VERSION ""

NS_ :

BS_:

BU_: VDM CMR_DSMC SOBDMC_HPCM_FD1 IPMA_ADAS PSCM ABS_ESC TCCM TCM_DSL PCM_HEV PCM ECM_Diesel GENERIC_GWMWakeup GWM _delete TSTR

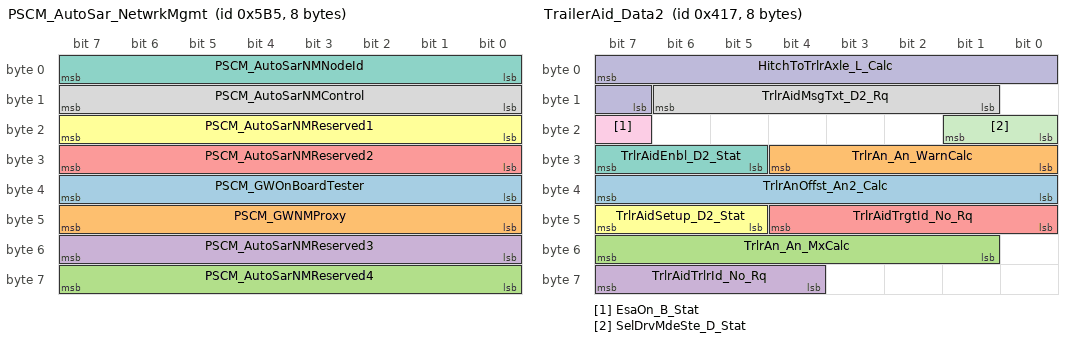
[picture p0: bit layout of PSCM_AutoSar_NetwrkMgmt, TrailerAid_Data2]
BO_ 1461 PSCM_AutoSar_NetwrkMgmt: 8 PSCM
 SG_ PSCM_GWOnBoardTester : 39|8@0+ (1,0) [0|255] "unitless"  GWM,ABS_ESC
 SG_ PSCM_GWNMProxy : 47|8@0+ (1,0) [0|255] "unitless"  GWM,ABS_ESC
 SG_ PSCM_AutoSarNMReserved4 : 63|8@0+ (1,0) [0|255] "unitless"  GWM,ABS_ESC
 SG_ PSCM_AutoSarNMReserved3 : 55|8@0+ (1,0) [0|255] "unitless"  GWM,ABS_ESC
 SG_ PSCM_AutoSarNMReserved2 : 31|8@0+ (1,0) [0|255] "unitless"  GWM,ABS_ESC
 SG_ PSCM_AutoSarNMReserved1 : 23|8@0+ (1,0) [0|255] "unitless"  GWM,ABS_ESC
 SG_ PSCM_AutoSarNMNodeId : 7|8@0+ (1,0) [0|255] "unitless"  GWM,ABS_ESC
 SG_ PSCM_AutoSarNMControl : 15|8@0+ (1,0) [0|255] "unitless"  GWM,ABS_ESC

BO_ 1047 TrailerAid_Data2: 8 PSCM
 SG_ TrlrAnOffst_An2_Calc : 39|8@0+ (0.5,-64) [-64|63.5] "degrees"  IPMA_ADAS
 SG_ TrlrAn_An_WarnCalc : 28|5@0+ (1,0) [0|31] "degrees"  IPMA_ADAS
 SG_ TrlrAn_An_MxCalc : 55|7@0+ (1,0) [0|127] "degrees"  IPMA_ADAS
 SG_ TrlrAidTrlrId_No_Rq : 63|4@0+ (1,0) [0|15] "unitless"  GWM
 SG_ TrlrAidTrgtId_No_Rq : 44|5@0+ (1,0) [0|31] "unitless"  IPMA_ADAS
 SG_ TrlrAidSetup_D2_Stat : 47|3@0+ (1,0) [0|7] "SED"  IPMA_ADAS
 SG_ TrlrAidEnbl_D2_Stat : 31|3@0+ (1,0) [0|7] "SED"  PCM_HEV,ABS_ESC,IPMA_ADAS,GWM,PCM,ECM_Diesel
 SG_ TrlrAidMsgTxt_D2_Rq : 14|6@0+ (1,0) [0|63] "SED"  IPMA_ADAS,GWM,ABS_ESC
 SG_ EsaOn_B_Stat : 23|1@0+ (1,0) [0|1] "SED"  GWM
 SG_ HitchToTrlrAxle_L_Calc : 7|9@0+ (0.0254,0) [0|12.9794] "meter"  IPMA_ADAS
 SG_ SelDrvMdeSte_D_Stat : 17|2@0+ (1,0) [0|3] "SED"  ABS_ESC

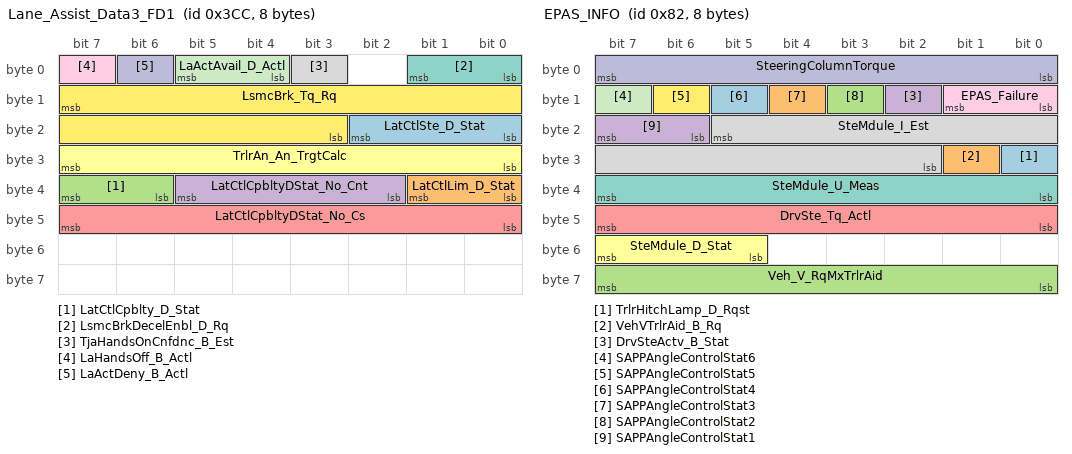
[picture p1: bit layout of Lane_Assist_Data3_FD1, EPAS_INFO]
BO_ 972 Lane_Assist_Data3_FD1: 8 PSCM
 SG_ LatCtlSte_D_Stat : 18|3@0+ (1,0) [0|7] "SED"  IPMA_ADAS,GWM
 SG_ LatCtlLim_D_Stat : 33|2@0+ (1,0) [0|3] "SED"  IPMA_ADAS,GWM
 SG_ LatCtlCpblty_D_Stat : 39|2@0+ (1,0) [0|3] "SED"  IPMA_ADAS,GWM
 SG_ LatCtlCpbltyDStat_No_Cnt : 37|4@0+ (1,0) [0|15] "Unitless"  IPMA_ADAS,GWM
 SG_ LatCtlCpbltyDStat_No_Cs : 47|8@0+ (1,0) [0|255] "Unitless"  IPMA_ADAS,GWM
 SG_ TrlrAn_An_TrgtCalc : 31|8@0+ (1,-128) [-128|127] "degrees"  IPMA_ADAS
 SG_ LsmcBrkDecelEnbl_D_Rq : 1|2@0+ (1,0) [0|3] "SED"  ABS_ESC
 SG_ TjaHandsOnCnfdnc_B_Est : 3|1@0+ (1,0) [0|1] "SED"  IPMA_ADAS
 SG_ LaHandsOff_B_Actl : 7|1@0+ (1,0) [0|1] "SED"  IPMA_ADAS,GWM
 SG_ LaActDeny_B_Actl : 6|1@0+ (1,0) [0|1] "SED"  IPMA_ADAS,GWM
 SG_ LaActAvail_D_Actl : 5|2@0+ (1,0) [0|3] "SED"  IPMA_ADAS,GWM
 SG_ LsmcBrk_Tq_Rq : 15|13@0+ (4,0) [0|32764] "Nm"  ABS_ESC

BO_ 130 EPAS_INFO: 8 PSCM
 SG_ TrlrHitchLamp_D_Rqst : 24|1@0+ (1,0) [0|1] "SED"  IPMA_ADAS,GWM
 SG_ VehVTrlrAid_B_Rq : 25|1@0+ (1,0) [0|1] "SED"  PCM_HEV,GWM,ECM_Diesel,PCM
 SG_ Veh_V_RqMxTrlrAid : 63|8@0+ (0.1,0) [0|25.5] "km/h"  PCM_HEV,GWM,ECM_Diesel,PCM
 SG_ DrvSteActv_B_Stat : 10|1@0+ (1,0) [0|1] "SED"  GWM,ABS_ESC
 SG_ DrvSte_Tq_Actl : 47|8@0+ (0.0625,-8) [-8|7.8125] "Nm"  GWM,ABS_ESC
 SG_ SteMdule_D_Stat : 55|3@0+ (1,0) [0|7] "SED"  GWM
 SG_ SteMdule_U_Meas : 39|8@0+ (0.05,6) [6|18.7] "Volts"  GWM
 SG_ SteMdule_I_Est : 21|12@0+ (0.05,-64) [-64|140.7] "Amps"  GWM
 SG_ EPAS_Failure : 9|2@0+ (1,0) [0|3] "SED"  IPMA_ADAS,GWM
 SG_ SteeringColumnTorque : 7|8@0+ (0.0625,-8) [-8|7.8125] "Nm"  GWM,IPMA_ADAS,ABS_ESC
 SG_ SAPPAngleControlStat6 : 15|1@0+ (1,0) [0|1] "SED"  GWM,IPMA_ADAS
 SG_ SAPPAngleControlStat5 : 14|1@0+ (1,0) [0|1] "SED"  GWM,IPMA_ADAS
 SG_ SAPPAngleControlStat4 : 13|1@0+ (1,0) [0|1] "SED"  GWM,IPMA_ADAS
 SG_ SAPPAngleControlStat3 : 12|1@0+ (1,0) [0|1] "SED"  GWM,IPMA_ADAS
 SG_ SAPPAngleControlStat2 : 11|1@0+ (1,0) [0|1] "SED"  GWM,IPMA_ADAS
 SG_ SAPPAngleControlStat1 : 23|2@0+ (1,0) [0|3] "SED"  GWM,IPMA_ADAS

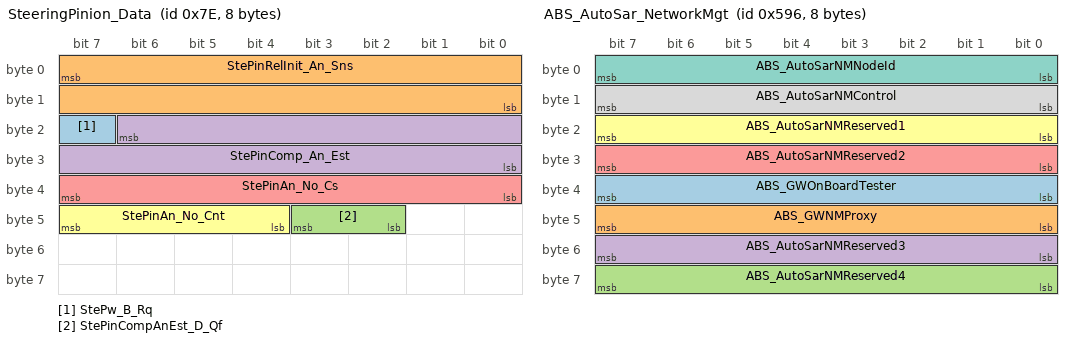
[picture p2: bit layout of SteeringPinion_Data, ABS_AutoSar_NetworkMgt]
BO_ 126 SteeringPinion_Data: 8 PSCM
 SG_ StePw_B_Rq : 23|1@0+ (1,0) [0|1] "SED"  GWM,ECM_Diesel,PCM
 SG_ StePinRelInit_An_Sns : 7|16@0+ (0.1,-3200) [-3200|3353.3] "degrees"  VDM,IPMA_ADAS,GWM,ECM_Diesel,PCM,PCM_HEV,ABS_ESC,TCCM
 SG_ StePinCompAnEst_D_Qf : 43|2@0+ (1,0) [0|3] "SED"  VDM,CMR_DSMC,IPMA_ADAS,TCM_DSL,ECM_Diesel,PCM,PCM_HEV,ABS_ESC,TCCM,GWM
 SG_ StePinComp_An_Est : 22|15@0+ (0.1,-1600) [-1600|1676.7] "degrees"  VDM,CMR_DSMC,IPMA_ADAS,TCM_DSL,ECM_Diesel,PCM,PCM_HEV,ABS_ESC,TCCM,GWM
 SG_ StePinAn_No_Cs : 39|8@0+ (1,0) [0|255] "Unitless"  VDM,ABS_ESC,TCCM,GWM
 SG_ StePinAn_No_Cnt : 47|4@0+ (1,0) [0|15] "unitless"  VDM,TCCM,GWM,ABS_ESC

BO_ 1430 ABS_AutoSar_NetworkMgt: 8 ABS_ESC
 SG_ ABS_GWOnBoardTester : 39|8@0+ (1,0) [0|255] "unitless"  GWM
 SG_ ABS_GWNMProxy : 47|8@0+ (1,0) [0|255] "unitless"  GWM
 SG_ ABS_AutoSarNMReserved4 : 63|8@0+ (1,0) [0|255] "unitless"  GWM
 SG_ ABS_AutoSarNMReserved3 : 55|8@0+ (1,0) [0|255] "unitless"  GWM
 SG_ ABS_AutoSarNMReserved2 : 31|8@0+ (1,0) [0|255] "unitless"  GWM
 SG_ ABS_AutoSarNMReserved1 : 23|8@0+ (1,0) [0|255] "unitless"  GWM
 SG_ ABS_AutoSarNMNodeId : 7|8@0+ (1,0) [0|255] "unitless"  GWM
 SG_ ABS_AutoSarNMControl : 15|8@0+ (1,0) [0|255] "unitless"  GWM

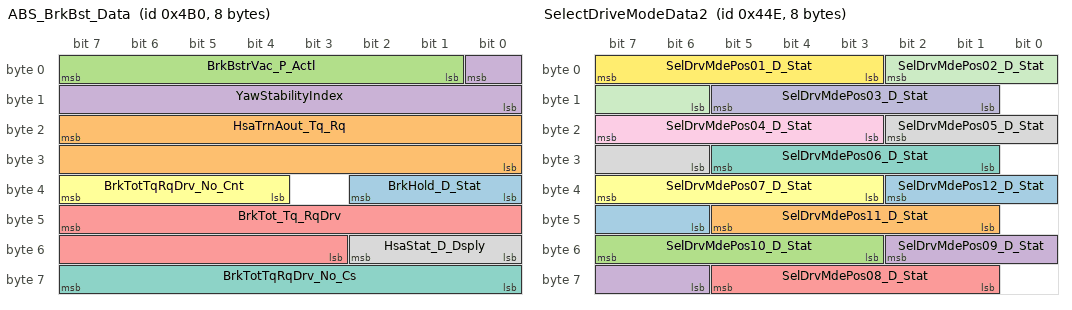
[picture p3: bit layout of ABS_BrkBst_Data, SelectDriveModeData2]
BO_ 1200 ABS_BrkBst_Data: 8 ABS_ESC
 SG_ BrkHold_D_Stat : 34|3@0+ (1,0) [0|7] "SED"  ECM_Diesel,GWM,IPMA_ADAS,PCM,PCM_HEV
 SG_ HsaTrnAout_Tq_Rq : 23|16@0+ (4,-131072) [-131072|131060] "Nm"  GWM
 SG_ BrkBstrVac_P_Actl : 7|7@0+ (8,0) [0|1008] "Millibar"  ECM_Diesel,PCM,PCM_HEV,GWM
 SG_ YawStabilityIndex : 0|9@0+ (1,-256) [-256|255] "%"  VDM,IPMA_ADAS,PSCM,GWM
 SG_ BrkTot_Tq_RqDrv : 47|13@0+ (4,0) [0|32760] "Nm"  IPMA_ADAS,ECM_Diesel,PCM,PCM_HEV,GWM,TCCM,PSCM
 SG_ BrkTotTqRqDrv_No_Cnt : 39|4@0+ (1,0) [0|15] "unitless"  ECM_Diesel,PCM,PCM_HEV,GWM
 SG_ BrkTotTqRqDrv_No_Cs : 63|8@0+ (1,0) [0|255] "unitless"  ECM_Diesel,PCM,PCM_HEV,GWM
 SG_ HsaStat_D_Dsply : 50|3@0+ (1,0) [0|7] "SED"  GWM

BO_ 1102 SelectDriveModeData2: 8 ABS_ESC
 SG_ SelDrvMdePos12_D_Stat : 34|5@0+ (1,0) [0|31] "SED"  GWM
 SG_ SelDrvMdePos11_D_Stat : 45|5@0+ (1,0) [0|31] "SED"  GWM
 SG_ SelDrvMdePos10_D_Stat : 55|5@0+ (1,0) [0|31] "SED"  GWM
 SG_ SelDrvMdePos09_D_Stat : 50|5@0+ (1,0) [0|31] "SED"  GWM
 SG_ SelDrvMdePos08_D_Stat : 61|5@0+ (1,0) [0|31] "SED"  GWM
 SG_ SelDrvMdePos07_D_Stat : 39|5@0+ (1,0) [0|31] "SED"  GWM
 SG_ SelDrvMdePos06_D_Stat : 29|5@0+ (1,0) [0|31] "SED"  GWM
 SG_ SelDrvMdePos05_D_Stat : 18|5@0+ (1,0) [0|31] "SED"  GWM
 SG_ SelDrvMdePos04_D_Stat : 23|5@0+ (1,0) [0|31] "SED"  GWM
 SG_ SelDrvMdePos03_D_Stat : 13|5@0+ (1,0) [0|31] "SED"  GWM
 SG_ SelDrvMdePos02_D_Stat : 2|5@0+ (1,0) [0|31] "SED"  GWM
 SG_ SelDrvMdePos01_D_Stat : 7|5@0+ (1,0) [0|31] "SED"  GWM

BO_ 1056 SelectDriveModeData: 8 ABS_ESC
 SG_ SelDrvMdeHmi03_D_Rq : 12|5@0+ (1,0) [0|31] "SED"  GWM
 SG_ AutoEpbMsgTxt_D_Rq : 58|3@0+ (1,0) [0|7] "SED"  GWM
 SG_ AutoEpbDsply_D_Stat : 37|2@0+ (1,0) [0|3] "SED"  GWM
 SG_ AutoEpbButtnOn_B_Stat : 48|1@0+ (1,0) [0|1] "SED"  GWM
 SG_ SelDrvMdePos12_B_Avail : 54|1@0+ (1,0) [0|1] "SED"  GWM
 SG_ SelDrvMdePos11_B_Avail : 55|1@0+ (1,0) [0|1] "SED"  GWM
 SG_ SelDrvMdePos10_B_Avail : 40|1@0+ (1,0) [0|1] "SED"  GWM
 SG_ SelDrvMdePos09_B_Avail : 41|1@0+ (1,0) [0|1] "SED"  GWM
 SG_ SelDrvMdePos08_B_Avail : 42|1@0+ (1,0) [0|1] "SED"  GWM
 SG_ SelDrvMdePos07_B_Avail : 43|1@0+ (1,0) [0|1] "SED"  GWM
 SG_ SelDrvMdePos06_B_Avail : 44|1@0+ (1,0) [0|1] "SED"  GWM
 SG_ SelDrvMdePos05_B_Avail : 45|1@0+ (1,0) [0|1] "SED"  GWM
 SG_ SelDrvMdePos04_B_Avail : 46|1@0+ (1,0) [0|1] "SED"  GWM
 SG_ SelDrvMdePos03_B_Avail : 47|1@0+ (1,0) [0|1] "SED"  GWM
 SG_ SelDrvMdePos02_B_Avail : 32|1@0+ (1,0) [0|1] "SED"  GWM
 SG_ SelDrvMdePos01_B_Avail : 24|1@0+ (1,0) [0|1] "SED"  GWM
 SG_ ActvDrvMde_D2_Stat : 53|5@0+ (1,0) [0|31] "SED"  IPMA_ADAS,GWM
 SG_ SelDrvMde_D2_Rq : 63|5@0+ (1,0) [0|31] "SED"  GWM
 SG_ SelDrvMdePt_D_Rq : 31|5@0+ (1,0) [0|31] "SED"  ECM_Diesel,PCM,PCM_HEV,GWM
 SG_ SelDrvMdeMsgTxt_D_Rq : 19|4@0+ (1,0) [0|15] "SED"  TCCM,GWM
 SG_ SelDrvMde_D_Stat : 26|2@0+ (1,0) [0|3] "SED"  GWM
 SG_ AwdMde_D_RqBrk : 35|3@0+ (1,0) [0|7] "SED"  GWM

BO_ 1054 BrakeSysFeatures_3: 8 ABS_ESC
 SG_ TrailOnePdlTqLm_B_Actl : 56|1@0+ (1,0) [0|1] "SED"  PCM,GWM
 SG_ SelDrvMdeChassis3_D_Rq : 61|5@0+ (1,0) [0|31] "SED"  GWM
 SG_ AirDamUp_B_RqBrk : 32|1@0+ (1,0) [0|1] "SED"  ECM_Diesel,PCM_HEV,PCM
 SG_ RbaBrk_D_Stat : 63|2@0+ (1,0) [0|3] "SED"  IPMA_ADAS,GWM
 SG_ SelDrvMdeChassis2_D_Rq : 45|5@0+ (1,0) [0|31] "SED"  PSCM,GWM
 SG_ TrailCtl_D_Stat : 55|3@0+ (1,0) [0|7] "SED"  TCCM,PCM,GWM
 SG_ TrailCtlMsgTxt_D_Rq : 52|4@0+ (1,0) [0|15] "SED"  GWM
 SG_ BrkBstrVac_D_Stat : 18|2@0+ (1,0) [0|3] "SED"  ECM_Diesel,PCM,PCM_HEV,GWM
 SG_ DrvSlipCtlOffLamp_D_Rq : 23|2@0+ (1,0) [0|3] "SED"  GWM
 SG_ DrvSlipCtlMdeMsg_D_Rq : 13|5@0+ (1,0) [0|31] "SED"  GWM
 SG_ AutoHoldMsgTxt_D_Rq : 4|4@0+ (1,0) [0|15] "SED"  GWM
 SG_ CtaBrk_D_Stat : 47|2@0+ (1,0) [0|3] "SED"  IPMA_ADAS,GWM
 SG_ SelDrvMdeAwd_D_Rq : 29|5@0+ (1,0) [0|31] "SED"  TCCM,GWM
 SG_ AutoHoldSwMde_B_Ind : 0|1@0+ (1,0) [0|1] "SED"  GWM
 SG_ AutoHoldMde_D_Ind : 15|2@0+ (1,0) [0|3] "SED"  GWM
 SG_ SelDrvMdeChassis_D_Rq : 39|5@0+ (1,0) [0|31] "SED"  VDM,GWM
 SG_ ApaBrk_D_Stat : 34|2@0+ (1,0) [0|3] "SED"  ECM_Diesel,IPMA_ADAS,PCM,PCM_HEV,GWM

BO_ 1046 BrakeSysFeatures_2: 8 ABS_ESC
 SG_ HsaMde_D_Mem : 33|2@0+ (1,0) [0|3] "SED"  GWM
 SG_ BrkBstrVac_B_Rq : 27|1@0+ (1,0) [0|1] "Discrete"  ECM_Diesel,PCM,PCM_HEV,GWM
 SG_ HdcMde_D_Actl : 31|3@0+ (1,0) [0|7] "SED"  PCM,PCM_HEV,GWM
 SG_ RearDiffLck_Tq2_RqMx : 51|12@0+ (4,0) [0|16376] "Nm"  GWM
 SG_ TRLR_SWAY_EVNT_IN_PROG : 25|1@0+ (1,0) [0|1] "SED"  GWM
 SG_ TRLR_SWAY_CONFIG_STAT : 26|1@0+ (1,0) [0|1] "SED"  GWM
 SG_ TCMode : 15|1@0+ (1,0) [0|1] "SED"  VDM,IPMA_ADAS,ECM_Diesel,PCM,PCM_HEV,GWM
 SG_ DrvSlipCtlLamp_D_Rq : 42|2@0+ (1,0) [0|3] "SED"  VDM,IPMA_ADAS,ECM_Diesel,PCM,PCM_HEV,GWM
 SG_ Abs_B_Falt : 5|1@0+ (1,0) [0|1] "SED"  ECM_Diesel,PCM,PCM_HEV,GWM
 SG_ DrvSlipCtlMde_D_Ind : 44|2@0+ (1,0) [0|3] "SED"  TCCM,IPMA_ADAS,ECM_Diesel,PCM,PCM_HEV,GWM
 SG_ DrvAntiLckLamp_D_Rq : 55|2@0+ (1,0) [0|3] "SED"  ECM_Diesel,GWM,IPMA_ADAS
 SG_ BpedMove_No_Cnt : 3|4@0+ (1,0) [0|15] "Unitless"  ECM_Diesel,GWM
 SG_ StabCtlBrk_B_Avail : 4|1@0+ (1,0) [0|1] "SED"  VDM,TCCM,GWM
 SG_ DrvHdcWarnInfo_D_Rq : 35|2@0+ (1,0) [0|3] "SED"  GWM
 SG_ DrvHdcMsg_D_Rq : 10|3@0+ (1,0) [0|7] "SED"  GWM
 SG_ DrvHdcLampInfo_D_Rq : 12|2@0+ (1,0) [0|3] "SED"  GWM
 SG_ BpedMove_D_Actl : 7|2@0+ (1,0) [0|3] "SED"  ECM_Diesel,GWM
 SG_ ChimeBrk_B_Rq : 14|1@0+ (1,0) [0|1] "SED"  GWM
 SG_ BrkLamp_B_Rq : 13|1@0+ (1,0) [0|1] "SED"  GWM
 SG_ HILL_DESC_MC : 47|3@0+ (1,0) [0|7] "SED"  GWM
 SG_ RearDiffElckrOpen_B_Rq : 40|1@0+ (1,0) [0|1] "SED"  GWM,TCCM

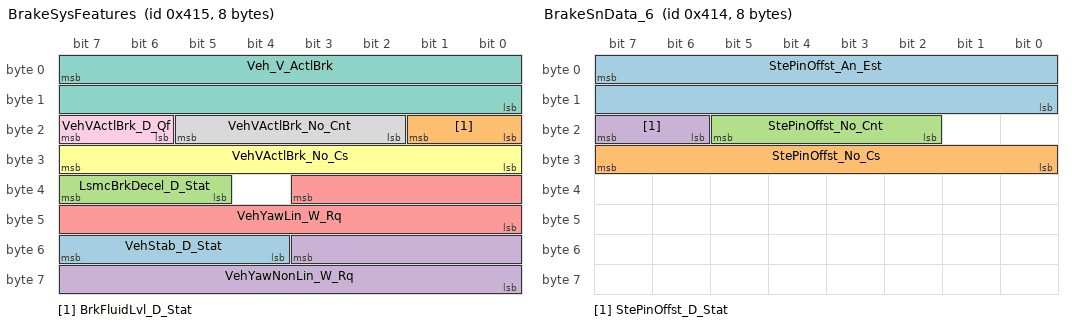
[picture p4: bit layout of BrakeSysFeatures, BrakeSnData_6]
BO_ 1045 BrakeSysFeatures: 8 ABS_ESC
 SG_ VehStab_D_Stat : 55|4@0+ (1,0) [0|15] "SED"  TCCM,PCM_HEV,PCM,GWM
 SG_ BrkFluidLvl_D_Stat : 17|2@0+ (1,0) [0|3] "SED"  GWM
 SG_ LsmcBrkDecel_D_Stat : 39|3@0+ (1,0) [0|7] "SED"  PSCM,GWM
 SG_ VehYawNonLin_W_Rq : 51|12@0+ (0.03663,-75) [-75|74.92659] "deg/s"  ECM_Diesel,GWM
 SG_ VehYawLin_W_Rq : 35|12@0+ (0.03663,-75) [-75|74.92659] "deg/s"  ECM_Diesel,GWM
 SG_ VehVActlBrk_No_Cs : 31|8@0+ (1,0) [0|255] "Unitless"  TCCM,CMR_DSMC,SOBDMC_HPCM_FD1,ECM_Diesel,PCM,PCM_HEV,PSCM,TCM_DSL,GWM,IPMA_ADAS
 SG_ Veh_V_ActlBrk : 7|16@0+ (0.01,0) [0|655.35] "kph"  TCCM,CMR_DSMC,SOBDMC_HPCM_FD1,IPMA_ADAS,ECM_Diesel,PCM,PCM_HEV,PSCM,TCM_DSL,GWM
 SG_ VehVActlBrk_No_Cnt : 21|4@0+ (1,0) [0|15] "Unitless"  TCCM,CMR_DSMC,SOBDMC_HPCM_FD1,ECM_Diesel,PCM,PCM_HEV,PSCM,TCM_DSL,GWM,IPMA_ADAS
 SG_ VehVActlBrk_D_Qf : 23|2@0+ (1,0) [0|3] "SED"  TCCM,CMR_DSMC,SOBDMC_HPCM_FD1,IPMA_ADAS,ECM_Diesel,PCM,PCM_HEV,PSCM,TCM_DSL,GWM

BO_ 1044 BrakeSnData_6: 8 ABS_ESC
 SG_ StePinOffst_An_Est : 7|16@0+ (0.1,-3200) [-3200|3353.3] "degrees"  GWM,PSCM
 SG_ StePinOffst_No_Cs : 31|8@0+ (1,0) [0|255] "Unitless"  GWM,PSCM
 SG_ StePinOffst_No_Cnt : 21|4@0+ (1,0) [0|15] "unitless"  GWM,PSCM
 SG_ StePinOffst_D_Stat : 23|2@0+ (1,0) [0|3] "SED"  GWM,PSCM

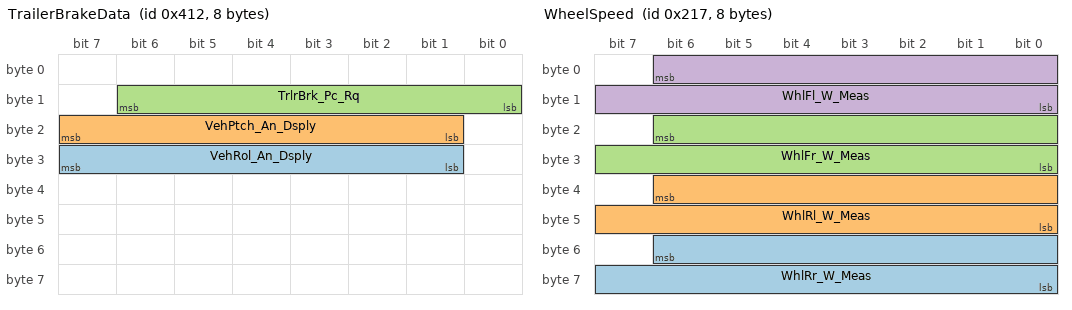
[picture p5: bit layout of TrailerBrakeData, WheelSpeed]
BO_ 1042 TrailerBrakeData: 8 ABS_ESC
 SG_ VehRol_An_Dsply : 31|7@0+ (1,-64) [-64|61] "degrees"  GWM
 SG_ VehPtch_An_Dsply : 23|7@0+ (1,-64) [-64|61] "degrees"  GWM,TCCM
 SG_ TrlrBrk_Pc_Rq : 14|7@0+ (1,0) [0|127] "percent"  GWM

BO_ 535 WheelSpeed: 8 ABS_ESC
 SG_ WhlRr_W_Meas : 54|15@0+ (0.01,0) [0|327.65] "rad/s"  VDM,IPMA_ADAS,GWM,ECM_Diesel,PCM,PCM_HEV,PSCM,TCCM,TCM_DSL
 SG_ WhlRl_W_Meas : 38|15@0+ (0.01,0) [0|327.65] "rad/s"  VDM,IPMA_ADAS,GWM,ECM_Diesel,PCM,PCM_HEV,PSCM,TCCM,TCM_DSL
 SG_ WhlFr_W_Meas : 22|15@0+ (0.01,0) [0|327.65] "rad/s"  VDM,IPMA_ADAS,GWM,ECM_Diesel,PCM,PCM_HEV,PSCM,TCCM,TCM_DSL
 SG_ WhlFl_W_Meas : 6|15@0+ (0.01,0) [0|327.65] "rad/s"  VDM,IPMA_ADAS,GWM,ECM_Diesel,PCM,PCM_HEV,PSCM,TCCM,TCM_DSL

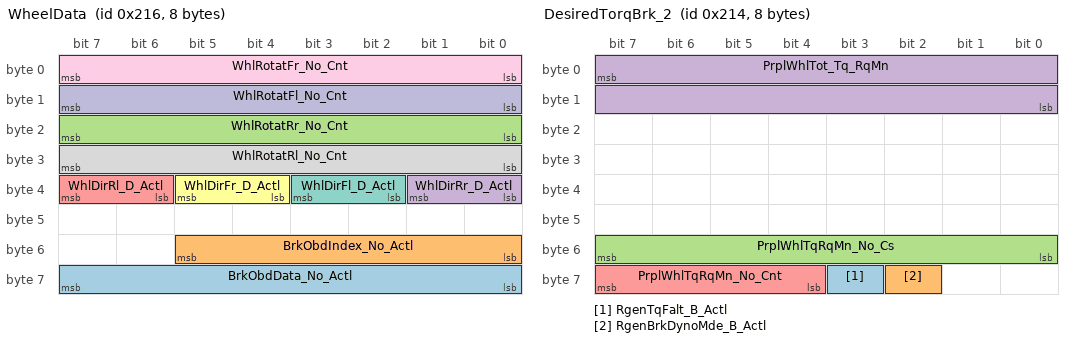
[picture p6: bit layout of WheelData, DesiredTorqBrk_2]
BO_ 534 WheelData: 8 ABS_ESC
 SG_ BrkObdData_No_Actl : 63|8@0+ (1,0) [0|255] "unitless"  SOBDMC_HPCM_FD1,GWM
 SG_ BrkObdIndex_No_Actl : 53|6@0+ (1,0) [0|63] "unitless"  SOBDMC_HPCM_FD1,GWM
 SG_ WhlRotatRr_No_Cnt : 23|8@0+ (1,0) [0|255] "Unitless"  IPMA_ADAS,GWM,PSCM
 SG_ WhlDirRr_D_Actl : 33|2@0+ (1,0) [0|3] "SED"  PCM,IPMA_ADAS,GWM,ECM_Diesel,PCM_HEV,PSCM
 SG_ WhlDirRl_D_Actl : 39|2@0+ (1,0) [0|3] "SED"  PCM,IPMA_ADAS,GWM,PSCM,ECM_Diesel,PCM_HEV
 SG_ WhlDirFr_D_Actl : 37|2@0+ (1,0) [0|3] "SED"  PCM,IPMA_ADAS,GWM,ECM_Diesel,PCM_HEV,PSCM
 SG_ WhlDirFl_D_Actl : 35|2@0+ (1,0) [0|3] "SED"  PCM,IPMA_ADAS,GWM,ECM_Diesel,PCM_HEV,PSCM
 SG_ WhlRotatRl_No_Cnt : 31|8@0+ (1,0) [0|255] "Unitless"  IPMA_ADAS,GWM,PSCM
 SG_ WhlRotatFr_No_Cnt : 7|8@0+ (1,0) [0|255] "Unitless"  IPMA_ADAS,GWM,PSCM
 SG_ WhlRotatFl_No_Cnt : 15|8@0+ (1,0) [0|255] "Unitless"  IPMA_ADAS,GWM,PSCM

BO_ 532 DesiredTorqBrk_2: 8 ABS_ESC
 SG_ RgenTqFalt_B_Actl : 59|1@0+ (1,0) [0|1] "SED"  GWM,PCM_HEV
 SG_ RgenBrkDynoMde_B_Actl : 58|1@0+ (1,0) [0|1] "SED"  GWM,PCM_HEV
 SG_ PrplWhlTqRqMn_No_Cs : 55|8@0+ (1,0) [0|255] "Unitless"  GWM,ECM_Diesel,PCM,PCM_HEV
 SG_ PrplWhlTot_Tq_RqMn : 7|16@0+ (4,-131072) [-131072|131068] "Nm"  GWM,ECM_Diesel,PCM,PCM_HEV
 SG_ PrplWhlTqRqMn_No_Cnt : 63|4@0+ (1,0) [0|15] "Unitless"  GWM,ECM_Diesel,PCM,PCM_HEV

BO_ 531 DesiredTorqBrk: 8 ABS_ESC
 SG_ VehStop_D_Stat : 28|2@0+ (1,0) [0|3] "SED"  IPMA_ADAS,GWM
 SG_ TracCtlPtActv_B_Actl : 31|1@0+ (1,0) [0|1] "SED"  VDM,IPMA_ADAS,TCCM,ECM_Diesel,PCM,PCM_HEV,TCM_DSL,GWM
 SG_ LscmbbMntr_B_Err : 17|1@0+ (1,0) [0|1] "SED"  GWM
 SG_ LscmbbBrkDis_B_Actl : 19|1@0+ (1,0) [0|1] "SED"  GWM
 SG_ LscmbbDeny_B_ActlBrk : 18|1@0+ (1,0) [0|1] "SED"  GWM
 SG_ PrkBrkYwLamp_D_Rq : 38|2@0+ (1,0) [0|3] "SED"  GWM
 SG_ PrkBrkRedLamp_D_Rq : 30|2@0+ (1,0) [0|3] "SED"  GWM
 SG_ LscmbbBrkDecel_B_Actl : 20|1@0+ (1,0) [0|1] "SED"  GWM
 SG_ AbsActv_B_Actl : 45|1@0+ (1,0) [0|1] "SED"  VDM,SOBDMC_HPCM_FD1,IPMA_ADAS,ECM_Diesel,PCM,PCM_HEV,TCM_DSL,PSCM,GWM
 SG_ StabCtlBrkActv_B_Actl : 23|1@0+ (1,0) [0|1] "SED"  VDM,IPMA_ADAS,PCM,PCM_HEV,TCM_DSL,PSCM,TCCM,ECM_Diesel,GWM
 SG_ CmbbBrkPrchg_B_Actl : 59|1@0+ (1,0) [0|1] "SED"  IPMA_ADAS,GWM
 SG_ CmbbBrkDecel_B_Actl : 58|1@0+ (1,0) [0|1] "SED"  IPMA_ADAS,GWM
 SG_ CmbbBaSensInc_B_Actl : 57|1@0+ (1,0) [0|1] "SED"  IPMA_ADAS,GWM
 SG_ AccBrkWarm_B_Actl : 63|1@0+ (1,0) [0|1] "SED"  IPMA_ADAS,GWM
 SG_ AccBrkTotTqMn_B_Actl : 62|1@0+ (1,0) [0|1] "SED"  IPMA_ADAS,GWM
 SG_ AccBrkPrchgActv_B_Actl : 61|1@0+ (1,0) [0|1] "SED"  IPMA_ADAS,GWM
 SG_ AccBrkDis_B_Actl : 44|1@0+ (1,0) [0|1] "SED"  IPMA_ADAS,GWM
 SG_ AccBrkDeny_B_Actl : 42|1@0+ (1,0) [0|1] "SED"  IPMA_ADAS,ECM_Diesel,PCM,PCM_HEV,GWM
 SG_ AccBrkActv_B_Actl : 43|1@0+ (1,0) [0|1] "SED"  IPMA_ADAS,ECM_Diesel,GWM
 SG_ PrplDrgCtlActv_B_Actl : 46|1@0+ (1,0) [0|1] "SED"  ECM_Diesel,PCM,PCM_HEV,TCM_DSL,GWM
 SG_ PrplWhlTot_Tq_RqMx : 7|16@0+ (4,-131072) [-131072|131068] "Nm"  ECM_Diesel,PCM,PCM_HEV,TCCM,GWM
 SG_ LscmbbBaSensInc_B_Actl : 21|1@0+ (1,0) [0|1] "SED"  GWM
 SG_ CmbbBrkDis_B_Actl : 56|1@0+ (1,0) [0|1] "SED"  IPMA_ADAS,PSCM,GWM
 SG_ CmbbDeny_B_ActlBrk : 60|1@0+ (1,0) [0|1] "SED"  IPMA_ADAS,PSCM,ECM_Diesel,PCM,PCM_HEV,GWM
 SG_ CcDis_B_Cmd : 47|1@0+ (1,0) [0|1] "SED"  PCM,PCM_HEV,GWM
 SG_ VehLongOvrGnd_A_Est : 41|10@0+ (0.035,-17.9) [-17.9|17.835] "m/s^2"  VDM,IPMA_ADAS,TCCM,GWM
 SG_ LscmbBrkPrchg_B_Actl : 16|1@0+ (1,0) [0|1] "SED"  GWM
 SG_ AccStopActv_B_ActlBrk : 22|1@0+ (1,0) [0|1] "SED"  IPMA_ADAS,ECM_Diesel,PCM,PCM_HEV,GWM
 SG_ AccDis_B_ActlEpb : 32|1@0+ (1,0) [0|1] "SED"  IPMA_ADAS,GWM
 SG_ PrkBrkMsgTxt_D_Rq : 36|4@0+ (1,0) [0|15] "SED"  GWM
 SG_ PrkBrkStatus : 26|3@0+ (1,0) [0|7] "SED"  IPMA_ADAS,ECM_Diesel,PCM,PCM_HEV,TCM_DSL,GWM

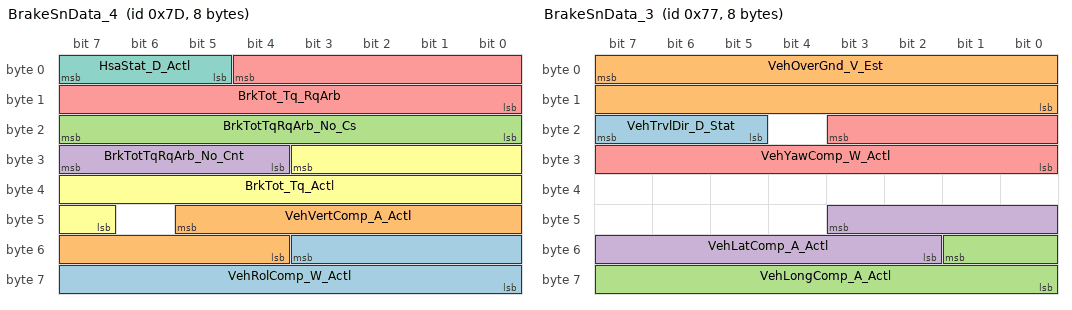
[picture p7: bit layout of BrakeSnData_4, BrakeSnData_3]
BO_ 125 BrakeSnData_4: 8 ABS_ESC
 SG_ VehRolComp_W_Actl : 51|12@0+ (0.03663,-75) [-75|74.92659] "degrees/sec"  VDM,GWM
 SG_ VehVertComp_A_Actl : 45|10@0+ (0.035,-17.9) [-17.9|17.835] "m/s^2"  VDM,PSCM,GWM
 SG_ BrkTotTqRqArb_No_Cs : 23|8@0+ (1,0) [0|255] "Unitless"  ECM_Diesel,PCM,PCM_HEV,GWM
 SG_ BrkTotTqRqArb_No_Cnt : 31|4@0+ (1,0) [0|15] "Unitless"  ECM_Diesel,PCM,PCM_HEV,GWM
 SG_ BrkTot_Tq_RqArb : 4|13@0+ (4,0) [0|32756] "Nm"  VDM,IPMA_ADAS,ECM_Diesel,PCM,PCM_HEV,TCM_DSL,PSCM,GWM
 SG_ BrkTot_Tq_Actl : 27|13@0+ (4,0) [0|32756] "Nm"  ECM_Diesel,PCM,PCM_HEV,PSCM,GWM,TCCM
 SG_ HsaStat_D_Actl : 7|3@0+ (1,0) [0|7] "SED"  ECM_Diesel,PCM,PCM_HEV,TCM_DSL,GWM

BO_ 119 BrakeSnData_3: 8 ABS_ESC
 SG_ VehTrvlDir_D_Stat : 23|3@0+ (1,0) [0|7] "SED"  GWM
 SG_ VehOverGnd_V_Est : 7|16@0+ (0.01,0) [0|655.33] "kph"  VDM,IPMA_ADAS,TCCM,PSCM,GWM
 SG_ VehLongComp_A_Actl : 49|10@0+ (0.035,-17.9) [-17.9|17.835] "m/s^2"  VDM,ECM_Diesel,PCM,PCM_HEV,TCM_DSL,PSCM,GWM
 SG_ VehLatComp_A_Actl : 43|10@0+ (0.035,-17.9) [-17.9|17.835] "m/s^2"  VDM,ECM_Diesel,PCM,PCM_HEV,TCM_DSL,PSCM,TCCM,GWM
 SG_ VehYawComp_W_Actl : 19|12@0+ (0.03663,-75) [-75|74.92659] "deg/s"  VDM,TCCM,IPMA_ADAS,ECM_Diesel,PCM,PCM_HEV,TCM_DSL,PSCM,GWM

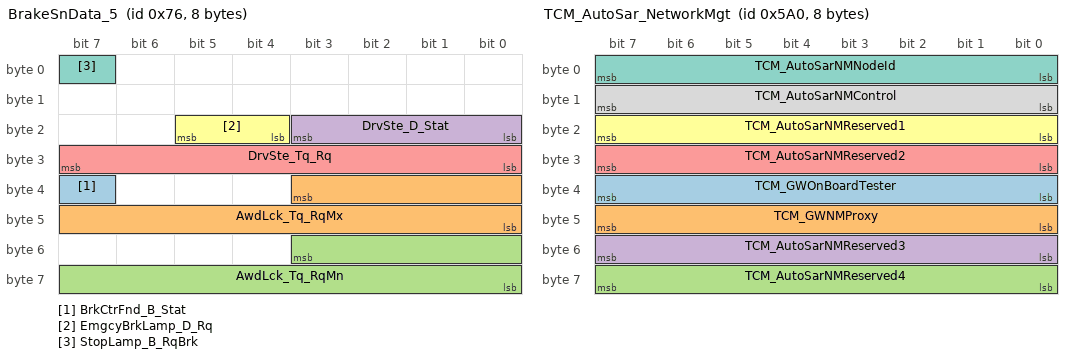
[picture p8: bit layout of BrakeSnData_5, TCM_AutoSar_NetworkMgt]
BO_ 118 BrakeSnData_5: 8 ABS_ESC
 SG_ BrkCtrFnd_B_Stat : 39|1@0+ (1,0) [0|1] "SED"  GWM
 SG_ AwdLck_Tq_RqMx : 35|12@0+ (1,0) [0|4095] "Nm"  GWM,TCCM
 SG_ AwdLck_Tq_RqMn : 51|12@0+ (1,0) [0|4095] "Nm"  GWM,TCCM
 SG_ DrvSte_D_Stat : 19|4@0+ (1,0) [0|15] "SED"  PSCM,GWM
 SG_ DrvSte_Tq_Rq : 31|8@0+ (0.0625,-8) [-8|7.8125] "Nm"  PSCM,GWM
 SG_ EmgcyBrkLamp_D_Rq : 21|2@0+ (1,0) [0|3] "SED"  GWM
 SG_ StopLamp_B_RqBrk : 7|1@0+ (1,0) [0|1] "SED"  GWM

BO_ 73 Global_PATS_SubTarget: 8 ABS_ESC
 SG_ immoSubTarget1Data_T1 : 15|40@0+ (1,0) [0|1099511627775] "Encrypted"  ECM_Diesel,GWM,PCM,PCM_HEV
 SG_ immoSubTarget1Cmd_T1 : 7|3@0+ (1,0) [0|7] "SED"  ECM_Diesel,GWM,PCM,PCM_HEV

BO_ 1034 GGCC_Config_Mgmt_ID_1_FD1: 8 GWM
 SG_ VehicleGGCCData : 7|64@0+ (1,0) [0|1.84467E+019] "mixed"  VDM,CMR_DSMC,SOBDMC_HPCM_FD1,IPMA_ADAS,ABS_ESC,ECM_Diesel,PCM,PCM_HEV,PSCM,TCCM,TCM_DSL

BO_ 1440 TCM_AutoSar_NetworkMgt: 8 TCM_DSL
 SG_ TCM_GWOnBoardTester : 39|8@0+ (1,0) [0|255] "unitless" Vector__XXX
 SG_ TCM_GWNMProxy : 47|8@0+ (1,0) [0|255] "unitless" Vector__XXX
 SG_ TCM_AutoSarNMReserved4 : 63|8@0+ (1,0) [0|255] "unitless" Vector__XXX
 SG_ TCM_AutoSarNMReserved3 : 55|8@0+ (1,0) [0|255] "unitless" Vector__XXX
 SG_ TCM_AutoSarNMReserved2 : 31|8@0+ (1,0) [0|255] "unitless" Vector__XXX
 SG_ TCM_AutoSarNMReserved1 : 23|8@0+ (1,0) [0|255] "unitless" Vector__XXX
 SG_ TCM_AutoSarNMNodeId : 7|8@0+ (1,0) [0|255] "unitless" Vector__XXX
 SG_ TCM_AutoSarNMControl : 15|8@0+ (1,0) [0|255] "unitless" Vector__XXX

BO_ 561 TransGearData_2: 8 TCM_DSL
 SG_ TrnMsgTxt2_D_Rq : 39|3@0+ (1,0) [0|7] "SED"  GWM
 SG_ TrnMsgTxt_D_Rq : 23|4@0+ (1,0) [0|15] "SED"  GWM

BO_ 330 TransData_3: 8 TCM_DSL
 SG_ TrnAout_W_ActlUnfilt : 22|15@0+ (0.1,0) [0|3276.5] "rad/s"  ECM_Diesel,GWM

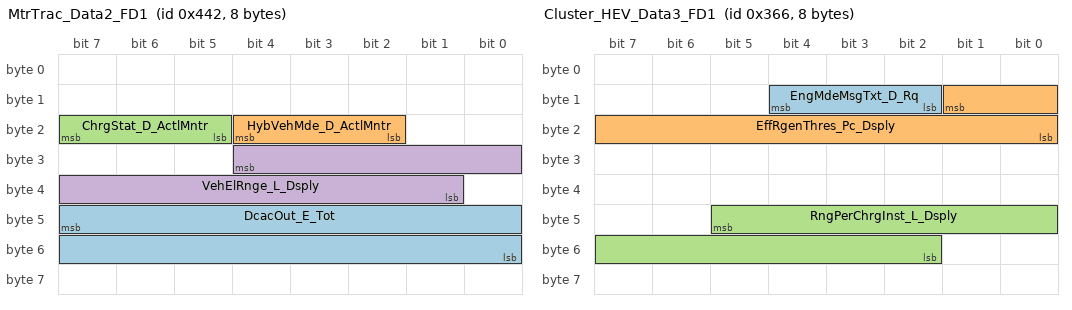
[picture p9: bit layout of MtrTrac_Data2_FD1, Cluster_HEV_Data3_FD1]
BO_ 1090 MtrTrac_Data2_FD1: 8 PCM_HEV
 SG_ DcacOut_E_Tot : 47|16@0+ (20,0) [0|1310700] "watthour"  GWM
 SG_ HybVehMde_D_ActlMntr : 20|3@0+ (1,0) [0|7] "SED"  GWM
 SG_ ChrgStat_D_ActlMntr : 23|3@0+ (1,0) [0|7] "SED"  GWM
 SG_ VehElRnge_L_Dsply : 28|12@0+ (0.1,0) [0|409.3] "kilometer"  GWM

BO_ 870 Cluster_HEV_Data3_FD1: 8 PCM_HEV
 SG_ EngMdeMsgTxt_D_Rq : 12|3@0+ (1,0) [0|7] "SED"  GWM
 SG_ EffRgenThres_Pc_Dsply : 9|10@0+ (0.1,-102.3) [-102.3|0] "percent"  GWM
 SG_ RngPerChrgInst_L_Dsply : 45|12@0+ (0.1,0) [0|409.3] "km"  GWM

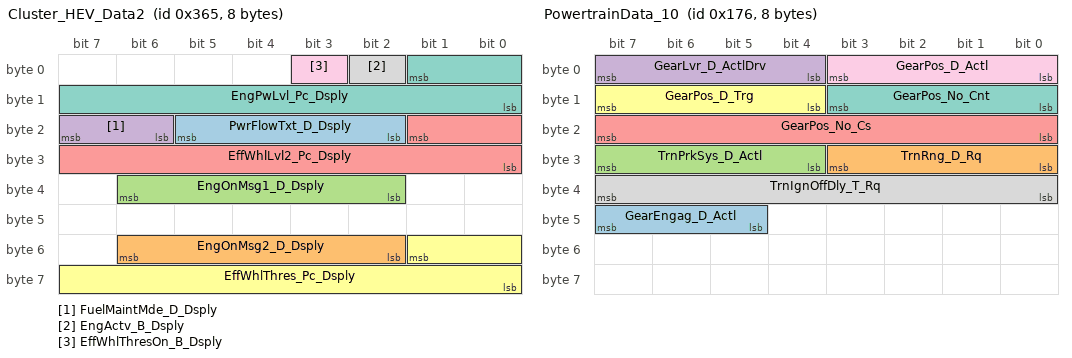
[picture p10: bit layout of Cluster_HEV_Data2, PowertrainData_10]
BO_ 869 Cluster_HEV_Data2: 8 PCM_HEV
 SG_ PwrFlowTxt_D_Dsply : 21|4@0+ (1,0) [0|15] "SED"  GWM
 SG_ EngOnMsg2_D_Dsply : 54|5@0+ (1,0) [0|31] "SED"  GWM
 SG_ EngOnMsg1_D_Dsply : 38|5@0+ (1,0) [0|31] "SED"  GWM
 SG_ FuelMaintMde_D_Dsply : 23|2@0+ (1,0) [0|3] "SED"  GWM
 SG_ EffWhlLvl2_Pc_Dsply : 17|10@0+ (0.2,-102.2) [-102.2|102.4] "percent"  GWM
 SG_ EffWhlThres_Pc_Dsply : 49|10@0+ (0.1,0) [0|102.3] "percent"  GWM
 SG_ EngPwLvl_Pc_Dsply : 1|10@0+ (0.1,0) [0|102.3] "percent"  GWM
 SG_ EngActv_B_Dsply : 2|1@0+ (1,0) [0|1] "SED"  GWM
 SG_ EffWhlThresOn_B_Dsply : 3|1@0+ (1,0) [0|1] "SED"  GWM

BO_ 606 HEV_Powertrain_Data8_FD1: 8 PCM_HEV
 SG_ ElVehLaterMde_D_Stat : 7|2@0+ (1,0) [0|3] "SED"  GWM
 SG_ ElVehNowMde_D_Stat : 5|2@0+ (1,0) [0|3] "SED"  GWM

BO_ 374 PowertrainData_10: 8 PCM
 SG_ GearEngag_D_Actl : 47|3@0+ (1,0) [0|7] "SED"  GWM
 SG_ TrnRng_D_Rq : 27|4@0+ (1,0) [0|15] "SED"  SOBDMC_HPCM_FD1,ABS_ESC,IPMA_ADAS,PSCM,ECM_Diesel,GWM
 SG_ TrnPrkSys_D_Actl : 31|4@0+ (1,0) [0|15] "SED"  SOBDMC_HPCM_FD1,ABS_ESC,IPMA_ADAS,ECM_Diesel,GWM
 SG_ GearLvr_D_ActlDrv : 7|4@0+ (1,0) [0|15] "SED"  SOBDMC_HPCM_FD1,ABS_ESC,IPMA_ADAS,TCCM,ECM_Diesel,GWM
 SG_ GearPos_No_Cs : 23|8@0+ (1,0) [0|255] "unitless"  SOBDMC_HPCM_FD1,IPMA_ADAS,ABS_ESC,ECM_Diesel,GWM
 SG_ GearPos_D_Trg : 15|4@0+ (1,0) [0|15] "SED"  SOBDMC_HPCM_FD1,IPMA_ADAS,ABS_ESC,TCCM,ECM_Diesel,GWM
 SG_ GearPos_No_Cnt : 11|4@0+ (1,0) [0|15] "unitless"  SOBDMC_HPCM_FD1,IPMA_ADAS,ABS_ESC,ECM_Diesel,GWM
 SG_ TrnIgnOffDly_T_Rq : 39|8@0+ (4,0) [0|1020] "ms"  GWM
 SG_ GearPos_D_Actl : 3|4@0+ (1,0) [0|15] "SED"  SOBDMC_HPCM_FD1,PSCM,IPMA_ADAS,ABS_ESC,ECM_Diesel,GWM

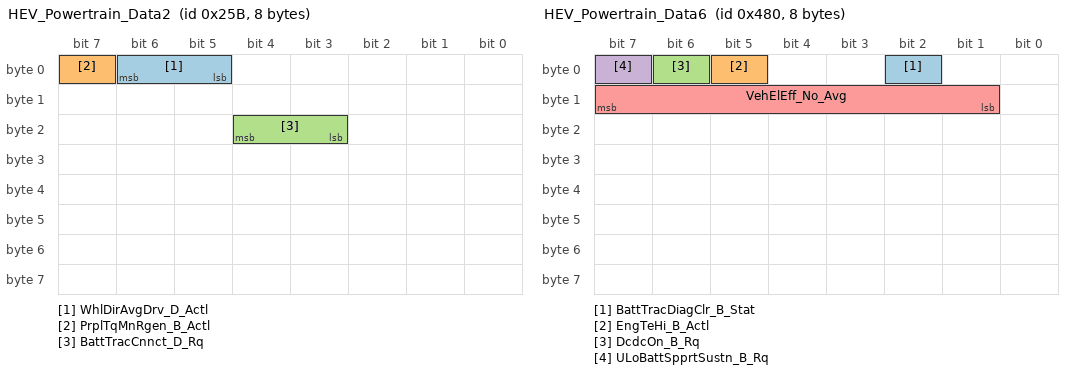
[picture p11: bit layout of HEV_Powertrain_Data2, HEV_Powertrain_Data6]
BO_ 603 HEV_Powertrain_Data2: 8 PCM_HEV
 SG_ WhlDirAvgDrv_D_Actl : 6|2@0+ (1,0) [0|3] "SED"  ABS_ESC,IPMA_ADAS,GWM
 SG_ PrplTqMnRgen_B_Actl : 7|1@0+ (1,0) [0|1] "SED"  ABS_ESC,GWM
 SG_ BattTracCnnct_D_Rq : 20|2@0+ (1,0) [0|3] "SED"  SOBDMC_HPCM_FD1,GWM

BO_ 602 HEV_Powertrain_Data: 8 PCM_HEV
 SG_ HtrnWarnLamp_B_Dsply : 3|1@0+ (1,0) [0|1] "SED"  GWM
 SG_ PwPckTqRdy_B_Dsply : 31|1@0+ (1,0) [0|1] "SED"  GWM

BO_ 1152 HEV_Powertrain_Data6: 8 PCM_HEV
 SG_ BattTracDiagClr_B_Stat : 2|1@0+ (1,0) [0|1] "SED"  GWM
 SG_ EngTeHi_B_Actl : 5|1@0+ (1,0) [0|1] "SED"  SOBDMC_HPCM_FD1,GWM
 SG_ DcdcOn_B_Rq : 6|1@0+ (1,0) [0|1] "SED"  GWM
 SG_ ULoBattSpprtSustn_B_Rq : 7|1@0+ (1,0) [0|1] "SED"  SOBDMC_HPCM_FD1,GWM
 SG_ VehElEff_No_Avg : 15|7@0+ (10,-100) [-100|1150] "watt*hr/km"  SOBDMC_HPCM_FD1,GWM

BO_ 872 Cluster_HEV_Data5: 8 PCM_HEV
 SG_ HybMdeStat_D_Dsply : 39|3@0+ (1,0) [0|7] "SED"  SOBDMC_HPCM_FD1,GWM

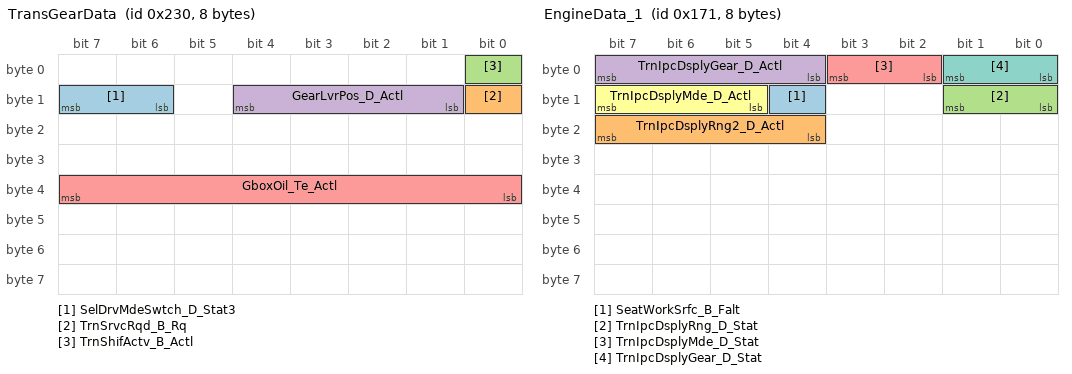
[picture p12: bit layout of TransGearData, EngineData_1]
BO_ 560 TransGearData: 8 TCM_DSL
 SG_ SelDrvMdeSwtch_D_Stat3 : 15|2@0+ (1,0) [0|3] "SED"  GWM,ABS_ESC
 SG_ TrnSrvcRqd_B_Rq : 8|1@0+ (1,0) [0|1] "SED"  GWM
 SG_ TrnShifActv_B_Actl : 0|1@0+ (1,0) [0|1] "SED"  GWM,ABS_ESC,ECM_Diesel
 SG_ GearLvrPos_D_Actl : 12|4@0+ (1,0) [0|15] "SED"  VDM,IPMA_ADAS,GWM,ABS_ESC,PSCM,TCCM,ECM_Diesel
 SG_ GboxOil_Te_Actl : 39|8@0+ (1,-60) [-60|193] "degC"  SOBDMC_HPCM_FD1,GWM,TCCM,ECM_Diesel

BO_ 369 EngineData_1: 8 PCM
 SG_ SeatWorkSrfc_B_Falt : 12|1@0+ (1,0) [0|1] "SED"  GWM
 SG_ TrnIpcDsplyRng2_D_Actl : 23|4@0+ (1,0) [0|15] "SED"  GWM
 SG_ TrnIpcDsplyRng_D_Stat : 9|2@0+ (1,0) [0|3] "SED"  GWM
 SG_ TrnIpcDsplyGear_D_Actl : 7|4@0+ (1,0) [0|15] "SED"  GWM
 SG_ TrnIpcDsplyMde_D_Stat : 3|2@0+ (1,0) [0|3] "SED"  GWM
 SG_ TrnIpcDsplyMde_D_Actl : 15|3@0+ (1,0) [0|7] "SED"  GWM
 SG_ TrnIpcDsplyGear_D_Stat : 1|2@0+ (1,0) [0|3] "SED"  GWM

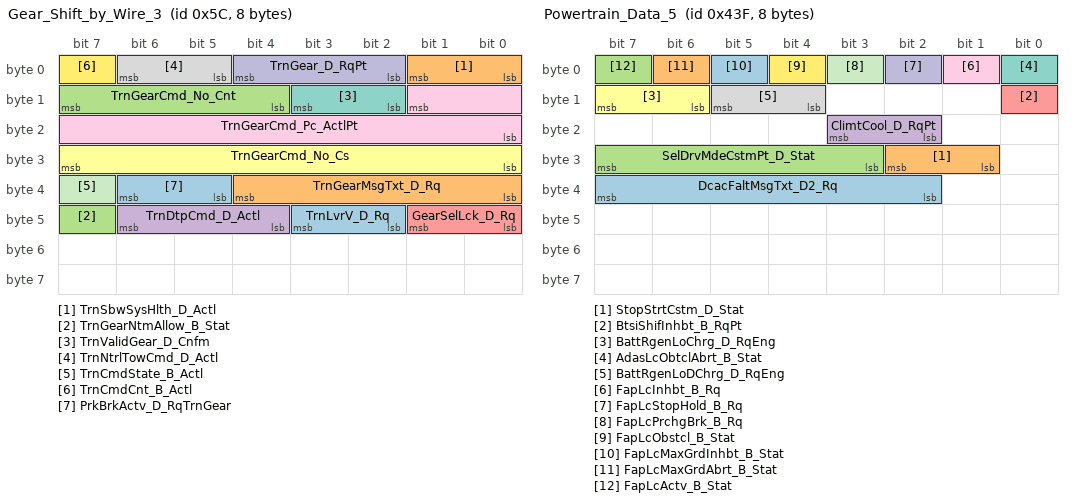
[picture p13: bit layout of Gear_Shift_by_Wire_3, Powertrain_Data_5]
BO_ 92 Gear_Shift_by_Wire_3: 8 PCM_HEV
 SG_ TrnLvrV_D_Rq : 43|2@0+ (1,0) [0|3] "SED"  GWM
 SG_ TrnSbwSysHlth_D_Actl : 1|2@0+ (1,0) [0|3] "SED"  GWM
 SG_ TrnGearNtmAllow_B_Stat : 47|1@0+ (1,0) [0|1] "SED"  GWM
 SG_ TrnDtpCmd_D_Actl : 46|3@0+ (1,0) [0|7] "SED"  GWM
 SG_ GearSelLck_D_Rq : 41|2@0+ (1,0) [0|3] "SED"  GWM
 SG_ TrnGearCmd_No_Cs : 31|8@0+ (1,0) [0|255] "Unitless"  GWM
 SG_ TrnValidGear_D_Cnfm : 11|2@0+ (1,0) [0|3] "SED"  GWM
 SG_ TrnNtrlTowCmd_D_Actl : 6|2@0+ (1,0) [0|3] "SED"  IPMA_ADAS,GWM,ABS_ESC
 SG_ TrnGearCmd_Pc_ActlPt : 9|10@0+ (0.1,0) [0|102.2] "percent duty cycle"  GWM
 SG_ TrnGear_D_RqPt : 4|3@0+ (1,0) [0|7] "SED"  GWM
 SG_ TrnCmdState_B_Actl : 39|1@0+ (1,0) [0|1] "SED"  GWM
 SG_ TrnCmdCnt_B_Actl : 7|1@0+ (1,0) [0|1] "unitless"  GWM
 SG_ PrkBrkActv_D_RqTrnGear : 38|2@0+ (1,0) [0|3] "SED"  GWM,ABS_ESC
 SG_ TrnGearMsgTxt_D_Rq : 36|5@0+ (1,0) [0|31] "SED"  GWM
 SG_ TrnGearCmd_No_Cnt : 15|4@0+ (1,0) [0|15] "Unitless"  GWM

BO_ 2030 TesterPhysicalResSOBDMCFD1: 64 ECM_Diesel
 SG_ TesterPhysicalResSOBDMC : 7|64@0+ (1,0) [0|1.84467E+019] "unitless"  TSTR

BO_ 1087 Powertrain_Data_5: 8 PCM_HEV
 SG_ DcacFaltMsgTxt_D2_Rq : 39|6@0+ (1,0) [0|63] "SED"  GWM
 SG_ StopStrtCstm_D_Stat : 26|2@0+ (1,0) [0|3] "SED"  GWM
 SG_ SelDrvMdeCstmPt_D_Stat : 31|5@0+ (1,0) [0|31] "SED"  GWM
 SG_ ClimtCool_D_RqPt : 19|2@0+ (1,0) [0|3] "SED"  GWM
 SG_ BtsiShifInhbt_B_RqPt : 8|1@0+ (1,0) [0|1] "SED"  GWM
 SG_ BattRgenLoChrg_D_RqEng : 15|2@0+ (1,0) [0|3] "SED"  GWM
 SG_ AdasLcObtclAbrt_B_Stat : 0|1@0+ (1,0) [0|1] "SED"  IPMA_ADAS,GWM
 SG_ BattRgenLoDChrg_D_RqEng : 13|2@0+ (1,0) [0|3] "SED"  GWM
 SG_ FapLcInhbt_B_Rq : 1|1@0+ (1,0) [0|1] "SED"  IPMA_ADAS,GWM
 SG_ FapLcStopHold_B_Rq : 2|1@0+ (1,0) [0|1] "SED"  GWM,ABS_ESC
 SG_ FapLcPrchgBrk_B_Rq : 3|1@0+ (1,0) [0|1] "SED"  GWM,ABS_ESC
 SG_ FapLcObstcl_B_Stat : 4|1@0+ (1,0) [0|1] "SED"  GWM,IPMA_ADAS
 SG_ FapLcMaxGrdInhbt_B_Stat : 5|1@0+ (1,0) [0|1] "SED"  GWM,IPMA_ADAS
 SG_ FapLcMaxGrdAbrt_B_Stat : 6|1@0+ (1,0) [0|1] "SED"  GWM,IPMA_ADAS
 SG_ FapLcActv_B_Stat : 7|1@0+ (1,0) [0|1] "SED"  GWM,IPMA_ADAS

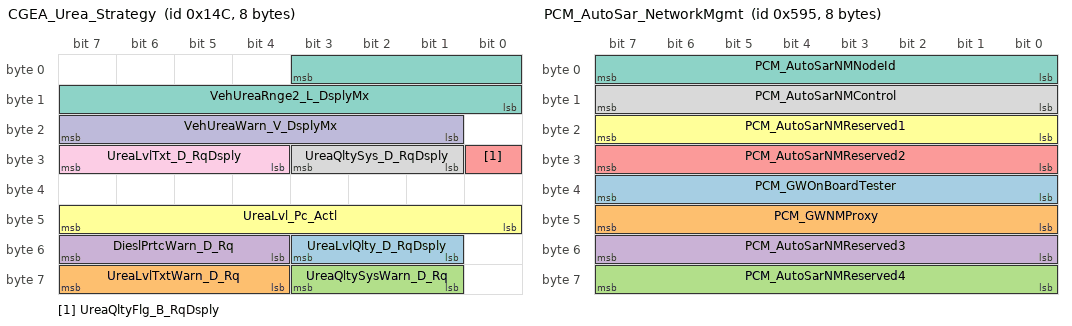
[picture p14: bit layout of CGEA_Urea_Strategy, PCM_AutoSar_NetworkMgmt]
BO_ 332 CGEA_Urea_Strategy: 8 ECM_Diesel
 SG_ UreaLvlQlty_D_RqDsply : 51|3@0+ (1,0) [0|7] "SED"  GWM
 SG_ UreaLvlTxtWarn_D_Rq : 63|4@0+ (1,0) [0|15] "SED"  GWM
 SG_ UreaQltySysWarn_D_Rq : 59|3@0+ (1,0) [0|7] "SED"  GWM
 SG_ DieslPrtcWarn_D_Rq : 55|4@0+ (1,0) [0|15] "SED"  GWM
 SG_ UreaQltyFlg_B_RqDsply : 24|1@0+ (1,0) [0|1] "SED"  GWM
 SG_ UreaLvl_Pc_Actl : 47|8@0+ (0.4,0) [0|102] "percent"  GWM
 SG_ VehUreaRnge2_L_DsplyMx : 3|12@0+ (1,0) [0|4095] "kilometer"  GWM
 SG_ UreaQltySys_D_RqDsply : 27|3@0+ (1,0) [0|7] "SED"  GWM
 SG_ UreaLvlTxt_D_RqDsply : 31|4@0+ (1,0) [0|15] "SED"  GWM
 SG_ VehUreaWarn_V_DsplyMx : 23|7@0+ (1,0) [0|127] "km/h"  GWM

BO_ 1896 TesterPhysicalResABS: 64 ABS_ESC
 SG_ TesterPhysicalResABS : 7|64@0+ (1,0) [0|1.84467E+019] "unitless"  TSTR

BO_ 1889 TesterPhysicalReqTCCM: 64 TSTR
 SG_ TesterPhysicalReqTCCM : 7|64@0+ (1,0) [0|1.84467E+019] "unitless"  TCCM

BO_ 1888 TesterPhysicalReqABS: 64 TSTR
 SG_ TesterPhysicalReqABS : 7|64@0+ (1,0) [0|1.84467E+019] "unitless"  ABS_ESC

BO_ 1848 TesterPhysicalResPSCM: 64 PSCM
 SG_ TesterPhysicalResPSCM : 7|64@0+ (1,0) [0|1.84467E+019] "unitless"  TSTR

BO_ 1840 TesterPhysicalReqPSCM: 64 TSTR
 SG_ TesterPhysicalReqPSCM : 7|64@0+ (1,0) [0|1.84467E+019] "unitless"  PSCM

BO_ 1713 ABS_Rapid_Data_Response_2: 8 ABS_ESC
 SG_ UUDTABSResponse2 : 7|64@0+ (1,0) [0|1.84467440737096E+019] "unitless"  TSTR

BO_ 1712 ABS_Rapid_Data_Response_1: 8 ABS_ESC
 SG_ UUDTABSResponse1 : 7|64@0+ (1,0) [0|1.84467440737096E+019] "unitless"  TSTR

BO_ 2025 TesterPhysicalResTCM: 64 TCM_DSL
 SG_ TesterPhysicalResTCM : 7|64@0+ (1,0) [0|1.84467E+019] "unitless"  TSTR

BO_ 2024 TesterPhysicalResPCM: 64 PCM_HEV
 SG_ TesterPhysicalResPCM : 7|64@0+ (1,0) [0|1.84467E+019] "unitless"  TSTR

BO_ 2017 TesterPhysicalReqTCM: 64 TSTR
 SG_ TesterPhysicalReqTCM : 7|64@0+ (1,0) [0|1.84467E+019] "unitless"  TCM_DSL

BO_ 2016 TesterPhysicalReqPCM: 64 TSTR
 SG_ TesterPhysicalReqPCM : 7|64@0+ (1,0) [0|1.84467E+019] "unitless"  ECM_Diesel,PCM,PCM_HEV

BO_ 2015 TesterFunctionalReq_FD1: 64 TSTR
 SG_ TesterFunctionalReq : 7|64@0+ (1,0) [0|1.84467E+019] "unitless"  VDM,CMR_DSMC,SOBDMC_HPCM_FD1,IPMA_ADAS,ECM_Diesel,PCM,PCM_HEV,TCCM,TCM_DSL,PSCM,ABS_ESC,GWM

BO_ 1897 TesterPhysicalResTCCM: 64 TCCM
 SG_ TesterPhysicalResTCCM : 7|64@0+ (1,0) [0|1.84467E+019] "unitless"  TSTR

BO_ 1814 TesterPhysicalReqGWM_FD1: 64 TSTR
 SG_ TesterPhysicalReqGWM_F1 : 7|64@0+ (1,0) [0|1.84467E+019] "unitless"  GWM

BO_ 1701 TCM_Rapid_Data_Response_2: 8 TCM_DSL
 SG_ UUDTTCMResponse2 : 7|64@0+ (1,0) [0|1.84467440737096E+019] "unitless"  TSTR

BO_ 1700 TCM_Rapid_Data_Response_1: 8 TCM_DSL
 SG_ UUDTTCMResponse1 : 7|64@0+ (1,0) [0|1.84467440737096E+019] "unitless"  TSTR

BO_ 1697 PCM_Rapid_Data_Response_2: 8 PCM_HEV
 SG_ UUDTPCMResponse2 : 7|64@0+ (1,0) [0|1.84467440737096E+019] "unitless"  TSTR

BO_ 1696 PCM_Rapid_Data_Response_1: 8 PCM_HEV
 SG_ UUDTPCMResponse1 : 7|64@0+ (1,0) [0|1.84467440737096E+019] "unitless"  TSTR

BO_ 1429 PCM_AutoSar_NetworkMgmt: 8 PCM_HEV
 SG_ PCM_GWOnBoardTester : 39|8@0+ (1,0) [0|255] "unitless"  TCM_DSL
 SG_ PCM_GWNMProxy : 47|8@0+ (1,0) [0|255] "unitless"  TCM_DSL
 SG_ PCM_AutoSarNMReserved4 : 63|8@0+ (1,0) [0|255] "unitless"  TCM_DSL
 SG_ PCM_AutoSarNMReserved3 : 55|8@0+ (1,0) [0|255] "unitless"  TCM_DSL
 SG_ PCM_AutoSarNMReserved2 : 31|8@0+ (1,0) [0|255] "unitless"  TCM_DSL
 SG_ PCM_AutoSarNMReserved1 : 23|8@0+ (1,0) [0|255] "unitless"  TCM_DSL
 SG_ PCM_AutoSarNMNodeId : 7|8@0+ (1,0) [0|255] "unitless"  TCM_DSL
 SG_ PCM_AutoSarNMControl : 15|8@0+ (1,0) [0|255] "unitless"  TCM_DSL

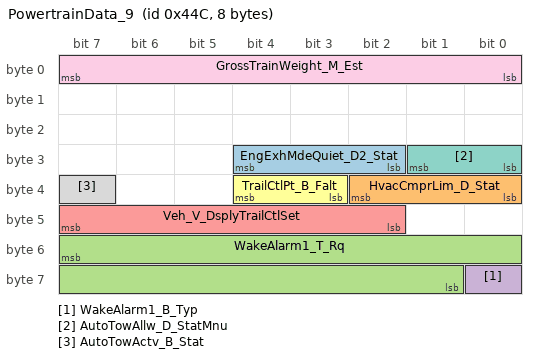
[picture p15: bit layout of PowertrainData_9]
BO_ 1100 PowertrainData_9: 8 PCM_HEV
 SG_ EngExhMdeQuiet_D2_Stat : 28|3@0+ (1,0) [0|7] "SED"  GWM
 SG_ HvacCmprLim_D_Stat : 34|3@0+ (1,0) [0|7] "SED"  GWM
 SG_ WakeAlarm1_T_Rq : 55|15@0+ (1,0) [0|32767] "minute"  GWM
 SG_ WakeAlarm1_B_Typ : 56|1@0+ (1,0) [0|1] "SED"  GWM
 SG_ Veh_V_DsplyTrailCtlSet : 47|6@0+ (0.5,0) [0|31] "unitless"  GWM
 SG_ TrailCtlPt_B_Falt : 36|2@0+ (1,0) [0|3] "SED"  ABS_ESC,GWM
 SG_ AutoTowAllw_D_StatMnu : 25|2@0+ (1,0) [0|3] "SED"  GWM
 SG_ AutoTowActv_B_Stat : 39|1@0+ (1,0) [0|1] "SED"  IPMA_ADAS,GWM
 SG_ GrossTrainWeight_M_Est : 7|8@0+ (100,0) [0|25300] "kilogram"  VDM,ABS_ESC,PSCM,IPMA_ADAS,TCCM,TCM_DSL,GWM

BO_TX_BU_ 1090 : PCM,PCM_HEV;
BO_TX_BU_ 374 : PCM_HEV,TCM_DSL,PCM;
BO_TX_BU_ 560 : PCM,PCM_HEV,TCM_DSL;
BO_TX_BU_ 369 : PCM_HEV,TCM_DSL,PCM;
BO_TX_BU_ 92 : PCM,TCM_DSL,PCM_HEV;
BO_TX_BU_ 2030 : SOBDMC_HPCM_FD1,ECM_Diesel;
BO_TX_BU_ 1087 : ECM_Diesel,PCM,PCM_HEV;
BO_TX_BU_ 2024 : ECM_Diesel,PCM,PCM_HEV;
BO_TX_BU_ 1697 : ECM_Diesel,PCM,PCM_HEV;
BO_TX_BU_ 1696 : ECM_Diesel,PCM,PCM_HEV;
BO_TX_BU_ 1429 : ECM_Diesel,PCM,PCM_HEV;
BO_TX_BU_ 1100 : ECM_Diesel,PCM,PCM_HEV;
CM_ BO_ 130 "drecker 10/23/09 Need SAPP in sync w/Strg Torque for proper PAM interpretation, else fault msg's displayed FP@20ms IPC needs EPAS_Failure for msg to driver.  Not map w/Lane Assist FP@30s FP), save bandwidth if feature not on vehicle ";
CM_ SG_ 130 VehVTrlrAid_B_Rq "VR session start- req. limit blower speed no more than X volts.  CC restriction on time msg. will be honored.Double Event msg1st event to request limit, 2nd event to release limit, No msg. CC Grammar v7.xls";
CM_ SG_ 130 SteMdule_U_Meas "DCR 1745  to update Tx from GWM to EP100ms. SteMdule_I_Est & SteMdule_U_Meas are used by BMS system & filtered. The filter uses standard periodic rate & changing to EP would adversely affect the filter.(jweinfur)";
CM_ SG_ 130 SteMdule_I_Est "DCR 1745  to update Tx from GWM to EP100ms. SteMdule_I_Est & SteMdule_U_Meas are used by BMS system & filtered. The filter uses standard periodic rate & changing to EP would adversely affect the filter.(jweinfur)";
CM_ SG_ 126 StePinRelInit_An_Sns "SASM will transmit these signals on vehicles with SASM and without PSCM.  SCCM will not Tx this signal when SASM is present.";
CM_ SG_ 126 StePinAn_No_Cs "Signal not transmitted on gas variants.";
CM_ SG_ 1200 BrkTot_Tq_RqDrv "DCR 1836 to update Tx from GWM to EP100ms rejected due MPS6 TCM requires BrkTot_Tq_RqDrv at 20ms (bshu1).";
CM_ SG_ 1046 TCMode "Signal data set to 0x0 for ABS only vehicle option content";
CM_ SG_ 1046 DrvAntiLckLamp_D_Rq "update value table v8.34, not align w/GSDB, need etracker.  ABS & IPC implemented as updated.";
CM_ SG_ 1046 BpedMove_D_Actl "CCMGenSigTimeoutTime=1000";
CM_ SG_ 1044 StePinOffst_An_Est "SASM will transmit these signals on vehicles with SASM and without PSCM.  SCCM will not Tx this signal when SASM is present.";
CM_ SG_ 1044 StePinOffst_No_Cs "Signal not transmitted on gas variants.";
CM_ SG_ 534 BrkObdData_No_Actl "Signal not transmitted on gas, diesel and HEV.  Only supported on PHEV.";
CM_ SG_ 534 BrkObdIndex_No_Actl "Signal not transmitted on gas, diesel and HEV.  Only supported on PHEV.";
CM_ SG_ 534 WhlRotatRr_No_Cnt "DCR 1833 to update Tx from GWM to EP100ms. Wheel Count signals are used by complex algorithm to determine Tire Pressure by Location & can't change from 20msec. (jweinfur)";
CM_ SG_ 534 WhlRotatRl_No_Cnt "DCR 1833 to update Tx from GWM to EP100ms. Wheel Count signals are used by complex algorithm to determine Tire Pressure by Location & can't change from 20msec. (jweinfur)";
CM_ SG_ 534 WhlRotatFr_No_Cnt "DCR 1833 to update Tx from GWM to EP100ms. Wheel Count signals are used by complex algorithm to determine Tire Pressure by Location & can't change from 20msec. (jweinfur)";
CM_ SG_ 534 WhlRotatFl_No_Cnt "DCR 1833 to update Tx from GWM to EP100ms. Wheel Count signals are used by complex algorithm to determine Tire Pressure by Location & can't change from 20msec. (jweinfur)";
CM_ BO_ 532 "IC is NOT to use data in this message for displays, Used data from 415 instead.";
CM_ BO_ 531 "When PBM is present use 0x41B for PrkMsgTxt_D_Rq, PrkBrkRedLamp_D_Rq, PrkBrkYwLamp_D_Rq source signals otherwise ABS will source from 0x213.";
CM_ SG_ 531 VehLongOvrGnd_A_Est "CCMGenSigTimeoutTime=1000";
CM_ BO_ 73 "Provide target function information to the control function of the Passive Anti-Theft Subsystem";
CM_ SG_ 1034 VehicleGGCCData "RCMGenSigTimeout=6000";
CM_ SG_ 1090 HybVehMde_D_ActlMntr "Signal Not transmitted on GAS variant";
CM_ SG_ 1090 ChrgStat_D_ActlMntr "Signal Not transmitted on GAS variant";
CM_ SG_ 1090 VehElRnge_L_Dsply "Signal Not transmitted on GAS & HPCM variants";
CM_ BO_ 374 "Programs w/o HS1 0x172 will need HS1 0x176 for GearPos_D_Actl.  Future MY Programs that choose c/o still require HS1 0x172. ";
CM_ SG_ 374 TrnRng_D_Rq "Powersplit HEVs with HF45, HPCM will Tx  this message.  For all other programs it will be Tx by PCM or TCM. ";
CM_ SG_ 374 TrnPrkSys_D_Actl "Powersplit HEVs with HF45, HPCM will Tx  this message.  For all other programs it will be Tx by PCM or TCM. ";
CM_ SG_ 374 GearLvr_D_ActlDrv "Powersplit HEVs with HF45, HPCM will Tx  this message.  For all other programs it will be Tx by PCM or TCM. ";
CM_ SG_ 374 GearPos_No_Cs "Powersplit HEVs with HF45, HPCM will Tx  this message.  For all other programs it will be Tx by PCM or TCM. ";
CM_ SG_ 374 GearPos_D_Trg "Powersplit HEVs with HF45, HPCM will Tx  this message.  For all other programs it will be Tx by PCM or TCM. ";
CM_ SG_ 374 GearPos_No_Cnt "Powersplit HEVs with HF45, HPCM will Tx  this message.  For all other programs it will be Tx by PCM or TCM. ";
CM_ SG_ 374 GearPos_D_Actl "Powersplit HEVs with HF45, HPCM will Tx  this message.  For all other programs it will be Tx by PCM or TCM. ";
CM_ BO_ 603 "48V mHEV: ECM_HEVDSL is Tx
MHT HEV: PCM_HEV is Tx
Powersplit HEV: SOBDMC_HPCM is Tx
";
CM_ SG_ 603 WhlDirAvgDrv_D_Actl "48V mHEV: ECM_HEVDSL is Tx,  MHT HEV: PCM_HEV is Tx,  Powersplit HEV: SOBDMC_HPCM is Tx";
CM_ SG_ 603 PrplTqMnRgen_B_Actl "48V mHEV: ECM_HEVDSL is Tx,  MHT HEV: PCM_HEV is Tx,  Powersplit HEV: SOBDMC_HPCM is Tx";
CM_ SG_ 603 BattTracCnnct_D_Rq "48V mHEV: ECM_HEVDSL is Tx,  MHT HEV: PCM_HEV is Tx,  Powersplit HEV: SOBDMC_HPCM is Tx";
CM_ SG_ 872 HybMdeStat_D_Dsply "Signal not transmitted by HPCM";
CM_ BO_ 560 "MHT (U611/625) the HPCM will Rx 0x230 from the PCM_HEV
Powersplit FWD HEV’s (Cx482/3 430) the HPCM will Tx 0x230";
CM_ SG_ 560 SelDrvMdeSwtch_D_Stat3 "ECM_HEV,  PCM & PCM_HEV do not support or Transmit signal.";
CM_ SG_ 560 TrnSrvcRqd_B_Rq "Signal not transmitted on Diesel & HEV variants. MHT(U611/625) HPCM Rx 0x230 from PCM_HEV. Powersplit FWD HEV’s(Cx482/3 430) HPCM Tx 0x230.";
CM_ SG_ 560 TrnShifActv_B_Actl "Signal not transmitted on HEV variants. MHT(U611/625) HPCM Rx 0x230 from PCM_HEV. Powersplit FWD HEV’s(Cx482/3 430) HPCM Tx 0x230.";
CM_ SG_ 560 GboxOil_Te_Actl "Signal not transmitted on HEV variants. MHT(U611/625) HPCM Rx 0x230 from PCM_HEV. Powersplit FWD HEV’s(Cx482/3 430) HPCM Tx 0x230.";
CM_ SG_ 369 SeatWorkSrfc_B_Falt "Signal Not transmitted by TCM_DSL";
CM_ SG_ 92 TrnLvrV_D_Rq "Signal not transmitted on vehicles with PCM_HEV";
CM_ SG_ 92 TrnSbwSysHlth_D_Actl "Signal not transmitted on vehicles that do not have shift by wire.";
CM_ SG_ 92 TrnGearNtmAllow_B_Stat "Signal not transmitted on vehicles that do not have shift by wire.";
CM_ SG_ 92 TrnDtpCmd_D_Actl "Signal not transmitted on vehicles that do not have shift by wire.";
CM_ SG_ 92 TrnGearCmd_No_Cs "Signal not transmitted on vehicles that do not have shift by wire.";
CM_ SG_ 92 TrnValidGear_D_Cnfm "Signal not transmitted on vehicles that do not have shift by wire.";
CM_ SG_ 92 TrnNtrlTowCmd_D_Actl "Signal not transmitted on vehicles that do not have shift by wire.";
CM_ SG_ 92 TrnGearCmd_Pc_ActlPt "Signal not transmitted on vehicles that do not have shift by wire.";
CM_ SG_ 92 TrnGear_D_RqPt "Signal not transmitted on vehicles that do not have shift by wire.";
CM_ SG_ 92 TrnCmdState_B_Actl "Signal not transmitted on vehicles that do not have shift by wire.";
CM_ SG_ 92 TrnCmdCnt_B_Actl "Signal not transmitted on vehicles that do not have shift by wire.";
CM_ SG_ 92 PrkBrkActv_D_RqTrnGear "Signal not transmitted on vehicles that do not have shift by wire.";
CM_ SG_ 92 TrnGearMsgTxt_D_Rq "Signal not transmitted on vehicles that do not have shift by wire.";
CM_ SG_ 92 TrnGearCmd_No_Cnt "Signal not transmitted on vehicles that do not have shift by wire.";
CM_ SG_ 1087 DcacFaltMsgTxt_D2_Rq "Signal not transmitted on Diesel variant.";
CM_ SG_ 1087 ClimtCool_D_RqPt "Signal not transmitted on Diesel variant";
CM_ SG_ 1087 BtsiShifInhbt_B_RqPt "Signal not transmitted on Diesel variant";
CM_ SG_ 1087 BattRgenLoChrg_D_RqEng "Signal not transmitted on diesel variant";
CM_ SG_ 1087 BattRgenLoDChrg_D_RqEng "Signal not transmitted on diesel variant";
CM_ SG_ 1087 FapLcInhbt_B_Rq "Signal not transmitted on diesel variant";
CM_ BO_ 2015 "OBDII Request ($7DF) messages are for FNOS 1.0.1 only.
Diagnostic Functional Addressing ($7DF) and Dual Rate Periodic messages are for FNOS I3 only.";
CM_ SG_ 1100 EngExhMdeQuiet_D2_Stat "Signal not transmitted on HEV & Diesel programs";
CM_ SG_ 1100 HvacCmprLim_D_Stat "Signal not transmitted on Diesel variants";
CM_ SG_ 1100 WakeAlarm1_T_Rq "Signal not transmitted on Gas variants";
CM_ SG_ 1100 WakeAlarm1_B_Typ "Signal not transmitted on Gas variants";
CM_ SG_ 1100 Veh_V_DsplyTrailCtlSet "Signal not transmitted on HEV & Diesel programs";
CM_ SG_ 1100 TrailCtlPt_B_Falt "Signal not transmitted on HEV & Diesel programs";
CM_ SG_ 1100 AutoTowAllw_D_StatMnu "Signal not transmitted on Gas & Diesel variants";
CM_ SG_ 1100 AutoTowActv_B_Stat "Signal not transmitted on Gas & Diesel variants";
BA_DEF_ SG_  "U_CD542_MY2021_Rx" ENUM  "No","Yes";
BA_DEF_ SG_  "U_CD542_MY2021_Tx" ENUM  "No","Yes";
BA_DEF_ SG_  "U_U55X_MY2022_Tx" ENUM  "No","Yes";
BA_DEF_ BO_  "OvtpPushApplication" ENUM  "FALSE","TRUE";
BA_DEF_ SG_  "ECGUsedRxSignal" ENUM  "No","Yes";
BA_DEF_ SG_  "ECGUsedTxSignal" ENUM  "No","Yes";
BA_DEF_ BO_  "VFrameFormat" ENUM  "StandardCAN","ExtendedCAN","reserved","reserved","reserved","reserved","reserved","reserved","reserved","reserved","reserved","reserved","reserved","reserved","StandardCAN_FD","ExtendedCAN_FD";
BA_DEF_ BO_  "FrameRouting" STRING ;
BA_DEF_ BO_  "FrameGatewayNetwork" STRING ;
BA_DEF_ BO_  "NetworkInitialization" ENUM  "No","Yes";
BA_DEF_ BO_  "FrameGatewayId" HEX 0 1407;
BA_DEF_ BO_  "EventRateOfChange" INT 10 10000;
BA_DEF_ BO_  "GenMsgStartDelayTime" INT 0 10000;
BA_DEF_ BO_  "GenMsgNrOfRepetition" INT 0 100;
BA_DEF_ BO_  "GenMsgDelayTime" INT 0 1000;
BA_DEF_ BO_  "GenMsgCycleTime" INT 0 100000;
BA_DEF_ BO_  "GenMsgSendType" ENUM  "FixedPeriodic","Event","EnabledPeriodic","NotUsed","NotUsed","EventPeriodic","NotUsed","NotUsed","NoMsgSendType";
BA_DEF_ SG_  "U_T6_MCA_MY2020_Tx" ENUM  "No","Yes";
BA_DEF_ SG_  "U_P702_MY2021_Tx" ENUM  "No","Yes";
BA_DEF_ SG_  "U_CX727_MY2021_Tx" ENUM  "No","Yes";
BA_DEF_ SG_  "U_T6_MCA_MY2020_Rx" ENUM  "No","Yes";
BA_DEF_ SG_  "U_P702_MY2021_Rx" ENUM  "No","Yes";
BA_DEF_ SG_  "U_CX727_MY2021_Rx" ENUM  "No","Yes";
BA_DEF_ SG_  "GenSigStartValue" HEX 0 268435455;
BA_DEF_ SG_  "MetaData" ENUM  "No","Yes";
BA_DEF_ SG_  "ContentDependant" ENUM  "No","Yes";
BA_DEF_ SG_  "GenSigStartValueInteger" INT 0 1000000000;
BA_DEF_ SG_  "UsedOnPgmDBC" ENUM  "No","Yes";
BA_DEF_ SG_  "CrossOver_InfoCAN" ENUM  "No","Yes";
BA_DEF_ SG_  "WakeupSignal" ENUM  "No","Yes";
BA_DEF_ SG_  "GenSigInactiveValue" INT 0 100000;
BA_DEF_ SG_  "GenSigSendType" ENUM  "Cyclic","OnWrite","vector_leerstring","OnChange","vector_leerstring","IfActive","vector_leerstring","NoSigSendType";
BA_DEF_ BO_  "SCP_FreshnessValueLength" INT 0 512;
BA_DEF_ BO_  "AuthFreshnessCounterSyncAttempt" INT 0 512;
BA_DEF_ BO_  "SCP_FreshnessValueTxLength" INT 0 512;
BA_DEF_ BO_  "SCP_AuthInfoTxLength" INT 0 512;
BA_DEF_ BO_  "ProgBWConditional" STRING ;
BA_DEF_ BO_  "NmAsrMessage" ENUM  "No","Yes";
BA_DEF_ BO_  "TpApplType" STRING ;
BA_DEF_ BO_  "DiagState" ENUM  "No","Yes";
BA_DEF_ BO_  "TpTxIndex" INT 0 536870911;
BA_DEF_ BO_  "DiagRequest" ENUM  "No","Yes";
BA_DEF_ BO_  "DiagResponse" ENUM  "No","Yes";
BA_DEF_ BO_  "GenMsgILSupport" ENUM  "No","Yes";
BA_DEF_DEF_  "U_CD542_MY2021_Rx" "No";
BA_DEF_DEF_  "U_CD542_MY2021_Tx" "No";
BA_DEF_DEF_  "U_U55X_MY2022_Tx" "No";
BA_DEF_DEF_  "OvtpPushApplication" "FALSE";
BA_DEF_DEF_  "ECGUsedRxSignal" "No";
BA_DEF_DEF_  "ECGUsedTxSignal" "No";
BA_DEF_DEF_  "VFrameFormat" "ExtendedCAN_FD";
BA_DEF_DEF_  "FrameRouting" "NONE";
BA_DEF_DEF_  "FrameGatewayNetwork" "NONE";
BA_DEF_DEF_  "NetworkInitialization" "Yes";
BA_DEF_DEF_  "FrameGatewayId" 0;
BA_DEF_DEF_  "EventRateOfChange" 10000;
BA_DEF_DEF_  "GenMsgStartDelayTime" 0;
BA_DEF_DEF_  "GenMsgNrOfRepetition" 1;
BA_DEF_DEF_  "GenMsgDelayTime" 20;
BA_DEF_DEF_  "GenMsgCycleTime" 0;
BA_DEF_DEF_  "GenMsgSendType" "NoMsgSendType";
BA_DEF_DEF_  "U_T6_MCA_MY2020_Tx" "No";
BA_DEF_DEF_  "U_P702_MY2021_Tx" "No";
BA_DEF_DEF_  "U_CX727_MY2021_Tx" "No";
BA_DEF_DEF_  "U_T6_MCA_MY2020_Rx" "No";
BA_DEF_DEF_  "U_P702_MY2021_Rx" "No";
BA_DEF_DEF_  "U_CX727_MY2021_Rx" "No";
BA_DEF_DEF_  "GenSigStartValue" 0;
BA_DEF_DEF_  "MetaData" "No";
BA_DEF_DEF_  "ContentDependant" "No";
BA_DEF_DEF_  "GenSigStartValueInteger" 0;
BA_DEF_DEF_  "UsedOnPgmDBC" "Yes";
BA_DEF_DEF_  "CrossOver_InfoCAN" "No";
BA_DEF_DEF_  "WakeupSignal" "No";
BA_DEF_DEF_  "GenSigInactiveValue" 0;
BA_DEF_DEF_  "GenSigSendType" "NoSigSendType";
BA_DEF_DEF_  "SCP_FreshnessValueLength" 64;
BA_DEF_DEF_  "AuthFreshnessCounterSyncAttempt" 2;
BA_DEF_DEF_  "SCP_FreshnessValueTxLength" 11;
BA_DEF_DEF_  "SCP_AuthInfoTxLength" 53;
BA_DEF_DEF_  "ProgBWConditional" "NONE";
BA_DEF_DEF_  "NmAsrMessage" "No";
BA_DEF_DEF_  "TpApplType" "";
BA_DEF_DEF_  "DiagState" "No";
BA_DEF_DEF_  "TpTxIndex" 0;
BA_DEF_DEF_  "DiagRequest" "No";
BA_DEF_DEF_  "DiagResponse" "No";
BA_DEF_DEF_  "GenMsgILSupport" "Yes";
BA_ "NetworkInitialization" BO_ 1461 0;
BA_ "GenMsgCycleTime" BO_ 1461 1000;
BA_ "GenMsgSendType" BO_ 1461 0;
BA_ "NmAsrMessage" BO_ 1461 1;
BA_ "GenMsgILSupport" BO_ 1461 0;
BA_ "FrameRouting" BO_ 1461 "";
BA_ "VFrameFormat" BO_ 1461 14;
BA_ "GenMsgCycleTime" BO_ 1047 1000;
BA_ "GenMsgSendType" BO_ 1047 5;
BA_ "FrameRouting" BO_ 1047 "";
BA_ "VFrameFormat" BO_ 1047 14;
BA_ "GenMsgDelayTime" BO_ 972 10;
BA_ "GenMsgCycleTime" BO_ 972 30;
BA_ "GenMsgSendType" BO_ 972 0;
BA_ "FrameRouting" BO_ 972 "";
BA_ "VFrameFormat" BO_ 972 14;
BA_ "GenMsgDelayTime" BO_ 130 10;
BA_ "GenMsgCycleTime" BO_ 130 20;
BA_ "GenMsgSendType" BO_ 130 0;
BA_ "FrameRouting" BO_ 130 "";
BA_ "VFrameFormat" BO_ 130 14;
BA_ "GenMsgDelayTime" BO_ 126 0;
BA_ "GenMsgCycleTime" BO_ 126 10;
BA_ "GenMsgSendType" BO_ 126 0;
BA_ "FrameRouting" BO_ 126 "";
BA_ "VFrameFormat" BO_ 126 14;
BA_ "NetworkInitialization" BO_ 1430 0;
BA_ "GenMsgCycleTime" BO_ 1430 1000;
BA_ "GenMsgSendType" BO_ 1430 0;
BA_ "NmAsrMessage" BO_ 1430 1;
BA_ "GenMsgILSupport" BO_ 1430 0;
BA_ "FrameRouting" BO_ 1430 "";
BA_ "VFrameFormat" BO_ 1430 14;
BA_ "GenMsgDelayTime" BO_ 1200 10;
BA_ "GenMsgCycleTime" BO_ 1200 20;
BA_ "GenMsgSendType" BO_ 1200 0;
BA_ "FrameRouting" BO_ 1200 "";
BA_ "VFrameFormat" BO_ 1200 14;
BA_ "GenMsgStartDelayTime" BO_ 1102 1130;
BA_ "GenMsgCycleTime" BO_ 1102 100000;
BA_ "GenMsgSendType" BO_ 1102 5;
BA_ "FrameRouting" BO_ 1102 "";
BA_ "VFrameFormat" BO_ 1102 14;
BA_ "GenMsgCycleTime" BO_ 1056 1000;
BA_ "GenMsgSendType" BO_ 1056 5;
BA_ "FrameRouting" BO_ 1056 "";
BA_ "VFrameFormat" BO_ 1056 14;
BA_ "GenMsgCycleTime" BO_ 1054 1000;
BA_ "GenMsgSendType" BO_ 1054 5;
BA_ "FrameRouting" BO_ 1054 "";
BA_ "VFrameFormat" BO_ 1054 14;
BA_ "GenMsgCycleTime" BO_ 1046 100;
BA_ "GenMsgSendType" BO_ 1046 0;
BA_ "FrameRouting" BO_ 1046 "";
BA_ "VFrameFormat" BO_ 1046 14;
BA_ "GenMsgDelayTime" BO_ 1045 10;
BA_ "GenMsgCycleTime" BO_ 1045 20;
BA_ "GenMsgSendType" BO_ 1045 0;
BA_ "FrameRouting" BO_ 1045 "";
BA_ "VFrameFormat" BO_ 1045 14;
BA_ "GenMsgCycleTime" BO_ 1044 100;
BA_ "GenMsgSendType" BO_ 1044 0;
BA_ "FrameRouting" BO_ 1044 "";
BA_ "VFrameFormat" BO_ 1044 14;
BA_ "GenMsgCycleTime" BO_ 1042 50;
BA_ "GenMsgSendType" BO_ 1042 0;
BA_ "FrameRouting" BO_ 1042 "";
BA_ "VFrameFormat" BO_ 1042 14;
BA_ "GenMsgDelayTime" BO_ 535 0;
BA_ "GenMsgCycleTime" BO_ 535 10;
BA_ "GenMsgSendType" BO_ 535 0;
BA_ "FrameRouting" BO_ 535 "";
BA_ "VFrameFormat" BO_ 535 14;
BA_ "GenMsgDelayTime" BO_ 534 10;
BA_ "GenMsgCycleTime" BO_ 534 20;
BA_ "GenMsgSendType" BO_ 534 0;
BA_ "FrameRouting" BO_ 534 "";
BA_ "VFrameFormat" BO_ 534 14;
BA_ "GenMsgDelayTime" BO_ 532 10;
BA_ "GenMsgCycleTime" BO_ 532 20;
BA_ "GenMsgSendType" BO_ 532 0;
BA_ "FrameRouting" BO_ 532 "";
BA_ "VFrameFormat" BO_ 532 14;
BA_ "GenMsgDelayTime" BO_ 531 10;
BA_ "GenMsgCycleTime" BO_ 531 20;
BA_ "GenMsgSendType" BO_ 531 0;
BA_ "FrameRouting" BO_ 531 "";
BA_ "VFrameFormat" BO_ 531 14;
BA_ "GenMsgDelayTime" BO_ 125 10;
BA_ "GenMsgCycleTime" BO_ 125 20;
BA_ "GenMsgSendType" BO_ 125 0;
BA_ "FrameRouting" BO_ 125 "";
BA_ "VFrameFormat" BO_ 125 14;
BA_ "GenMsgDelayTime" BO_ 119 10;
BA_ "GenMsgCycleTime" BO_ 119 20;
BA_ "GenMsgSendType" BO_ 119 0;
BA_ "FrameRouting" BO_ 119 "";
BA_ "VFrameFormat" BO_ 119 14;
BA_ "GenMsgCycleTime" BO_ 118 500;
BA_ "GenMsgSendType" BO_ 118 5;
BA_ "FrameRouting" BO_ 118 "";
BA_ "VFrameFormat" BO_ 118 14;
BA_ "GenMsgDelayTime" BO_ 73 10;
BA_ "GenMsgCycleTime" BO_ 73 20;
BA_ "GenMsgSendType" BO_ 73 0;
BA_ "FrameRouting" BO_ 73 "";
BA_ "VFrameFormat" BO_ 73 14;
BA_ "FrameGatewayNetwork" BO_ 1034 "HS1_CAN";
BA_ "FrameGatewayId" BO_ 1034 1034;
BA_ "FrameRouting" BO_ 1034 "";
BA_ "VFrameFormat" BO_ 1034 14;
BA_ "NetworkInitialization" BO_ 1440 0;
BA_ "GenMsgCycleTime" BO_ 1440 1000;
BA_ "GenMsgSendType" BO_ 1440 0;
BA_ "NmAsrMessage" BO_ 1440 1;
BA_ "GenMsgILSupport" BO_ 1440 0;
BA_ "FrameRouting" BO_ 1440 "";
BA_ "VFrameFormat" BO_ 1440 14;
BA_ "GenMsgCycleTime" BO_ 561 100;
BA_ "GenMsgSendType" BO_ 561 0;
BA_ "FrameRouting" BO_ 561 "";
BA_ "VFrameFormat" BO_ 561 14;
BA_ "GenMsgDelayTime" BO_ 330 0;
BA_ "GenMsgCycleTime" BO_ 330 10;
BA_ "GenMsgSendType" BO_ 330 0;
BA_ "FrameRouting" BO_ 330 "";
BA_ "VFrameFormat" BO_ 330 14;
BA_ "GenMsgCycleTime" BO_ 1090 1000;
BA_ "GenMsgSendType" BO_ 1090 0;
BA_ "FrameRouting" BO_ 1090 "";
BA_ "VFrameFormat" BO_ 1090 14;
BA_ "GenMsgCycleTime" BO_ 870 100;
BA_ "GenMsgSendType" BO_ 870 0;
BA_ "FrameRouting" BO_ 870 "";
BA_ "VFrameFormat" BO_ 870 14;
BA_ "GenMsgCycleTime" BO_ 869 100;
BA_ "GenMsgSendType" BO_ 869 0;
BA_ "FrameRouting" BO_ 869 "";
BA_ "VFrameFormat" BO_ 869 14;
BA_ "GenMsgCycleTime" BO_ 606 1000;
BA_ "GenMsgSendType" BO_ 606 5;
BA_ "FrameRouting" BO_ 606 "";
BA_ "VFrameFormat" BO_ 606 14;
BA_ "GenMsgCycleTime" BO_ 374 100;
BA_ "GenMsgSendType" BO_ 374 5;
BA_ "FrameRouting" BO_ 374 "";
BA_ "VFrameFormat" BO_ 374 14;
BA_ "GenMsgDelayTime" BO_ 603 10;
BA_ "GenMsgCycleTime" BO_ 603 20;
BA_ "GenMsgSendType" BO_ 603 0;
BA_ "FrameRouting" BO_ 603 "";
BA_ "VFrameFormat" BO_ 603 14;
BA_ "GenMsgCycleTime" BO_ 602 100;
BA_ "GenMsgSendType" BO_ 602 0;
BA_ "FrameRouting" BO_ 602 "";
BA_ "VFrameFormat" BO_ 602 14;
BA_ "GenMsgCycleTime" BO_ 1152 1000;
BA_ "GenMsgSendType" BO_ 1152 5;
BA_ "FrameRouting" BO_ 1152 "";
BA_ "VFrameFormat" BO_ 1152 14;
BA_ "GenMsgCycleTime" BO_ 872 100;
BA_ "GenMsgSendType" BO_ 872 0;
BA_ "FrameRouting" BO_ 872 "";
BA_ "VFrameFormat" BO_ 872 14;
BA_ "GenMsgDelayTime" BO_ 560 10;
BA_ "GenMsgCycleTime" BO_ 560 20;
BA_ "GenMsgSendType" BO_ 560 0;
BA_ "FrameRouting" BO_ 560 "";
BA_ "VFrameFormat" BO_ 560 14;
BA_ "GenMsgDelayTime" BO_ 369 10;
BA_ "GenMsgCycleTime" BO_ 369 30;
BA_ "GenMsgSendType" BO_ 369 0;
BA_ "FrameRouting" BO_ 369 "";
BA_ "VFrameFormat" BO_ 369 14;
BA_ "GenMsgCycleTime" BO_ 92 100;
BA_ "GenMsgSendType" BO_ 92 5;
BA_ "FrameRouting" BO_ 92 "";
BA_ "VFrameFormat" BO_ 92 14;
BA_ "NetworkInitialization" BO_ 2030 0;
BA_ "GenMsgDelayTime" BO_ 2030 0;
BA_ "GenMsgSendType" BO_ 2030 1;
BA_ "DiagResponse" BO_ 2030 1;
BA_ "GenMsgILSupport" BO_ 2030 0;
BA_ "FrameRouting" BO_ 2030 "";
BA_ "VFrameFormat" BO_ 2030 14;
BA_ "GenMsgCycleTime" BO_ 1087 1000;
BA_ "GenMsgSendType" BO_ 1087 5;
BA_ "FrameRouting" BO_ 1087 "";
BA_ "VFrameFormat" BO_ 1087 14;
BA_ "GenMsgCycleTime" BO_ 332 200;
BA_ "GenMsgSendType" BO_ 332 0;
BA_ "FrameRouting" BO_ 332 "";
BA_ "VFrameFormat" BO_ 332 14;
BA_ "NetworkInitialization" BO_ 1896 0;
BA_ "GenMsgDelayTime" BO_ 1896 0;
BA_ "GenMsgSendType" BO_ 1896 1;
BA_ "DiagResponse" BO_ 1896 1;
BA_ "GenMsgILSupport" BO_ 1896 0;
BA_ "FrameRouting" BO_ 1896 "";
BA_ "VFrameFormat" BO_ 1896 14;
BA_ "NetworkInitialization" BO_ 1889 0;
BA_ "GenMsgDelayTime" BO_ 1889 0;
BA_ "GenMsgSendType" BO_ 1889 1;
BA_ "DiagRequest" BO_ 1889 1;
BA_ "GenMsgILSupport" BO_ 1889 0;
BA_ "FrameRouting" BO_ 1889 "";
BA_ "VFrameFormat" BO_ 1889 14;
BA_ "NetworkInitialization" BO_ 1888 0;
BA_ "GenMsgDelayTime" BO_ 1888 0;
BA_ "GenMsgSendType" BO_ 1888 1;
BA_ "DiagRequest" BO_ 1888 1;
BA_ "GenMsgILSupport" BO_ 1888 0;
BA_ "FrameRouting" BO_ 1888 "";
BA_ "VFrameFormat" BO_ 1888 14;
BA_ "NetworkInitialization" BO_ 1848 0;
BA_ "GenMsgDelayTime" BO_ 1848 0;
BA_ "GenMsgSendType" BO_ 1848 1;
BA_ "DiagResponse" BO_ 1848 1;
BA_ "GenMsgILSupport" BO_ 1848 0;
BA_ "FrameRouting" BO_ 1848 "";
BA_ "VFrameFormat" BO_ 1848 14;
BA_ "NetworkInitialization" BO_ 1840 0;
BA_ "GenMsgDelayTime" BO_ 1840 0;
BA_ "GenMsgSendType" BO_ 1840 1;
BA_ "DiagRequest" BO_ 1840 1;
BA_ "GenMsgILSupport" BO_ 1840 0;
BA_ "FrameRouting" BO_ 1840 "";
BA_ "VFrameFormat" BO_ 1840 14;
BA_ "NetworkInitialization" BO_ 1713 0;
BA_ "GenMsgSendType" BO_ 1713 1;
BA_ "TpApplType" BO_ 1713 "DiagUUDTResponse";
BA_ "GenMsgILSupport" BO_ 1713 0;
BA_ "FrameRouting" BO_ 1713 "";
BA_ "VFrameFormat" BO_ 1713 14;
BA_ "NetworkInitialization" BO_ 1712 0;
BA_ "GenMsgSendType" BO_ 1712 1;
BA_ "TpApplType" BO_ 1712 "DiagUUDTResponse";
BA_ "GenMsgILSupport" BO_ 1712 0;
BA_ "FrameRouting" BO_ 1712 "";
BA_ "VFrameFormat" BO_ 1712 14;
BA_ "NetworkInitialization" BO_ 2025 0;
BA_ "GenMsgDelayTime" BO_ 2025 0;
BA_ "GenMsgSendType" BO_ 2025 1;
BA_ "DiagResponse" BO_ 2025 1;
BA_ "GenMsgILSupport" BO_ 2025 0;
BA_ "FrameRouting" BO_ 2025 "";
BA_ "VFrameFormat" BO_ 2025 14;
BA_ "NetworkInitialization" BO_ 2024 0;
BA_ "GenMsgDelayTime" BO_ 2024 0;
BA_ "GenMsgSendType" BO_ 2024 1;
BA_ "DiagResponse" BO_ 2024 1;
BA_ "GenMsgILSupport" BO_ 2024 0;
BA_ "FrameRouting" BO_ 2024 "";
BA_ "VFrameFormat" BO_ 2024 14;
BA_ "NetworkInitialization" BO_ 2017 0;
BA_ "GenMsgDelayTime" BO_ 2017 0;
BA_ "GenMsgSendType" BO_ 2017 1;
BA_ "DiagRequest" BO_ 2017 1;
BA_ "GenMsgILSupport" BO_ 2017 0;
BA_ "FrameRouting" BO_ 2017 "";
BA_ "VFrameFormat" BO_ 2017 14;
BA_ "NetworkInitialization" BO_ 2016 0;
BA_ "GenMsgDelayTime" BO_ 2016 0;
BA_ "GenMsgSendType" BO_ 2016 1;
BA_ "DiagRequest" BO_ 2016 1;
BA_ "GenMsgILSupport" BO_ 2016 0;
BA_ "FrameRouting" BO_ 2016 "";
BA_ "VFrameFormat" BO_ 2016 14;
BA_ "NetworkInitialization" BO_ 2015 0;
BA_ "GenMsgDelayTime" BO_ 2015 0;
BA_ "GenMsgSendType" BO_ 2015 1;
BA_ "DiagState" BO_ 2015 1;
BA_ "GenMsgILSupport" BO_ 2015 0;
BA_ "FrameRouting" BO_ 2015 "";
BA_ "VFrameFormat" BO_ 2015 14;
BA_ "NetworkInitialization" BO_ 1897 0;
BA_ "GenMsgDelayTime" BO_ 1897 0;
BA_ "GenMsgSendType" BO_ 1897 1;
BA_ "DiagResponse" BO_ 1897 1;
BA_ "GenMsgILSupport" BO_ 1897 0;
BA_ "FrameRouting" BO_ 1897 "";
BA_ "VFrameFormat" BO_ 1897 14;
BA_ "NetworkInitialization" BO_ 1814 0;
BA_ "GenMsgDelayTime" BO_ 1814 0;
BA_ "GenMsgSendType" BO_ 1814 1;
BA_ "DiagRequest" BO_ 1814 1;
BA_ "GenMsgILSupport" BO_ 1814 0;
BA_ "FrameRouting" BO_ 1814 "";
BA_ "VFrameFormat" BO_ 1814 14;
BA_ "NetworkInitialization" BO_ 1701 0;
BA_ "GenMsgSendType" BO_ 1701 1;
BA_ "TpApplType" BO_ 1701 "DiagUUDTResponse";
BA_ "GenMsgILSupport" BO_ 1701 0;
BA_ "FrameRouting" BO_ 1701 "";
BA_ "VFrameFormat" BO_ 1701 14;
BA_ "NetworkInitialization" BO_ 1700 0;
BA_ "GenMsgSendType" BO_ 1700 1;
BA_ "TpApplType" BO_ 1700 "DiagUUDTResponse";
BA_ "GenMsgILSupport" BO_ 1700 0;
BA_ "FrameRouting" BO_ 1700 "";
BA_ "VFrameFormat" BO_ 1700 14;
BA_ "NetworkInitialization" BO_ 1697 0;
BA_ "GenMsgSendType" BO_ 1697 1;
BA_ "TpApplType" BO_ 1697 "DiagUUDTResponse";
BA_ "GenMsgILSupport" BO_ 1697 0;
BA_ "FrameRouting" BO_ 1697 "";
BA_ "VFrameFormat" BO_ 1697 14;
BA_ "NetworkInitialization" BO_ 1696 0;
BA_ "GenMsgSendType" BO_ 1696 1;
BA_ "TpApplType" BO_ 1696 "DiagUUDTResponse";
BA_ "GenMsgILSupport" BO_ 1696 0;
BA_ "FrameRouting" BO_ 1696 "";
BA_ "VFrameFormat" BO_ 1696 14;
BA_ "NetworkInitialization" BO_ 1429 0;
BA_ "GenMsgCycleTime" BO_ 1429 1000;
BA_ "GenMsgSendType" BO_ 1429 0;
BA_ "NmAsrMessage" BO_ 1429 1;
BA_ "GenMsgILSupport" BO_ 1429 0;
BA_ "FrameRouting" BO_ 1429 "";
BA_ "VFrameFormat" BO_ 1429 14;
BA_ "GenMsgCycleTime" BO_ 1100 100;
BA_ "GenMsgSendType" BO_ 1100 0;
BA_ "FrameRouting" BO_ 1100 "";
BA_ "VFrameFormat" BO_ 1100 14;
BA_ "U_P702_MY2021_Tx" SG_ 1461 PSCM_GWOnBoardTester 1;
BA_ "U_CX727_MY2021_Tx" SG_ 1461 PSCM_GWOnBoardTester 1;
BA_ "U_P702_MY2021_Rx" SG_ 1461 PSCM_GWOnBoardTester 1;
BA_ "GenSigStartValue" SG_ 1461 PSCM_GWOnBoardTester 255;
BA_ "ContentDependant" SG_ 1461 PSCM_GWOnBoardTester 1;
BA_ "GenSigStartValueInteger" SG_ 1461 PSCM_GWOnBoardTester 255;
BA_ "U_P702_MY2021_Tx" SG_ 1461 PSCM_GWNMProxy 1;
BA_ "U_CX727_MY2021_Tx" SG_ 1461 PSCM_GWNMProxy 1;
BA_ "U_P702_MY2021_Rx" SG_ 1461 PSCM_GWNMProxy 1;
BA_ "GenSigStartValue" SG_ 1461 PSCM_GWNMProxy 255;
BA_ "ContentDependant" SG_ 1461 PSCM_GWNMProxy 1;
BA_ "GenSigStartValueInteger" SG_ 1461 PSCM_GWNMProxy 255;
BA_ "U_P702_MY2021_Tx" SG_ 1461 PSCM_AutoSarNMReserved4 1;
BA_ "U_CX727_MY2021_Tx" SG_ 1461 PSCM_AutoSarNMReserved4 1;
BA_ "U_P702_MY2021_Rx" SG_ 1461 PSCM_AutoSarNMReserved4 1;
BA_ "GenSigStartValue" SG_ 1461 PSCM_AutoSarNMReserved4 255;
BA_ "ContentDependant" SG_ 1461 PSCM_AutoSarNMReserved4 1;
BA_ "GenSigStartValueInteger" SG_ 1461 PSCM_AutoSarNMReserved4 255;
BA_ "U_P702_MY2021_Tx" SG_ 1461 PSCM_AutoSarNMReserved3 1;
BA_ "U_CX727_MY2021_Tx" SG_ 1461 PSCM_AutoSarNMReserved3 1;
BA_ "U_P702_MY2021_Rx" SG_ 1461 PSCM_AutoSarNMReserved3 1;
BA_ "GenSigStartValue" SG_ 1461 PSCM_AutoSarNMReserved3 255;
BA_ "ContentDependant" SG_ 1461 PSCM_AutoSarNMReserved3 1;
BA_ "GenSigStartValueInteger" SG_ 1461 PSCM_AutoSarNMReserved3 255;
BA_ "U_P702_MY2021_Tx" SG_ 1461 PSCM_AutoSarNMReserved2 1;
BA_ "U_CX727_MY2021_Tx" SG_ 1461 PSCM_AutoSarNMReserved2 1;
BA_ "GenSigStartValue" SG_ 1461 PSCM_AutoSarNMReserved2 255;
BA_ "ContentDependant" SG_ 1461 PSCM_AutoSarNMReserved2 1;
BA_ "GenSigStartValueInteger" SG_ 1461 PSCM_AutoSarNMReserved2 255;
BA_ "U_P702_MY2021_Tx" SG_ 1461 PSCM_AutoSarNMReserved1 1;
BA_ "U_CX727_MY2021_Tx" SG_ 1461 PSCM_AutoSarNMReserved1 1;
BA_ "GenSigStartValue" SG_ 1461 PSCM_AutoSarNMReserved1 255;
BA_ "ContentDependant" SG_ 1461 PSCM_AutoSarNMReserved1 1;
BA_ "GenSigStartValueInteger" SG_ 1461 PSCM_AutoSarNMReserved1 255;
BA_ "U_P702_MY2021_Tx" SG_ 1461 PSCM_AutoSarNMNodeId 1;
BA_ "U_CX727_MY2021_Tx" SG_ 1461 PSCM_AutoSarNMNodeId 1;
BA_ "GenSigStartValue" SG_ 1461 PSCM_AutoSarNMNodeId 181;
BA_ "ContentDependant" SG_ 1461 PSCM_AutoSarNMNodeId 1;
BA_ "GenSigStartValueInteger" SG_ 1461 PSCM_AutoSarNMNodeId 181;
BA_ "U_P702_MY2021_Tx" SG_ 1461 PSCM_AutoSarNMControl 1;
BA_ "U_CX727_MY2021_Tx" SG_ 1461 PSCM_AutoSarNMControl 1;
BA_ "ContentDependant" SG_ 1461 PSCM_AutoSarNMControl 1;
BA_ "U_P702_MY2021_Tx" SG_ 1047 TrlrAnOffst_An2_Calc 1;
BA_ "GenSigStartValueInteger" SG_ 1047 TrlrAnOffst_An2_Calc 128;
BA_ "U_P702_MY2021_Tx" SG_ 1047 TrlrAn_An_WarnCalc 1;
BA_ "U_P702_MY2021_Tx" SG_ 1047 TrlrAn_An_MxCalc 1;
BA_ "U_P702_MY2021_Tx" SG_ 1047 TrlrAidTrlrId_No_Rq 1;
BA_ "U_P702_MY2021_Tx" SG_ 1047 TrlrAidTrgtId_No_Rq 1;
BA_ "U_P702_MY2021_Tx" SG_ 1047 TrlrAidSetup_D2_Stat 1;
BA_ "U_P702_MY2021_Tx" SG_ 1047 TrlrAidEnbl_D2_Stat 1;
BA_ "U_T6_MCA_MY2020_Rx" SG_ 1047 TrlrAidEnbl_D2_Stat 1;
BA_ "U_P702_MY2021_Rx" SG_ 1047 TrlrAidEnbl_D2_Stat 1;
BA_ "GenSigSendType" SG_ 1047 TrlrAidEnbl_D2_Stat 3;
BA_ "U_P702_MY2021_Tx" SG_ 1047 TrlrAidMsgTxt_D2_Rq 1;
BA_ "U_P702_MY2021_Rx" SG_ 1047 TrlrAidMsgTxt_D2_Rq 1;
BA_ "GenSigSendType" SG_ 1047 TrlrAidMsgTxt_D2_Rq 3;
BA_ "U_P702_MY2021_Tx" SG_ 1047 EsaOn_B_Stat 1;
BA_ "U_CX727_MY2021_Tx" SG_ 1047 EsaOn_B_Stat 1;
BA_ "GenSigSendType" SG_ 1047 EsaOn_B_Stat 3;
BA_ "GenSigStartValue" SG_ 1047 EsaOn_B_Stat 1;
BA_ "GenSigStartValueInteger" SG_ 1047 EsaOn_B_Stat 1;
BA_ "U_P702_MY2021_Tx" SG_ 1047 HitchToTrlrAxle_L_Calc 1;
BA_ "U_P702_MY2021_Tx" SG_ 1047 SelDrvMdeSte_D_Stat 1;
BA_ "U_CX727_MY2021_Tx" SG_ 1047 SelDrvMdeSte_D_Stat 1;
BA_ "U_P702_MY2021_Rx" SG_ 1047 SelDrvMdeSte_D_Stat 1;
BA_ "U_CX727_MY2021_Rx" SG_ 1047 SelDrvMdeSte_D_Stat 1;
BA_ "GenSigSendType" SG_ 1047 SelDrvMdeSte_D_Stat 3;
BA_ "U_P702_MY2021_Tx" SG_ 972 LatCtlSte_D_Stat 1;
BA_ "U_CX727_MY2021_Tx" SG_ 972 LatCtlSte_D_Stat 1;
BA_ "GenSigSendType" SG_ 972 LatCtlSte_D_Stat 3;
BA_ "U_P702_MY2021_Tx" SG_ 972 LatCtlLim_D_Stat 1;
BA_ "U_CX727_MY2021_Tx" SG_ 972 LatCtlLim_D_Stat 1;
BA_ "GenSigSendType" SG_ 972 LatCtlLim_D_Stat 3;
BA_ "MetaData" SG_ 972 LatCtlCpbltyDStat_No_Cnt 1;
BA_ "MetaData" SG_ 972 LatCtlCpbltyDStat_No_Cs 1;
BA_ "U_P702_MY2021_Tx" SG_ 972 TrlrAn_An_TrgtCalc 1;
BA_ "GenSigStartValueInteger" SG_ 972 TrlrAn_An_TrgtCalc 128;
BA_ "U_P702_MY2021_Tx" SG_ 972 LsmcBrkDecelEnbl_D_Rq 1;
BA_ "U_P702_MY2021_Rx" SG_ 972 LsmcBrkDecelEnbl_D_Rq 1;
BA_ "U_P702_MY2021_Tx" SG_ 972 TjaHandsOnCnfdnc_B_Est 1;
BA_ "U_CX727_MY2021_Tx" SG_ 972 TjaHandsOnCnfdnc_B_Est 1;
BA_ "GenSigStartValue" SG_ 972 TjaHandsOnCnfdnc_B_Est 1;
BA_ "GenSigStartValueInteger" SG_ 972 TjaHandsOnCnfdnc_B_Est 1;
BA_ "U_P702_MY2021_Tx" SG_ 972 LaHandsOff_B_Actl 1;
BA_ "U_CX727_MY2021_Tx" SG_ 972 LaHandsOff_B_Actl 1;
BA_ "GenSigStartValue" SG_ 972 LaHandsOff_B_Actl 1;
BA_ "GenSigStartValueInteger" SG_ 972 LaHandsOff_B_Actl 1;
BA_ "CrossOver_InfoCAN" SG_ 972 LaHandsOff_B_Actl 1;
BA_ "U_P702_MY2021_Tx" SG_ 972 LaActDeny_B_Actl 1;
BA_ "U_CX727_MY2021_Tx" SG_ 972 LaActDeny_B_Actl 1;
BA_ "CrossOver_InfoCAN" SG_ 972 LaActDeny_B_Actl 1;
BA_ "U_P702_MY2021_Tx" SG_ 972 LaActAvail_D_Actl 1;
BA_ "U_CX727_MY2021_Tx" SG_ 972 LaActAvail_D_Actl 1;
BA_ "CrossOver_InfoCAN" SG_ 972 LaActAvail_D_Actl 1;
BA_ "U_P702_MY2021_Tx" SG_ 972 LsmcBrk_Tq_Rq 1;
BA_ "U_P702_MY2021_Rx" SG_ 972 LsmcBrk_Tq_Rq 1;
BA_ "U_P702_MY2021_Tx" SG_ 130 TrlrHitchLamp_D_Rqst 1;
BA_ "CrossOver_InfoCAN" SG_ 130 TrlrHitchLamp_D_Rqst 1;
BA_ "U_P702_MY2021_Tx" SG_ 130 VehVTrlrAid_B_Rq 1;
BA_ "U_T6_MCA_MY2020_Rx" SG_ 130 VehVTrlrAid_B_Rq 1;
BA_ "U_P702_MY2021_Rx" SG_ 130 VehVTrlrAid_B_Rq 1;
BA_ "CrossOver_InfoCAN" SG_ 130 VehVTrlrAid_B_Rq 1;
BA_ "U_P702_MY2021_Tx" SG_ 130 Veh_V_RqMxTrlrAid 1;
BA_ "U_T6_MCA_MY2020_Rx" SG_ 130 Veh_V_RqMxTrlrAid 1;
BA_ "U_P702_MY2021_Rx" SG_ 130 Veh_V_RqMxTrlrAid 1;
BA_ "GenSigStartValue" SG_ 130 Veh_V_RqMxTrlrAid 255;
BA_ "GenSigStartValueInteger" SG_ 130 Veh_V_RqMxTrlrAid 255;
BA_ "U_P702_MY2021_Tx" SG_ 130 DrvSteActv_B_Stat 1;
BA_ "U_P702_MY2021_Rx" SG_ 130 DrvSteActv_B_Stat 1;
BA_ "U_P702_MY2021_Tx" SG_ 130 DrvSte_Tq_Actl 1;
BA_ "U_P702_MY2021_Rx" SG_ 130 DrvSte_Tq_Actl 1;
BA_ "GenSigStartValueInteger" SG_ 130 DrvSte_Tq_Actl 128;
BA_ "U_P702_MY2021_Tx" SG_ 130 SteMdule_D_Stat 1;
BA_ "U_CX727_MY2021_Tx" SG_ 130 SteMdule_D_Stat 1;
BA_ "U_P702_MY2021_Tx" SG_ 130 SteMdule_U_Meas 1;
BA_ "U_CX727_MY2021_Tx" SG_ 130 SteMdule_U_Meas 1;
BA_ "GenSigStartValue" SG_ 130 SteMdule_U_Meas 255;
BA_ "GenSigStartValueInteger" SG_ 130 SteMdule_U_Meas 255;
BA_ "U_P702_MY2021_Tx" SG_ 130 SteMdule_I_Est 1;
BA_ "U_CX727_MY2021_Tx" SG_ 130 SteMdule_I_Est 1;
BA_ "GenSigStartValue" SG_ 130 SteMdule_I_Est 4095;
BA_ "GenSigStartValueInteger" SG_ 130 SteMdule_I_Est 4095;
BA_ "U_P702_MY2021_Tx" SG_ 130 EPAS_Failure 1;
BA_ "U_CX727_MY2021_Tx" SG_ 130 EPAS_Failure 1;
BA_ "CrossOver_InfoCAN" SG_ 130 EPAS_Failure 1;
BA_ "U_P702_MY2021_Tx" SG_ 130 SteeringColumnTorque 1;
BA_ "U_CX727_MY2021_Tx" SG_ 130 SteeringColumnTorque 1;
BA_ "U_P702_MY2021_Rx" SG_ 130 SteeringColumnTorque 1;
BA_ "U_CX727_MY2021_Rx" SG_ 130 SteeringColumnTorque 1;
BA_ "GenSigStartValue" SG_ 130 SteeringColumnTorque 254;
BA_ "GenSigStartValueInteger" SG_ 130 SteeringColumnTorque 254;
BA_ "U_P702_MY2021_Tx" SG_ 130 SAPPAngleControlStat6 1;
BA_ "U_CX727_MY2021_Tx" SG_ 130 SAPPAngleControlStat6 1;
BA_ "U_P702_MY2021_Tx" SG_ 130 SAPPAngleControlStat5 1;
BA_ "U_CX727_MY2021_Tx" SG_ 130 SAPPAngleControlStat5 1;
BA_ "U_P702_MY2021_Tx" SG_ 130 SAPPAngleControlStat4 1;
BA_ "U_CX727_MY2021_Tx" SG_ 130 SAPPAngleControlStat4 1;
BA_ "U_P702_MY2021_Tx" SG_ 130 SAPPAngleControlStat3 1;
BA_ "U_CX727_MY2021_Tx" SG_ 130 SAPPAngleControlStat3 1;
BA_ "U_P702_MY2021_Tx" SG_ 130 SAPPAngleControlStat2 1;
BA_ "U_CX727_MY2021_Tx" SG_ 130 SAPPAngleControlStat2 1;
BA_ "U_P702_MY2021_Tx" SG_ 130 SAPPAngleControlStat1 1;
BA_ "U_CX727_MY2021_Tx" SG_ 130 SAPPAngleControlStat1 1;
BA_ "U_P702_MY2021_Tx" SG_ 126 StePw_B_Rq 1;
BA_ "U_T6_MCA_MY2020_Rx" SG_ 126 StePw_B_Rq 1;
BA_ "U_P702_MY2021_Rx" SG_ 126 StePw_B_Rq 1;
BA_ "U_P702_MY2021_Tx" SG_ 126 StePinRelInit_An_Sns 1;
BA_ "U_CX727_MY2021_Tx" SG_ 126 StePinRelInit_An_Sns 1;
BA_ "U_T6_MCA_MY2020_Rx" SG_ 126 StePinRelInit_An_Sns 1;
BA_ "U_CX727_MY2021_Rx" SG_ 126 StePinRelInit_An_Sns 1;
BA_ "U_P702_MY2021_Rx" SG_ 126 StePinRelInit_An_Sns 1;
BA_ "GenSigStartValue" SG_ 126 StePinRelInit_An_Sns 65535;
BA_ "ContentDependant" SG_ 126 StePinRelInit_An_Sns 1;
BA_ "GenSigStartValueInteger" SG_ 126 StePinRelInit_An_Sns 65535;
BA_ "ECGUsedRxSignal" SG_ 126 StePinCompAnEst_D_Qf 1;
BA_ "U_P702_MY2021_Tx" SG_ 126 StePinCompAnEst_D_Qf 1;
BA_ "U_CX727_MY2021_Tx" SG_ 126 StePinCompAnEst_D_Qf 1;
BA_ "U_T6_MCA_MY2020_Rx" SG_ 126 StePinCompAnEst_D_Qf 1;
BA_ "U_CX727_MY2021_Rx" SG_ 126 StePinCompAnEst_D_Qf 1;
BA_ "U_P702_MY2021_Rx" SG_ 126 StePinCompAnEst_D_Qf 1;
BA_ "GenSigStartValue" SG_ 126 StePinCompAnEst_D_Qf 1;
BA_ "GenSigStartValueInteger" SG_ 126 StePinCompAnEst_D_Qf 1;
BA_ "CrossOver_InfoCAN" SG_ 126 StePinCompAnEst_D_Qf 1;
BA_ "ECGUsedRxSignal" SG_ 126 StePinComp_An_Est 1;
BA_ "U_P702_MY2021_Tx" SG_ 126 StePinComp_An_Est 1;
BA_ "U_CX727_MY2021_Tx" SG_ 126 StePinComp_An_Est 1;
BA_ "U_T6_MCA_MY2020_Rx" SG_ 126 StePinComp_An_Est 1;
BA_ "U_CX727_MY2021_Rx" SG_ 126 StePinComp_An_Est 1;
BA_ "U_P702_MY2021_Rx" SG_ 126 StePinComp_An_Est 1;
BA_ "GenSigStartValueInteger" SG_ 126 StePinComp_An_Est 16000;
BA_ "U_P702_MY2021_Tx" SG_ 126 StePinAn_No_Cs 1;
BA_ "U_CX727_MY2021_Tx" SG_ 126 StePinAn_No_Cs 1;
BA_ "U_CX727_MY2021_Rx" SG_ 126 StePinAn_No_Cs 1;
BA_ "U_P702_MY2021_Rx" SG_ 126 StePinAn_No_Cs 1;
BA_ "MetaData" SG_ 126 StePinAn_No_Cs 1;
BA_ "ContentDependant" SG_ 126 StePinAn_No_Cs 1;
BA_ "U_P702_MY2021_Tx" SG_ 126 StePinAn_No_Cnt 1;
BA_ "U_CX727_MY2021_Tx" SG_ 126 StePinAn_No_Cnt 1;
BA_ "U_CX727_MY2021_Rx" SG_ 126 StePinAn_No_Cnt 1;
BA_ "U_P702_MY2021_Rx" SG_ 126 StePinAn_No_Cnt 1;
BA_ "MetaData" SG_ 126 StePinAn_No_Cnt 1;
BA_ "CrossOver_InfoCAN" SG_ 126 StePinAn_No_Cnt 1;
BA_ "U_P702_MY2021_Tx" SG_ 1430 ABS_GWOnBoardTester 1;
BA_ "U_CX727_MY2021_Tx" SG_ 1430 ABS_GWOnBoardTester 1;
BA_ "GenSigStartValue" SG_ 1430 ABS_GWOnBoardTester 255;
BA_ "ContentDependant" SG_ 1430 ABS_GWOnBoardTester 1;
BA_ "GenSigStartValueInteger" SG_ 1430 ABS_GWOnBoardTester 255;
BA_ "U_P702_MY2021_Tx" SG_ 1430 ABS_GWNMProxy 1;
BA_ "U_CX727_MY2021_Tx" SG_ 1430 ABS_GWNMProxy 1;
BA_ "GenSigStartValue" SG_ 1430 ABS_GWNMProxy 255;
BA_ "ContentDependant" SG_ 1430 ABS_GWNMProxy 1;
BA_ "GenSigStartValueInteger" SG_ 1430 ABS_GWNMProxy 255;
BA_ "U_P702_MY2021_Tx" SG_ 1430 ABS_AutoSarNMReserved4 1;
BA_ "U_CX727_MY2021_Tx" SG_ 1430 ABS_AutoSarNMReserved4 1;
BA_ "GenSigStartValue" SG_ 1430 ABS_AutoSarNMReserved4 255;
BA_ "ContentDependant" SG_ 1430 ABS_AutoSarNMReserved4 1;
BA_ "GenSigStartValueInteger" SG_ 1430 ABS_AutoSarNMReserved4 255;
BA_ "U_P702_MY2021_Tx" SG_ 1430 ABS_AutoSarNMReserved3 1;
BA_ "U_CX727_MY2021_Tx" SG_ 1430 ABS_AutoSarNMReserved3 1;
BA_ "GenSigStartValue" SG_ 1430 ABS_AutoSarNMReserved3 255;
BA_ "ContentDependant" SG_ 1430 ABS_AutoSarNMReserved3 1;
BA_ "GenSigStartValueInteger" SG_ 1430 ABS_AutoSarNMReserved3 255;
BA_ "U_P702_MY2021_Tx" SG_ 1430 ABS_AutoSarNMReserved2 1;
BA_ "U_CX727_MY2021_Tx" SG_ 1430 ABS_AutoSarNMReserved2 1;
BA_ "GenSigStartValue" SG_ 1430 ABS_AutoSarNMReserved2 255;
BA_ "ContentDependant" SG_ 1430 ABS_AutoSarNMReserved2 1;
BA_ "GenSigStartValueInteger" SG_ 1430 ABS_AutoSarNMReserved2 255;
BA_ "U_P702_MY2021_Tx" SG_ 1430 ABS_AutoSarNMReserved1 1;
BA_ "U_CX727_MY2021_Tx" SG_ 1430 ABS_AutoSarNMReserved1 1;
BA_ "GenSigStartValue" SG_ 1430 ABS_AutoSarNMReserved1 255;
BA_ "ContentDependant" SG_ 1430 ABS_AutoSarNMReserved1 1;
BA_ "GenSigStartValueInteger" SG_ 1430 ABS_AutoSarNMReserved1 255;
BA_ "U_P702_MY2021_Tx" SG_ 1430 ABS_AutoSarNMNodeId 1;
BA_ "U_CX727_MY2021_Tx" SG_ 1430 ABS_AutoSarNMNodeId 1;
BA_ "GenSigStartValue" SG_ 1430 ABS_AutoSarNMNodeId 150;
BA_ "ContentDependant" SG_ 1430 ABS_AutoSarNMNodeId 1;
BA_ "GenSigStartValueInteger" SG_ 1430 ABS_AutoSarNMNodeId 150;
BA_ "U_P702_MY2021_Tx" SG_ 1430 ABS_AutoSarNMControl 1;
BA_ "U_CX727_MY2021_Tx" SG_ 1430 ABS_AutoSarNMControl 1;
BA_ "ContentDependant" SG_ 1430 ABS_AutoSarNMControl 1;
BA_ "U_P702_MY2021_Tx" SG_ 1200 HsaTrnAout_Tq_Rq 1;
BA_ "U_CX727_MY2021_Tx" SG_ 1200 HsaTrnAout_Tq_Rq 1;
BA_ "GenSigStartValueInteger" SG_ 1200 HsaTrnAout_Tq_Rq 32768;
BA_ "U_P702_MY2021_Tx" SG_ 1200 BrkBstrVac_P_Actl 1;
BA_ "U_CX727_MY2021_Tx" SG_ 1200 BrkBstrVac_P_Actl 1;
BA_ "U_T6_MCA_MY2020_Rx" SG_ 1200 BrkBstrVac_P_Actl 1;
BA_ "U_P702_MY2021_Rx" SG_ 1200 BrkBstrVac_P_Actl 1;
BA_ "GenSigStartValue" SG_ 1200 BrkBstrVac_P_Actl 127;
BA_ "GenSigStartValueInteger" SG_ 1200 BrkBstrVac_P_Actl 127;
BA_ "U_P702_MY2021_Tx" SG_ 1200 YawStabilityIndex 1;
BA_ "U_CX727_MY2021_Tx" SG_ 1200 YawStabilityIndex 1;
BA_ "U_P702_MY2021_Rx" SG_ 1200 YawStabilityIndex 1;
BA_ "U_CX727_MY2021_Rx" SG_ 1200 YawStabilityIndex 1;
BA_ "GenSigStartValueInteger" SG_ 1200 YawStabilityIndex 256;
BA_ "U_P702_MY2021_Tx" SG_ 1200 BrkTot_Tq_RqDrv 1;
BA_ "U_CX727_MY2021_Tx" SG_ 1200 BrkTot_Tq_RqDrv 1;
BA_ "U_T6_MCA_MY2020_Rx" SG_ 1200 BrkTot_Tq_RqDrv 1;
BA_ "U_P702_MY2021_Rx" SG_ 1200 BrkTot_Tq_RqDrv 1;
BA_ "U_P702_MY2021_Tx" SG_ 1200 BrkTotTqRqDrv_No_Cnt 1;
BA_ "U_CX727_MY2021_Tx" SG_ 1200 BrkTotTqRqDrv_No_Cnt 1;
BA_ "U_T6_MCA_MY2020_Rx" SG_ 1200 BrkTotTqRqDrv_No_Cnt 1;
BA_ "U_P702_MY2021_Rx" SG_ 1200 BrkTotTqRqDrv_No_Cnt 1;
BA_ "MetaData" SG_ 1200 BrkTotTqRqDrv_No_Cnt 1;
BA_ "U_P702_MY2021_Tx" SG_ 1200 BrkTotTqRqDrv_No_Cs 1;
BA_ "U_CX727_MY2021_Tx" SG_ 1200 BrkTotTqRqDrv_No_Cs 1;
BA_ "U_T6_MCA_MY2020_Rx" SG_ 1200 BrkTotTqRqDrv_No_Cs 1;
BA_ "U_P702_MY2021_Rx" SG_ 1200 BrkTotTqRqDrv_No_Cs 1;
BA_ "MetaData" SG_ 1200 BrkTotTqRqDrv_No_Cs 1;
BA_ "U_P702_MY2021_Tx" SG_ 1200 HsaStat_D_Dsply 1;
BA_ "U_CX727_MY2021_Tx" SG_ 1200 HsaStat_D_Dsply 1;
BA_ "U_P702_MY2021_Tx" SG_ 1102 SelDrvMdePos12_D_Stat 1;
BA_ "U_CX727_MY2021_Tx" SG_ 1102 SelDrvMdePos12_D_Stat 1;
BA_ "GenSigSendType" SG_ 1102 SelDrvMdePos12_D_Stat 3;
BA_ "GenSigStartValue" SG_ 1102 SelDrvMdePos12_D_Stat 31;
BA_ "GenSigStartValueInteger" SG_ 1102 SelDrvMdePos12_D_Stat 31;
BA_ "U_P702_MY2021_Tx" SG_ 1102 SelDrvMdePos11_D_Stat 1;
BA_ "U_CX727_MY2021_Tx" SG_ 1102 SelDrvMdePos11_D_Stat 1;
BA_ "GenSigSendType" SG_ 1102 SelDrvMdePos11_D_Stat 3;
BA_ "GenSigStartValue" SG_ 1102 SelDrvMdePos11_D_Stat 31;
BA_ "GenSigStartValueInteger" SG_ 1102 SelDrvMdePos11_D_Stat 31;
BA_ "U_P702_MY2021_Tx" SG_ 1102 SelDrvMdePos10_D_Stat 1;
BA_ "U_CX727_MY2021_Tx" SG_ 1102 SelDrvMdePos10_D_Stat 1;
BA_ "GenSigSendType" SG_ 1102 SelDrvMdePos10_D_Stat 3;
BA_ "GenSigStartValue" SG_ 1102 SelDrvMdePos10_D_Stat 31;
BA_ "GenSigStartValueInteger" SG_ 1102 SelDrvMdePos10_D_Stat 31;
BA_ "U_P702_MY2021_Tx" SG_ 1102 SelDrvMdePos09_D_Stat 1;
BA_ "U_CX727_MY2021_Tx" SG_ 1102 SelDrvMdePos09_D_Stat 1;
BA_ "GenSigSendType" SG_ 1102 SelDrvMdePos09_D_Stat 3;
BA_ "GenSigStartValue" SG_ 1102 SelDrvMdePos09_D_Stat 31;
BA_ "GenSigStartValueInteger" SG_ 1102 SelDrvMdePos09_D_Stat 31;
BA_ "U_P702_MY2021_Tx" SG_ 1102 SelDrvMdePos08_D_Stat 1;
BA_ "U_CX727_MY2021_Tx" SG_ 1102 SelDrvMdePos08_D_Stat 1;
BA_ "GenSigSendType" SG_ 1102 SelDrvMdePos08_D_Stat 3;
BA_ "GenSigStartValue" SG_ 1102 SelDrvMdePos08_D_Stat 31;
BA_ "GenSigStartValueInteger" SG_ 1102 SelDrvMdePos08_D_Stat 31;
BA_ "U_P702_MY2021_Tx" SG_ 1102 SelDrvMdePos07_D_Stat 1;
BA_ "U_CX727_MY2021_Tx" SG_ 1102 SelDrvMdePos07_D_Stat 1;
BA_ "GenSigSendType" SG_ 1102 SelDrvMdePos07_D_Stat 3;
BA_ "GenSigStartValue" SG_ 1102 SelDrvMdePos07_D_Stat 31;
BA_ "GenSigStartValueInteger" SG_ 1102 SelDrvMdePos07_D_Stat 31;
BA_ "U_P702_MY2021_Tx" SG_ 1102 SelDrvMdePos06_D_Stat 1;
BA_ "U_CX727_MY2021_Tx" SG_ 1102 SelDrvMdePos06_D_Stat 1;
BA_ "GenSigSendType" SG_ 1102 SelDrvMdePos06_D_Stat 3;
BA_ "GenSigStartValue" SG_ 1102 SelDrvMdePos06_D_Stat 31;
BA_ "GenSigStartValueInteger" SG_ 1102 SelDrvMdePos06_D_Stat 31;
BA_ "U_P702_MY2021_Tx" SG_ 1102 SelDrvMdePos05_D_Stat 1;
BA_ "U_CX727_MY2021_Tx" SG_ 1102 SelDrvMdePos05_D_Stat 1;
BA_ "GenSigSendType" SG_ 1102 SelDrvMdePos05_D_Stat 3;
BA_ "GenSigStartValue" SG_ 1102 SelDrvMdePos05_D_Stat 31;
BA_ "GenSigStartValueInteger" SG_ 1102 SelDrvMdePos05_D_Stat 31;
BA_ "U_P702_MY2021_Tx" SG_ 1102 SelDrvMdePos04_D_Stat 1;
BA_ "U_CX727_MY2021_Tx" SG_ 1102 SelDrvMdePos04_D_Stat 1;
BA_ "GenSigSendType" SG_ 1102 SelDrvMdePos04_D_Stat 3;
BA_ "GenSigStartValue" SG_ 1102 SelDrvMdePos04_D_Stat 31;
BA_ "GenSigStartValueInteger" SG_ 1102 SelDrvMdePos04_D_Stat 31;
BA_ "U_P702_MY2021_Tx" SG_ 1102 SelDrvMdePos03_D_Stat 1;
BA_ "U_CX727_MY2021_Tx" SG_ 1102 SelDrvMdePos03_D_Stat 1;
BA_ "GenSigSendType" SG_ 1102 SelDrvMdePos03_D_Stat 3;
BA_ "GenSigStartValue" SG_ 1102 SelDrvMdePos03_D_Stat 31;
BA_ "GenSigStartValueInteger" SG_ 1102 SelDrvMdePos03_D_Stat 31;
BA_ "U_P702_MY2021_Tx" SG_ 1102 SelDrvMdePos02_D_Stat 1;
BA_ "U_CX727_MY2021_Tx" SG_ 1102 SelDrvMdePos02_D_Stat 1;
BA_ "GenSigSendType" SG_ 1102 SelDrvMdePos02_D_Stat 3;
BA_ "GenSigStartValue" SG_ 1102 SelDrvMdePos02_D_Stat 31;
BA_ "GenSigStartValueInteger" SG_ 1102 SelDrvMdePos02_D_Stat 31;
BA_ "U_P702_MY2021_Tx" SG_ 1102 SelDrvMdePos01_D_Stat 1;
BA_ "U_CX727_MY2021_Tx" SG_ 1102 SelDrvMdePos01_D_Stat 1;
BA_ "GenSigSendType" SG_ 1102 SelDrvMdePos01_D_Stat 3;
BA_ "GenSigStartValue" SG_ 1102 SelDrvMdePos01_D_Stat 31;
BA_ "GenSigStartValueInteger" SG_ 1102 SelDrvMdePos01_D_Stat 31;
BA_ "U_U55X_MY2022_Tx" SG_ 1056 SelDrvMdeHmi03_D_Rq 1;
BA_ "U_CD542_MY2021_Tx" SG_ 1056 SelDrvMdeHmi03_D_Rq 1;
BA_ "U_T6_MCA_MY2020_Tx" SG_ 1056 SelDrvMdeHmi03_D_Rq 1;
BA_ "GenSigSendType" SG_ 1056 SelDrvMdeHmi03_D_Rq 3;
BA_ "GenSigSendType" SG_ 1056 AutoEpbMsgTxt_D_Rq 3;
BA_ "GenSigSendType" SG_ 1056 AutoEpbDsply_D_Stat 3;
BA_ "GenSigSendType" SG_ 1056 AutoEpbButtnOn_B_Stat 3;
BA_ "U_P702_MY2021_Tx" SG_ 1056 SelDrvMdePos12_B_Avail 1;
BA_ "U_CX727_MY2021_Tx" SG_ 1056 SelDrvMdePos12_B_Avail 1;
BA_ "GenSigSendType" SG_ 1056 SelDrvMdePos12_B_Avail 3;
BA_ "U_P702_MY2021_Tx" SG_ 1056 SelDrvMdePos11_B_Avail 1;
BA_ "U_CX727_MY2021_Tx" SG_ 1056 SelDrvMdePos11_B_Avail 1;
BA_ "GenSigSendType" SG_ 1056 SelDrvMdePos11_B_Avail 3;
BA_ "U_P702_MY2021_Tx" SG_ 1056 SelDrvMdePos10_B_Avail 1;
BA_ "U_CX727_MY2021_Tx" SG_ 1056 SelDrvMdePos10_B_Avail 1;
BA_ "GenSigSendType" SG_ 1056 SelDrvMdePos10_B_Avail 3;
BA_ "U_P702_MY2021_Tx" SG_ 1056 SelDrvMdePos09_B_Avail 1;
BA_ "U_CX727_MY2021_Tx" SG_ 1056 SelDrvMdePos09_B_Avail 1;
BA_ "GenSigSendType" SG_ 1056 SelDrvMdePos09_B_Avail 3;
BA_ "U_P702_MY2021_Tx" SG_ 1056 SelDrvMdePos08_B_Avail 1;
BA_ "U_CX727_MY2021_Tx" SG_ 1056 SelDrvMdePos08_B_Avail 1;
BA_ "GenSigSendType" SG_ 1056 SelDrvMdePos08_B_Avail 3;
BA_ "U_P702_MY2021_Tx" SG_ 1056 SelDrvMdePos07_B_Avail 1;
BA_ "U_CX727_MY2021_Tx" SG_ 1056 SelDrvMdePos07_B_Avail 1;
BA_ "GenSigSendType" SG_ 1056 SelDrvMdePos07_B_Avail 3;
BA_ "U_P702_MY2021_Tx" SG_ 1056 SelDrvMdePos06_B_Avail 1;
BA_ "U_CX727_MY2021_Tx" SG_ 1056 SelDrvMdePos06_B_Avail 1;
BA_ "GenSigSendType" SG_ 1056 SelDrvMdePos06_B_Avail 3;
BA_ "U_P702_MY2021_Tx" SG_ 1056 SelDrvMdePos05_B_Avail 1;
BA_ "U_CX727_MY2021_Tx" SG_ 1056 SelDrvMdePos05_B_Avail 1;
BA_ "GenSigSendType" SG_ 1056 SelDrvMdePos05_B_Avail 3;
BA_ "U_P702_MY2021_Tx" SG_ 1056 SelDrvMdePos04_B_Avail 1;
BA_ "U_CX727_MY2021_Tx" SG_ 1056 SelDrvMdePos04_B_Avail 1;
BA_ "GenSigSendType" SG_ 1056 SelDrvMdePos04_B_Avail 3;
BA_ "U_P702_MY2021_Tx" SG_ 1056 SelDrvMdePos03_B_Avail 1;
BA_ "U_CX727_MY2021_Tx" SG_ 1056 SelDrvMdePos03_B_Avail 1;
BA_ "GenSigSendType" SG_ 1056 SelDrvMdePos03_B_Avail 3;
BA_ "U_P702_MY2021_Tx" SG_ 1056 SelDrvMdePos02_B_Avail 1;
BA_ "U_CX727_MY2021_Tx" SG_ 1056 SelDrvMdePos02_B_Avail 1;
BA_ "GenSigSendType" SG_ 1056 SelDrvMdePos02_B_Avail 3;
BA_ "U_P702_MY2021_Tx" SG_ 1056 SelDrvMdePos01_B_Avail 1;
BA_ "U_CX727_MY2021_Tx" SG_ 1056 SelDrvMdePos01_B_Avail 1;
BA_ "GenSigSendType" SG_ 1056 SelDrvMdePos01_B_Avail 3;
BA_ "U_P702_MY2021_Tx" SG_ 1056 ActvDrvMde_D2_Stat 1;
BA_ "U_CX727_MY2021_Tx" SG_ 1056 ActvDrvMde_D2_Stat 1;
BA_ "GenSigSendType" SG_ 1056 ActvDrvMde_D2_Stat 3;
BA_ "GenSigStartValue" SG_ 1056 ActvDrvMde_D2_Stat 31;
BA_ "GenSigStartValueInteger" SG_ 1056 ActvDrvMde_D2_Stat 31;
BA_ "ECGUsedRxSignal" SG_ 1056 ActvDrvMde_D2_Stat 1;
BA_ "U_P702_MY2021_Tx" SG_ 1056 SelDrvMde_D2_Rq 1;
BA_ "U_CX727_MY2021_Tx" SG_ 1056 SelDrvMde_D2_Rq 1;
BA_ "GenSigSendType" SG_ 1056 SelDrvMde_D2_Rq 3;
BA_ "GenSigStartValue" SG_ 1056 SelDrvMde_D2_Rq 31;
BA_ "GenSigStartValueInteger" SG_ 1056 SelDrvMde_D2_Rq 31;
BA_ "U_P702_MY2021_Tx" SG_ 1056 SelDrvMdePt_D_Rq 1;
BA_ "U_CX727_MY2021_Tx" SG_ 1056 SelDrvMdePt_D_Rq 1;
BA_ "U_T6_MCA_MY2020_Rx" SG_ 1056 SelDrvMdePt_D_Rq 1;
BA_ "U_P702_MY2021_Rx" SG_ 1056 SelDrvMdePt_D_Rq 1;
BA_ "GenSigSendType" SG_ 1056 SelDrvMdePt_D_Rq 3;
BA_ "U_P702_MY2021_Tx" SG_ 1056 SelDrvMdeMsgTxt_D_Rq 1;
BA_ "U_CX727_MY2021_Tx" SG_ 1056 SelDrvMdeMsgTxt_D_Rq 1;
BA_ "GenSigSendType" SG_ 1056 SelDrvMdeMsgTxt_D_Rq 3;
BA_ "U_P702_MY2021_Tx" SG_ 1056 SelDrvMde_D_Stat 1;
BA_ "U_CX727_MY2021_Tx" SG_ 1056 SelDrvMde_D_Stat 1;
BA_ "GenSigSendType" SG_ 1056 SelDrvMde_D_Stat 3;
BA_ "U_P702_MY2021_Tx" SG_ 1056 AwdMde_D_RqBrk 1;
BA_ "U_CX727_MY2021_Tx" SG_ 1056 AwdMde_D_RqBrk 1;
BA_ "GenSigSendType" SG_ 1056 AwdMde_D_RqBrk 3;
BA_ "GenSigStartValue" SG_ 1056 AwdMde_D_RqBrk 5;
BA_ "GenSigStartValueInteger" SG_ 1056 AwdMde_D_RqBrk 5;
BA_ "U_T6_MCA_MY2020_Tx" SG_ 1054 TrailOnePdlTqLm_B_Actl 1;
BA_ "U_T6_MCA_MY2020_Rx" SG_ 1054 TrailOnePdlTqLm_B_Actl 1;
BA_ "GenSigSendType" SG_ 1054 TrailOnePdlTqLm_B_Actl 3;
BA_ "GenSigSendType" SG_ 1054 SelDrvMdeChassis3_D_Rq 3;
BA_ "GenSigSendType" SG_ 1054 AirDamUp_B_RqBrk 3;
BA_ "U_P702_MY2021_Rx" SG_ 1054 AirDamUp_B_RqBrk 1;
BA_ "U_T6_MCA_MY2020_Rx" SG_ 1054 AirDamUp_B_RqBrk 1;
BA_ "U_P702_MY2021_Tx" SG_ 1054 AirDamUp_B_RqBrk 1;
BA_ "U_P702_MY2021_Tx" SG_ 1054 RbaBrk_D_Stat 1;
BA_ "U_CX727_MY2021_Tx" SG_ 1054 RbaBrk_D_Stat 1;
BA_ "GenSigSendType" SG_ 1054 RbaBrk_D_Stat 3;
BA_ "U_P702_MY2021_Tx" SG_ 1054 SelDrvMdeChassis2_D_Rq 1;
BA_ "U_P702_MY2021_Rx" SG_ 1054 SelDrvMdeChassis2_D_Rq 1;
BA_ "U_CX727_MY2021_Rx" SG_ 1054 SelDrvMdeChassis2_D_Rq 1;
BA_ "GenSigSendType" SG_ 1054 SelDrvMdeChassis2_D_Rq 3;
BA_ "U_P702_MY2021_Tx" SG_ 1054 TrailCtl_D_Stat 1;
BA_ "U_CX727_MY2021_Tx" SG_ 1054 TrailCtl_D_Stat 1;
BA_ "U_T6_MCA_MY2020_Rx" SG_ 1054 TrailCtl_D_Stat 1;
BA_ "U_P702_MY2021_Rx" SG_ 1054 TrailCtl_D_Stat 1;
BA_ "GenSigSendType" SG_ 1054 TrailCtl_D_Stat 3;
BA_ "U_P702_MY2021_Tx" SG_ 1054 TrailCtlMsgTxt_D_Rq 1;
BA_ "U_CX727_MY2021_Tx" SG_ 1054 TrailCtlMsgTxt_D_Rq 1;
BA_ "GenSigSendType" SG_ 1054 TrailCtlMsgTxt_D_Rq 3;
BA_ "U_P702_MY2021_Tx" SG_ 1054 BrkBstrVac_D_Stat 1;
BA_ "U_CX727_MY2021_Tx" SG_ 1054 BrkBstrVac_D_Stat 1;
BA_ "U_T6_MCA_MY2020_Rx" SG_ 1054 BrkBstrVac_D_Stat 1;
BA_ "U_P702_MY2021_Rx" SG_ 1054 BrkBstrVac_D_Stat 1;
BA_ "GenSigSendType" SG_ 1054 BrkBstrVac_D_Stat 3;
BA_ "U_P702_MY2021_Tx" SG_ 1054 DrvSlipCtlOffLamp_D_Rq 1;
BA_ "U_CX727_MY2021_Tx" SG_ 1054 DrvSlipCtlOffLamp_D_Rq 1;
BA_ "GenSigSendType" SG_ 1054 DrvSlipCtlOffLamp_D_Rq 3;
BA_ "ECGUsedRxSignal" SG_ 1054 DrvSlipCtlMdeMsg_D_Rq 1;
BA_ "U_P702_MY2021_Tx" SG_ 1054 DrvSlipCtlMdeMsg_D_Rq 1;
BA_ "U_CX727_MY2021_Tx" SG_ 1054 DrvSlipCtlMdeMsg_D_Rq 1;
BA_ "GenSigSendType" SG_ 1054 DrvSlipCtlMdeMsg_D_Rq 3;
BA_ "U_P702_MY2021_Tx" SG_ 1054 AutoHoldMsgTxt_D_Rq 1;
BA_ "U_CX727_MY2021_Tx" SG_ 1054 AutoHoldMsgTxt_D_Rq 1;
BA_ "GenSigSendType" SG_ 1054 AutoHoldMsgTxt_D_Rq 3;
BA_ "U_P702_MY2021_Tx" SG_ 1054 CtaBrk_D_Stat 1;
BA_ "U_CX727_MY2021_Tx" SG_ 1054 CtaBrk_D_Stat 1;
BA_ "GenSigSendType" SG_ 1054 CtaBrk_D_Stat 3;
BA_ "U_P702_MY2021_Tx" SG_ 1054 SelDrvMdeAwd_D_Rq 1;
BA_ "U_P702_MY2021_Rx" SG_ 1054 SelDrvMdeAwd_D_Rq 1;
BA_ "GenSigSendType" SG_ 1054 SelDrvMdeAwd_D_Rq 3;
BA_ "GenSigStartValue" SG_ 1054 SelDrvMdeAwd_D_Rq 31;
BA_ "GenSigStartValueInteger" SG_ 1054 SelDrvMdeAwd_D_Rq 31;
BA_ "U_P702_MY2021_Tx" SG_ 1054 AutoHoldSwMde_B_Ind 1;
BA_ "U_CX727_MY2021_Tx" SG_ 1054 AutoHoldSwMde_B_Ind 1;
BA_ "GenSigSendType" SG_ 1054 AutoHoldSwMde_B_Ind 3;
BA_ "ContentDependant" SG_ 1054 AutoHoldSwMde_B_Ind 1;
BA_ "CrossOver_InfoCAN" SG_ 1054 AutoHoldSwMde_B_Ind 1;
BA_ "U_P702_MY2021_Tx" SG_ 1054 AutoHoldMde_D_Ind 1;
BA_ "U_CX727_MY2021_Tx" SG_ 1054 AutoHoldMde_D_Ind 1;
BA_ "GenSigSendType" SG_ 1054 AutoHoldMde_D_Ind 3;
BA_ "U_P702_MY2021_Tx" SG_ 1054 SelDrvMdeChassis_D_Rq 1;
BA_ "U_CX727_MY2021_Tx" SG_ 1054 SelDrvMdeChassis_D_Rq 1;
BA_ "GenSigSendType" SG_ 1054 SelDrvMdeChassis_D_Rq 3;
BA_ "U_P702_MY2021_Tx" SG_ 1054 ApaBrk_D_Stat 1;
BA_ "U_CX727_MY2021_Tx" SG_ 1054 ApaBrk_D_Stat 1;
BA_ "U_T6_MCA_MY2020_Rx" SG_ 1054 ApaBrk_D_Stat 1;
BA_ "U_P702_MY2021_Rx" SG_ 1054 ApaBrk_D_Stat 1;
BA_ "GenSigSendType" SG_ 1054 ApaBrk_D_Stat 3;
BA_ "U_P702_MY2021_Tx" SG_ 1046 HsaMde_D_Mem 1;
BA_ "U_CX727_MY2021_Tx" SG_ 1046 HsaMde_D_Mem 1;
BA_ "GenSigStartValue" SG_ 1046 HsaMde_D_Mem 1;
BA_ "GenSigStartValueInteger" SG_ 1046 HsaMde_D_Mem 1;
BA_ "CrossOver_InfoCAN" SG_ 1046 HsaMde_D_Mem 1;
BA_ "U_P702_MY2021_Tx" SG_ 1046 BrkBstrVac_B_Rq 1;
BA_ "U_CX727_MY2021_Tx" SG_ 1046 BrkBstrVac_B_Rq 1;
BA_ "U_T6_MCA_MY2020_Rx" SG_ 1046 BrkBstrVac_B_Rq 1;
BA_ "U_P702_MY2021_Rx" SG_ 1046 BrkBstrVac_B_Rq 1;
BA_ "CrossOver_InfoCAN" SG_ 1046 BrkBstrVac_B_Rq 1;
BA_ "U_P702_MY2021_Tx" SG_ 1046 HdcMde_D_Actl 1;
BA_ "U_CX727_MY2021_Tx" SG_ 1046 HdcMde_D_Actl 1;
BA_ "CrossOver_InfoCAN" SG_ 1046 HdcMde_D_Actl 1;
BA_ "U_P702_MY2021_Tx" SG_ 1046 RearDiffLck_Tq2_RqMx 1;
BA_ "U_CX727_MY2021_Tx" SG_ 1046 RearDiffLck_Tq2_RqMx 1;
BA_ "GenSigStartValue" SG_ 1046 RearDiffLck_Tq2_RqMx 4094;
BA_ "GenSigStartValueInteger" SG_ 1046 RearDiffLck_Tq2_RqMx 4094;
BA_ "ECGUsedRxSignal" SG_ 1046 TRLR_SWAY_EVNT_IN_PROG 1;
BA_ "U_P702_MY2021_Tx" SG_ 1046 TRLR_SWAY_EVNT_IN_PROG 1;
BA_ "U_CX727_MY2021_Tx" SG_ 1046 TRLR_SWAY_EVNT_IN_PROG 1;
BA_ "U_P702_MY2021_Tx" SG_ 1046 TRLR_SWAY_CONFIG_STAT 1;
BA_ "U_CX727_MY2021_Tx" SG_ 1046 TRLR_SWAY_CONFIG_STAT 1;
BA_ "ECGUsedRxSignal" SG_ 1046 TCMode 1;
BA_ "U_P702_MY2021_Tx" SG_ 1046 TCMode 1;
BA_ "U_CX727_MY2021_Tx" SG_ 1046 TCMode 1;
BA_ "U_T6_MCA_MY2020_Rx" SG_ 1046 TCMode 1;
BA_ "U_P702_MY2021_Rx" SG_ 1046 TCMode 1;
BA_ "ContentDependant" SG_ 1046 TCMode 1;
BA_ "CrossOver_InfoCAN" SG_ 1046 TCMode 1;
BA_ "U_P702_MY2021_Tx" SG_ 1046 DrvSlipCtlLamp_D_Rq 1;
BA_ "U_CX727_MY2021_Tx" SG_ 1046 DrvSlipCtlLamp_D_Rq 1;
BA_ "U_T6_MCA_MY2020_Rx" SG_ 1046 DrvSlipCtlLamp_D_Rq 1;
BA_ "U_P702_MY2021_Rx" SG_ 1046 DrvSlipCtlLamp_D_Rq 1;
BA_ "CrossOver_InfoCAN" SG_ 1046 DrvSlipCtlLamp_D_Rq 1;
BA_ "ECGUsedRxSignal" SG_ 1046 Abs_B_Falt 1;
BA_ "U_P702_MY2021_Tx" SG_ 1046 Abs_B_Falt 1;
BA_ "U_CX727_MY2021_Tx" SG_ 1046 Abs_B_Falt 1;
BA_ "U_T6_MCA_MY2020_Rx" SG_ 1046 Abs_B_Falt 1;
BA_ "U_P702_MY2021_Rx" SG_ 1046 Abs_B_Falt 1;
BA_ "CrossOver_InfoCAN" SG_ 1046 Abs_B_Falt 1;
BA_ "ECGUsedRxSignal" SG_ 1046 DrvSlipCtlMde_D_Ind 1;
BA_ "U_P702_MY2021_Tx" SG_ 1046 DrvSlipCtlMde_D_Ind 1;
BA_ "U_CX727_MY2021_Tx" SG_ 1046 DrvSlipCtlMde_D_Ind 1;
BA_ "U_T6_MCA_MY2020_Rx" SG_ 1046 DrvSlipCtlMde_D_Ind 1;
BA_ "U_P702_MY2021_Rx" SG_ 1046 DrvSlipCtlMde_D_Ind 1;
BA_ "CrossOver_InfoCAN" SG_ 1046 DrvSlipCtlMde_D_Ind 1;
BA_ "U_P702_MY2021_Tx" SG_ 1046 DrvAntiLckLamp_D_Rq 1;
BA_ "U_CX727_MY2021_Tx" SG_ 1046 DrvAntiLckLamp_D_Rq 1;
BA_ "U_T6_MCA_MY2020_Rx" SG_ 1046 DrvAntiLckLamp_D_Rq 1;
BA_ "U_P702_MY2021_Rx" SG_ 1046 DrvAntiLckLamp_D_Rq 1;
BA_ "CrossOver_InfoCAN" SG_ 1046 DrvAntiLckLamp_D_Rq 1;
BA_ "U_P702_MY2021_Tx" SG_ 1046 BpedMove_No_Cnt 1;
BA_ "U_CX727_MY2021_Tx" SG_ 1046 BpedMove_No_Cnt 1;
BA_ "U_P702_MY2021_Rx" SG_ 1046 BpedMove_No_Cnt 1;
BA_ "MetaData" SG_ 1046 BpedMove_No_Cnt 1;
BA_ "CrossOver_InfoCAN" SG_ 1046 BpedMove_No_Cnt 1;
BA_ "U_P702_MY2021_Tx" SG_ 1046 StabCtlBrk_B_Avail 1;
BA_ "U_CX727_MY2021_Tx" SG_ 1046 StabCtlBrk_B_Avail 1;
BA_ "GenSigStartValue" SG_ 1046 StabCtlBrk_B_Avail 1;
BA_ "GenSigStartValueInteger" SG_ 1046 StabCtlBrk_B_Avail 1;
BA_ "CrossOver_InfoCAN" SG_ 1046 StabCtlBrk_B_Avail 1;
BA_ "U_P702_MY2021_Tx" SG_ 1046 DrvHdcWarnInfo_D_Rq 1;
BA_ "U_CX727_MY2021_Tx" SG_ 1046 DrvHdcWarnInfo_D_Rq 1;
BA_ "CrossOver_InfoCAN" SG_ 1046 DrvHdcWarnInfo_D_Rq 1;
BA_ "U_P702_MY2021_Tx" SG_ 1046 DrvHdcMsg_D_Rq 1;
BA_ "U_CX727_MY2021_Tx" SG_ 1046 DrvHdcMsg_D_Rq 1;
BA_ "CrossOver_InfoCAN" SG_ 1046 DrvHdcMsg_D_Rq 1;
BA_ "U_P702_MY2021_Tx" SG_ 1046 DrvHdcLampInfo_D_Rq 1;
BA_ "U_CX727_MY2021_Tx" SG_ 1046 DrvHdcLampInfo_D_Rq 1;
BA_ "CrossOver_InfoCAN" SG_ 1046 DrvHdcLampInfo_D_Rq 1;
BA_ "U_P702_MY2021_Tx" SG_ 1046 BpedMove_D_Actl 1;
BA_ "U_CX727_MY2021_Tx" SG_ 1046 BpedMove_D_Actl 1;
BA_ "U_P702_MY2021_Rx" SG_ 1046 BpedMove_D_Actl 1;
BA_ "GenSigStartValue" SG_ 1046 BpedMove_D_Actl 3;
BA_ "GenSigStartValueInteger" SG_ 1046 BpedMove_D_Actl 3;
BA_ "CrossOver_InfoCAN" SG_ 1046 BpedMove_D_Actl 1;
BA_ "U_P702_MY2021_Tx" SG_ 1046 ChimeBrk_B_Rq 1;
BA_ "U_CX727_MY2021_Tx" SG_ 1046 ChimeBrk_B_Rq 1;
BA_ "CrossOver_InfoCAN" SG_ 1046 ChimeBrk_B_Rq 1;
BA_ "U_P702_MY2021_Tx" SG_ 1046 BrkLamp_B_Rq 1;
BA_ "U_CX727_MY2021_Tx" SG_ 1046 BrkLamp_B_Rq 1;
BA_ "CrossOver_InfoCAN" SG_ 1046 BrkLamp_B_Rq 1;
BA_ "U_P702_MY2021_Tx" SG_ 1046 HILL_DESC_MC 1;
BA_ "U_CX727_MY2021_Tx" SG_ 1046 HILL_DESC_MC 1;
BA_ "CrossOver_InfoCAN" SG_ 1046 HILL_DESC_MC 1;
BA_ "U_P702_MY2021_Tx" SG_ 1046 RearDiffElckrOpen_B_Rq 1;
BA_ "U_P702_MY2021_Tx" SG_ 1045 VehStab_D_Stat 1;
BA_ "U_CX727_MY2021_Tx" SG_ 1045 VehStab_D_Stat 1;
BA_ "U_T6_MCA_MY2020_Rx" SG_ 1045 VehStab_D_Stat 1;
BA_ "U_P702_MY2021_Rx" SG_ 1045 VehStab_D_Stat 1;
BA_ "GenSigStartValue" SG_ 1045 VehStab_D_Stat 14;
BA_ "GenSigStartValueInteger" SG_ 1045 VehStab_D_Stat 14;
BA_ "U_P702_MY2021_Tx" SG_ 1045 BrkFluidLvl_D_Stat 1;
BA_ "U_CX727_MY2021_Tx" SG_ 1045 BrkFluidLvl_D_Stat 1;
BA_ "U_P702_MY2021_Tx" SG_ 1045 LsmcBrkDecel_D_Stat 1;
BA_ "U_P702_MY2021_Rx" SG_ 1045 LsmcBrkDecel_D_Stat 1;
BA_ "U_P702_MY2021_Tx" SG_ 1045 VehYawNonLin_W_Rq 1;
BA_ "U_CX727_MY2021_Tx" SG_ 1045 VehYawNonLin_W_Rq 1;
BA_ "U_T6_MCA_MY2020_Rx" SG_ 1045 VehYawNonLin_W_Rq 1;
BA_ "U_P702_MY2021_Rx" SG_ 1045 VehYawNonLin_W_Rq 1;
BA_ "GenSigStartValue" SG_ 1045 VehYawNonLin_W_Rq 4094;
BA_ "GenSigStartValueInteger" SG_ 1045 VehYawNonLin_W_Rq 4094;
BA_ "CrossOver_InfoCAN" SG_ 1045 VehYawNonLin_W_Rq 1;
BA_ "U_P702_MY2021_Tx" SG_ 1045 VehYawLin_W_Rq 1;
BA_ "U_CX727_MY2021_Tx" SG_ 1045 VehYawLin_W_Rq 1;
BA_ "U_T6_MCA_MY2020_Rx" SG_ 1045 VehYawLin_W_Rq 1;
BA_ "U_P702_MY2021_Rx" SG_ 1045 VehYawLin_W_Rq 1;
BA_ "GenSigStartValue" SG_ 1045 VehYawLin_W_Rq 4094;
BA_ "GenSigStartValueInteger" SG_ 1045 VehYawLin_W_Rq 4094;
BA_ "CrossOver_InfoCAN" SG_ 1045 VehYawLin_W_Rq 1;
BA_ "U_P702_MY2021_Tx" SG_ 1045 VehVActlBrk_No_Cs 1;
BA_ "U_CX727_MY2021_Tx" SG_ 1045 VehVActlBrk_No_Cs 1;
BA_ "U_CX727_MY2021_Rx" SG_ 1045 VehVActlBrk_No_Cs 1;
BA_ "U_T6_MCA_MY2020_Rx" SG_ 1045 VehVActlBrk_No_Cs 1;
BA_ "U_P702_MY2021_Rx" SG_ 1045 VehVActlBrk_No_Cs 1;
BA_ "MetaData" SG_ 1045 VehVActlBrk_No_Cs 1;
BA_ "CrossOver_InfoCAN" SG_ 1045 VehVActlBrk_No_Cs 1;
BA_ "U_P702_MY2021_Tx" SG_ 1045 Veh_V_ActlBrk 1;
BA_ "U_CX727_MY2021_Tx" SG_ 1045 Veh_V_ActlBrk 1;
BA_ "U_CX727_MY2021_Rx" SG_ 1045 Veh_V_ActlBrk 1;
BA_ "U_T6_MCA_MY2020_Rx" SG_ 1045 Veh_V_ActlBrk 1;
BA_ "U_P702_MY2021_Rx" SG_ 1045 Veh_V_ActlBrk 1;
BA_ "CrossOver_InfoCAN" SG_ 1045 Veh_V_ActlBrk 1;
BA_ "U_P702_MY2021_Tx" SG_ 1045 VehVActlBrk_No_Cnt 1;
BA_ "U_CX727_MY2021_Tx" SG_ 1045 VehVActlBrk_No_Cnt 1;
BA_ "U_CX727_MY2021_Rx" SG_ 1045 VehVActlBrk_No_Cnt 1;
BA_ "U_T6_MCA_MY2020_Rx" SG_ 1045 VehVActlBrk_No_Cnt 1;
BA_ "U_P702_MY2021_Rx" SG_ 1045 VehVActlBrk_No_Cnt 1;
BA_ "MetaData" SG_ 1045 VehVActlBrk_No_Cnt 1;
BA_ "CrossOver_InfoCAN" SG_ 1045 VehVActlBrk_No_Cnt 1;
BA_ "U_P702_MY2021_Tx" SG_ 1045 VehVActlBrk_D_Qf 1;
BA_ "U_CX727_MY2021_Tx" SG_ 1045 VehVActlBrk_D_Qf 1;
BA_ "U_CX727_MY2021_Rx" SG_ 1045 VehVActlBrk_D_Qf 1;
BA_ "U_T6_MCA_MY2020_Rx" SG_ 1045 VehVActlBrk_D_Qf 1;
BA_ "U_P702_MY2021_Rx" SG_ 1045 VehVActlBrk_D_Qf 1;
BA_ "MetaData" SG_ 1045 VehVActlBrk_D_Qf 1;
BA_ "CrossOver_InfoCAN" SG_ 1045 VehVActlBrk_D_Qf 1;
BA_ "U_P702_MY2021_Tx" SG_ 1044 StePinOffst_An_Est 1;
BA_ "U_CX727_MY2021_Tx" SG_ 1044 StePinOffst_An_Est 1;
BA_ "U_P702_MY2021_Rx" SG_ 1044 StePinOffst_An_Est 1;
BA_ "U_CX727_MY2021_Rx" SG_ 1044 StePinOffst_An_Est 1;
BA_ "GenSigStartValue" SG_ 1044 StePinOffst_An_Est 65533;
BA_ "ContentDependant" SG_ 1044 StePinOffst_An_Est 1;
BA_ "GenSigStartValueInteger" SG_ 1044 StePinOffst_An_Est 65534;
BA_ "U_P702_MY2021_Tx" SG_ 1044 StePinOffst_No_Cs 1;
BA_ "U_CX727_MY2021_Tx" SG_ 1044 StePinOffst_No_Cs 1;
BA_ "U_P702_MY2021_Rx" SG_ 1044 StePinOffst_No_Cs 1;
BA_ "U_CX727_MY2021_Rx" SG_ 1044 StePinOffst_No_Cs 1;
BA_ "MetaData" SG_ 1044 StePinOffst_No_Cs 1;
BA_ "ContentDependant" SG_ 1044 StePinOffst_No_Cs 1;
BA_ "U_P702_MY2021_Tx" SG_ 1044 StePinOffst_No_Cnt 1;
BA_ "U_CX727_MY2021_Tx" SG_ 1044 StePinOffst_No_Cnt 1;
BA_ "U_P702_MY2021_Rx" SG_ 1044 StePinOffst_No_Cnt 1;
BA_ "U_CX727_MY2021_Rx" SG_ 1044 StePinOffst_No_Cnt 1;
BA_ "MetaData" SG_ 1044 StePinOffst_No_Cnt 1;
BA_ "CrossOver_InfoCAN" SG_ 1044 StePinOffst_No_Cnt 1;
BA_ "U_P702_MY2021_Tx" SG_ 1044 StePinOffst_D_Stat 1;
BA_ "U_CX727_MY2021_Tx" SG_ 1044 StePinOffst_D_Stat 1;
BA_ "U_P702_MY2021_Rx" SG_ 1044 StePinOffst_D_Stat 1;
BA_ "U_CX727_MY2021_Rx" SG_ 1044 StePinOffst_D_Stat 1;
BA_ "U_P702_MY2021_Tx" SG_ 1042 VehRol_An_Dsply 1;
BA_ "GenSigStartValueInteger" SG_ 1042 VehRol_An_Dsply 64;
BA_ "U_P702_MY2021_Tx" SG_ 1042 VehPtch_An_Dsply 1;
BA_ "U_P702_MY2021_Rx" SG_ 1042 VehPtch_An_Dsply 1;
BA_ "GenSigStartValueInteger" SG_ 1042 VehPtch_An_Dsply 64;
BA_ "U_P702_MY2021_Tx" SG_ 1042 TrlrBrk_Pc_Rq 1;
BA_ "U_P702_MY2021_Tx" SG_ 535 WhlRr_W_Meas 1;
BA_ "U_CX727_MY2021_Tx" SG_ 535 WhlRr_W_Meas 1;
BA_ "U_CX727_MY2021_Rx" SG_ 535 WhlRr_W_Meas 1;
BA_ "U_T6_MCA_MY2020_Rx" SG_ 535 WhlRr_W_Meas 1;
BA_ "U_P702_MY2021_Rx" SG_ 535 WhlRr_W_Meas 1;
BA_ "U_P702_MY2021_Tx" SG_ 535 WhlRl_W_Meas 1;
BA_ "U_CX727_MY2021_Tx" SG_ 535 WhlRl_W_Meas 1;
BA_ "U_CX727_MY2021_Rx" SG_ 535 WhlRl_W_Meas 1;
BA_ "U_T6_MCA_MY2020_Rx" SG_ 535 WhlRl_W_Meas 1;
BA_ "U_P702_MY2021_Rx" SG_ 535 WhlRl_W_Meas 1;
BA_ "U_P702_MY2021_Tx" SG_ 535 WhlFr_W_Meas 1;
BA_ "U_CX727_MY2021_Tx" SG_ 535 WhlFr_W_Meas 1;
BA_ "U_CX727_MY2021_Rx" SG_ 535 WhlFr_W_Meas 1;
BA_ "U_T6_MCA_MY2020_Rx" SG_ 535 WhlFr_W_Meas 1;
BA_ "U_P702_MY2021_Rx" SG_ 535 WhlFr_W_Meas 1;
BA_ "U_P702_MY2021_Tx" SG_ 535 WhlFl_W_Meas 1;
BA_ "U_CX727_MY2021_Tx" SG_ 535 WhlFl_W_Meas 1;
BA_ "U_CX727_MY2021_Rx" SG_ 535 WhlFl_W_Meas 1;
BA_ "U_T6_MCA_MY2020_Rx" SG_ 535 WhlFl_W_Meas 1;
BA_ "U_P702_MY2021_Rx" SG_ 535 WhlFl_W_Meas 1;
BA_ "U_P702_MY2021_Tx" SG_ 534 BrkObdData_No_Actl 1;
BA_ "U_CX727_MY2021_Tx" SG_ 534 BrkObdData_No_Actl 1;
BA_ "ContentDependant" SG_ 534 BrkObdData_No_Actl 1;
BA_ "U_P702_MY2021_Tx" SG_ 534 BrkObdIndex_No_Actl 1;
BA_ "U_CX727_MY2021_Tx" SG_ 534 BrkObdIndex_No_Actl 1;
BA_ "ContentDependant" SG_ 534 BrkObdIndex_No_Actl 1;
BA_ "U_P702_MY2021_Tx" SG_ 534 WhlRotatRr_No_Cnt 1;
BA_ "U_CX727_MY2021_Tx" SG_ 534 WhlRotatRr_No_Cnt 1;
BA_ "U_P702_MY2021_Rx" SG_ 534 WhlRotatRr_No_Cnt 1;
BA_ "CrossOver_InfoCAN" SG_ 534 WhlRotatRr_No_Cnt 1;
BA_ "U_P702_MY2021_Tx" SG_ 534 WhlDirRr_D_Actl 1;
BA_ "U_CX727_MY2021_Tx" SG_ 534 WhlDirRr_D_Actl 1;
BA_ "U_T6_MCA_MY2020_Rx" SG_ 534 WhlDirRr_D_Actl 1;
BA_ "U_P702_MY2021_Rx" SG_ 534 WhlDirRr_D_Actl 1;
BA_ "U_CX727_MY2021_Rx" SG_ 534 WhlDirRr_D_Actl 1;
BA_ "CrossOver_InfoCAN" SG_ 534 WhlDirRr_D_Actl 1;
BA_ "U_P702_MY2021_Tx" SG_ 534 WhlDirRl_D_Actl 1;
BA_ "U_CX727_MY2021_Tx" SG_ 534 WhlDirRl_D_Actl 1;
BA_ "U_CX727_MY2021_Rx" SG_ 534 WhlDirRl_D_Actl 1;
BA_ "U_T6_MCA_MY2020_Rx" SG_ 534 WhlDirRl_D_Actl 1;
BA_ "U_P702_MY2021_Rx" SG_ 534 WhlDirRl_D_Actl 1;
BA_ "CrossOver_InfoCAN" SG_ 534 WhlDirRl_D_Actl 1;
BA_ "U_P702_MY2021_Tx" SG_ 534 WhlDirFr_D_Actl 1;
BA_ "U_CX727_MY2021_Tx" SG_ 534 WhlDirFr_D_Actl 1;
BA_ "U_T6_MCA_MY2020_Rx" SG_ 534 WhlDirFr_D_Actl 1;
BA_ "U_P702_MY2021_Rx" SG_ 534 WhlDirFr_D_Actl 1;
BA_ "U_CX727_MY2021_Rx" SG_ 534 WhlDirFr_D_Actl 1;
BA_ "CrossOver_InfoCAN" SG_ 534 WhlDirFr_D_Actl 1;
BA_ "U_P702_MY2021_Tx" SG_ 534 WhlDirFl_D_Actl 1;
BA_ "U_CX727_MY2021_Tx" SG_ 534 WhlDirFl_D_Actl 1;
BA_ "U_T6_MCA_MY2020_Rx" SG_ 534 WhlDirFl_D_Actl 1;
BA_ "U_P702_MY2021_Rx" SG_ 534 WhlDirFl_D_Actl 1;
BA_ "U_CX727_MY2021_Rx" SG_ 534 WhlDirFl_D_Actl 1;
BA_ "CrossOver_InfoCAN" SG_ 534 WhlDirFl_D_Actl 1;
BA_ "U_P702_MY2021_Tx" SG_ 534 WhlRotatRl_No_Cnt 1;
BA_ "U_CX727_MY2021_Tx" SG_ 534 WhlRotatRl_No_Cnt 1;
BA_ "U_P702_MY2021_Rx" SG_ 534 WhlRotatRl_No_Cnt 1;
BA_ "CrossOver_InfoCAN" SG_ 534 WhlRotatRl_No_Cnt 1;
BA_ "U_P702_MY2021_Tx" SG_ 534 WhlRotatFr_No_Cnt 1;
BA_ "U_CX727_MY2021_Tx" SG_ 534 WhlRotatFr_No_Cnt 1;
BA_ "U_P702_MY2021_Rx" SG_ 534 WhlRotatFr_No_Cnt 1;
BA_ "CrossOver_InfoCAN" SG_ 534 WhlRotatFr_No_Cnt 1;
BA_ "U_P702_MY2021_Tx" SG_ 534 WhlRotatFl_No_Cnt 1;
BA_ "U_CX727_MY2021_Tx" SG_ 534 WhlRotatFl_No_Cnt 1;
BA_ "U_P702_MY2021_Rx" SG_ 534 WhlRotatFl_No_Cnt 1;
BA_ "CrossOver_InfoCAN" SG_ 534 WhlRotatFl_No_Cnt 1;
BA_ "U_P702_MY2021_Tx" SG_ 532 RgenTqFalt_B_Actl 1;
BA_ "U_CX727_MY2021_Tx" SG_ 532 RgenTqFalt_B_Actl 1;
BA_ "U_P702_MY2021_Rx" SG_ 532 RgenTqFalt_B_Actl 1;
BA_ "U_P702_MY2021_Tx" SG_ 532 RgenBrkDynoMde_B_Actl 1;
BA_ "U_CX727_MY2021_Tx" SG_ 532 RgenBrkDynoMde_B_Actl 1;
BA_ "U_P702_MY2021_Rx" SG_ 532 RgenBrkDynoMde_B_Actl 1;
BA_ "U_P702_MY2021_Tx" SG_ 532 PrplWhlTqRqMn_No_Cs 1;
BA_ "U_CX727_MY2021_Tx" SG_ 532 PrplWhlTqRqMn_No_Cs 1;
BA_ "U_T6_MCA_MY2020_Rx" SG_ 532 PrplWhlTqRqMn_No_Cs 1;
BA_ "U_P702_MY2021_Rx" SG_ 532 PrplWhlTqRqMn_No_Cs 1;
BA_ "MetaData" SG_ 532 PrplWhlTqRqMn_No_Cs 1;
BA_ "U_P702_MY2021_Tx" SG_ 532 PrplWhlTot_Tq_RqMn 1;
BA_ "U_CX727_MY2021_Tx" SG_ 532 PrplWhlTot_Tq_RqMn 1;
BA_ "U_T6_MCA_MY2020_Rx" SG_ 532 PrplWhlTot_Tq_RqMn 1;
BA_ "U_P702_MY2021_Rx" SG_ 532 PrplWhlTot_Tq_RqMn 1;
BA_ "U_P702_MY2021_Tx" SG_ 532 PrplWhlTqRqMn_No_Cnt 1;
BA_ "U_CX727_MY2021_Tx" SG_ 532 PrplWhlTqRqMn_No_Cnt 1;
BA_ "U_T6_MCA_MY2020_Rx" SG_ 532 PrplWhlTqRqMn_No_Cnt 1;
BA_ "U_P702_MY2021_Rx" SG_ 532 PrplWhlTqRqMn_No_Cnt 1;
BA_ "MetaData" SG_ 532 PrplWhlTqRqMn_No_Cnt 1;
BA_ "U_P702_MY2021_Tx" SG_ 531 VehStop_D_Stat 1;
BA_ "U_CX727_MY2021_Tx" SG_ 531 VehStop_D_Stat 1;
BA_ "GenSigStartValue" SG_ 531 VehStop_D_Stat 2;
BA_ "GenSigStartValueInteger" SG_ 531 VehStop_D_Stat 2;
BA_ "U_P702_MY2021_Tx" SG_ 531 TracCtlPtActv_B_Actl 1;
BA_ "U_CX727_MY2021_Tx" SG_ 531 TracCtlPtActv_B_Actl 1;
BA_ "U_T6_MCA_MY2020_Rx" SG_ 531 TracCtlPtActv_B_Actl 1;
BA_ "U_P702_MY2021_Rx" SG_ 531 TracCtlPtActv_B_Actl 1;
BA_ "CrossOver_InfoCAN" SG_ 531 TracCtlPtActv_B_Actl 1;
BA_ "U_P702_MY2021_Tx" SG_ 531 LscmbbMntr_B_Err 1;
BA_ "CrossOver_InfoCAN" SG_ 531 LscmbbMntr_B_Err 1;
BA_ "U_P702_MY2021_Tx" SG_ 531 LscmbbBrkDis_B_Actl 1;
BA_ "CrossOver_InfoCAN" SG_ 531 LscmbbBrkDis_B_Actl 1;
BA_ "U_P702_MY2021_Tx" SG_ 531 LscmbbDeny_B_ActlBrk 1;
BA_ "CrossOver_InfoCAN" SG_ 531 LscmbbDeny_B_ActlBrk 1;
BA_ "U_P702_MY2021_Tx" SG_ 531 PrkBrkYwLamp_D_Rq 1;
BA_ "U_CX727_MY2021_Tx" SG_ 531 PrkBrkYwLamp_D_Rq 1;
BA_ "CrossOver_InfoCAN" SG_ 531 PrkBrkYwLamp_D_Rq 1;
BA_ "WakeupSignal" SG_ 531 PrkBrkYwLamp_D_Rq 1;
BA_ "U_P702_MY2021_Tx" SG_ 531 PrkBrkRedLamp_D_Rq 1;
BA_ "U_CX727_MY2021_Tx" SG_ 531 PrkBrkRedLamp_D_Rq 1;
BA_ "CrossOver_InfoCAN" SG_ 531 PrkBrkRedLamp_D_Rq 1;
BA_ "WakeupSignal" SG_ 531 PrkBrkRedLamp_D_Rq 1;
BA_ "U_P702_MY2021_Tx" SG_ 531 LscmbbBrkDecel_B_Actl 1;
BA_ "CrossOver_InfoCAN" SG_ 531 LscmbbBrkDecel_B_Actl 1;
BA_ "U_P702_MY2021_Tx" SG_ 531 AbsActv_B_Actl 1;
BA_ "U_CX727_MY2021_Tx" SG_ 531 AbsActv_B_Actl 1;
BA_ "U_T6_MCA_MY2020_Rx" SG_ 531 AbsActv_B_Actl 1;
BA_ "U_P702_MY2021_Rx" SG_ 531 AbsActv_B_Actl 1;
BA_ "U_CX727_MY2021_Rx" SG_ 531 AbsActv_B_Actl 1;
BA_ "CrossOver_InfoCAN" SG_ 531 AbsActv_B_Actl 1;
BA_ "ECGUsedRxSignal" SG_ 531 StabCtlBrkActv_B_Actl 1;
BA_ "U_P702_MY2021_Tx" SG_ 531 StabCtlBrkActv_B_Actl 1;
BA_ "U_CX727_MY2021_Tx" SG_ 531 StabCtlBrkActv_B_Actl 1;
BA_ "U_CX727_MY2021_Rx" SG_ 531 StabCtlBrkActv_B_Actl 1;
BA_ "U_T6_MCA_MY2020_Rx" SG_ 531 StabCtlBrkActv_B_Actl 1;
BA_ "U_P702_MY2021_Rx" SG_ 531 StabCtlBrkActv_B_Actl 1;
BA_ "CrossOver_InfoCAN" SG_ 531 StabCtlBrkActv_B_Actl 1;
BA_ "U_P702_MY2021_Tx" SG_ 531 CmbbBrkPrchg_B_Actl 1;
BA_ "U_CX727_MY2021_Tx" SG_ 531 CmbbBrkPrchg_B_Actl 1;
BA_ "CrossOver_InfoCAN" SG_ 531 CmbbBrkPrchg_B_Actl 1;
BA_ "U_P702_MY2021_Tx" SG_ 531 CmbbBrkDecel_B_Actl 1;
BA_ "U_CX727_MY2021_Tx" SG_ 531 CmbbBrkDecel_B_Actl 1;
BA_ "CrossOver_InfoCAN" SG_ 531 CmbbBrkDecel_B_Actl 1;
BA_ "U_P702_MY2021_Tx" SG_ 531 CmbbBaSensInc_B_Actl 1;
BA_ "U_CX727_MY2021_Tx" SG_ 531 CmbbBaSensInc_B_Actl 1;
BA_ "CrossOver_InfoCAN" SG_ 531 CmbbBaSensInc_B_Actl 1;
BA_ "U_P702_MY2021_Tx" SG_ 531 AccBrkWarm_B_Actl 1;
BA_ "U_CX727_MY2021_Tx" SG_ 531 AccBrkWarm_B_Actl 1;
BA_ "CrossOver_InfoCAN" SG_ 531 AccBrkWarm_B_Actl 1;
BA_ "U_P702_MY2021_Tx" SG_ 531 AccBrkTotTqMn_B_Actl 1;
BA_ "U_CX727_MY2021_Tx" SG_ 531 AccBrkTotTqMn_B_Actl 1;
BA_ "CrossOver_InfoCAN" SG_ 531 AccBrkTotTqMn_B_Actl 1;
BA_ "U_P702_MY2021_Tx" SG_ 531 AccBrkPrchgActv_B_Actl 1;
BA_ "U_CX727_MY2021_Tx" SG_ 531 AccBrkPrchgActv_B_Actl 1;
BA_ "CrossOver_InfoCAN" SG_ 531 AccBrkPrchgActv_B_Actl 1;
BA_ "U_P702_MY2021_Tx" SG_ 531 AccBrkDis_B_Actl 1;
BA_ "U_CX727_MY2021_Tx" SG_ 531 AccBrkDis_B_Actl 1;
BA_ "CrossOver_InfoCAN" SG_ 531 AccBrkDis_B_Actl 1;
BA_ "U_P702_MY2021_Tx" SG_ 531 AccBrkDeny_B_Actl 1;
BA_ "U_CX727_MY2021_Tx" SG_ 531 AccBrkDeny_B_Actl 1;
BA_ "U_T6_MCA_MY2020_Rx" SG_ 531 AccBrkDeny_B_Actl 1;
BA_ "U_P702_MY2021_Rx" SG_ 531 AccBrkDeny_B_Actl 1;
BA_ "CrossOver_InfoCAN" SG_ 531 AccBrkDeny_B_Actl 1;
BA_ "U_P702_MY2021_Tx" SG_ 531 AccBrkActv_B_Actl 1;
BA_ "U_CX727_MY2021_Tx" SG_ 531 AccBrkActv_B_Actl 1;
BA_ "U_T6_MCA_MY2020_Rx" SG_ 531 AccBrkActv_B_Actl 1;
BA_ "U_P702_MY2021_Rx" SG_ 531 AccBrkActv_B_Actl 1;
BA_ "CrossOver_InfoCAN" SG_ 531 AccBrkActv_B_Actl 1;
BA_ "U_P702_MY2021_Tx" SG_ 531 PrplDrgCtlActv_B_Actl 1;
BA_ "U_CX727_MY2021_Tx" SG_ 531 PrplDrgCtlActv_B_Actl 1;
BA_ "U_T6_MCA_MY2020_Rx" SG_ 531 PrplDrgCtlActv_B_Actl 1;
BA_ "U_P702_MY2021_Rx" SG_ 531 PrplDrgCtlActv_B_Actl 1;
BA_ "CrossOver_InfoCAN" SG_ 531 PrplDrgCtlActv_B_Actl 1;
BA_ "U_P702_MY2021_Tx" SG_ 531 PrplWhlTot_Tq_RqMx 1;
BA_ "U_CX727_MY2021_Tx" SG_ 531 PrplWhlTot_Tq_RqMx 1;
BA_ "U_T6_MCA_MY2020_Rx" SG_ 531 PrplWhlTot_Tq_RqMx 1;
BA_ "U_P702_MY2021_Rx" SG_ 531 PrplWhlTot_Tq_RqMx 1;
BA_ "CrossOver_InfoCAN" SG_ 531 PrplWhlTot_Tq_RqMx 1;
BA_ "U_P702_MY2021_Tx" SG_ 531 LscmbbBaSensInc_B_Actl 1;
BA_ "CrossOver_InfoCAN" SG_ 531 LscmbbBaSensInc_B_Actl 1;
BA_ "U_P702_MY2021_Tx" SG_ 531 CmbbBrkDis_B_Actl 1;
BA_ "U_CX727_MY2021_Tx" SG_ 531 CmbbBrkDis_B_Actl 1;
BA_ "U_P702_MY2021_Rx" SG_ 531 CmbbBrkDis_B_Actl 1;
BA_ "U_CX727_MY2021_Rx" SG_ 531 CmbbBrkDis_B_Actl 1;
BA_ "CrossOver_InfoCAN" SG_ 531 CmbbBrkDis_B_Actl 1;
BA_ "U_P702_MY2021_Tx" SG_ 531 CmbbDeny_B_ActlBrk 1;
BA_ "U_CX727_MY2021_Tx" SG_ 531 CmbbDeny_B_ActlBrk 1;
BA_ "U_CX727_MY2021_Rx" SG_ 531 CmbbDeny_B_ActlBrk 1;
BA_ "U_T6_MCA_MY2020_Rx" SG_ 531 CmbbDeny_B_ActlBrk 1;
BA_ "U_P702_MY2021_Rx" SG_ 531 CmbbDeny_B_ActlBrk 1;
BA_ "CrossOver_InfoCAN" SG_ 531 CmbbDeny_B_ActlBrk 1;
BA_ "U_P702_MY2021_Tx" SG_ 531 CcDis_B_Cmd 1;
BA_ "U_CX727_MY2021_Tx" SG_ 531 CcDis_B_Cmd 1;
BA_ "U_T6_MCA_MY2020_Rx" SG_ 531 CcDis_B_Cmd 1;
BA_ "U_P702_MY2021_Rx" SG_ 531 CcDis_B_Cmd 1;
BA_ "CrossOver_InfoCAN" SG_ 531 CcDis_B_Cmd 1;
BA_ "U_P702_MY2021_Tx" SG_ 531 VehLongOvrGnd_A_Est 1;
BA_ "U_CX727_MY2021_Tx" SG_ 531 VehLongOvrGnd_A_Est 1;
BA_ "U_P702_MY2021_Rx" SG_ 531 VehLongOvrGnd_A_Est 1;
BA_ "GenSigStartValueInteger" SG_ 531 VehLongOvrGnd_A_Est 511;
BA_ "CrossOver_InfoCAN" SG_ 531 VehLongOvrGnd_A_Est 1;
BA_ "U_P702_MY2021_Tx" SG_ 531 LscmbBrkPrchg_B_Actl 1;
BA_ "CrossOver_InfoCAN" SG_ 531 LscmbBrkPrchg_B_Actl 1;
BA_ "U_P702_MY2021_Tx" SG_ 531 AccStopActv_B_ActlBrk 1;
BA_ "U_CX727_MY2021_Tx" SG_ 531 AccStopActv_B_ActlBrk 1;
BA_ "U_T6_MCA_MY2020_Rx" SG_ 531 AccStopActv_B_ActlBrk 1;
BA_ "U_P702_MY2021_Rx" SG_ 531 AccStopActv_B_ActlBrk 1;
BA_ "CrossOver_InfoCAN" SG_ 531 AccStopActv_B_ActlBrk 1;
BA_ "U_P702_MY2021_Tx" SG_ 531 AccDis_B_ActlEpb 1;
BA_ "U_CX727_MY2021_Tx" SG_ 531 AccDis_B_ActlEpb 1;
BA_ "CrossOver_InfoCAN" SG_ 531 AccDis_B_ActlEpb 1;
BA_ "U_P702_MY2021_Tx" SG_ 531 PrkBrkMsgTxt_D_Rq 1;
BA_ "U_CX727_MY2021_Tx" SG_ 531 PrkBrkMsgTxt_D_Rq 1;
BA_ "CrossOver_InfoCAN" SG_ 531 PrkBrkMsgTxt_D_Rq 1;
BA_ "WakeupSignal" SG_ 531 PrkBrkMsgTxt_D_Rq 1;
BA_ "ECGUsedRxSignal" SG_ 531 PrkBrkStatus 1;
BA_ "U_P702_MY2021_Tx" SG_ 531 PrkBrkStatus 1;
BA_ "U_CX727_MY2021_Tx" SG_ 531 PrkBrkStatus 1;
BA_ "U_T6_MCA_MY2020_Rx" SG_ 531 PrkBrkStatus 1;
BA_ "U_P702_MY2021_Rx" SG_ 531 PrkBrkStatus 1;
BA_ "GenSigStartValue" SG_ 531 PrkBrkStatus 7;
BA_ "GenSigStartValueInteger" SG_ 531 PrkBrkStatus 7;
BA_ "CrossOver_InfoCAN" SG_ 531 PrkBrkStatus 1;
BA_ "U_P702_MY2021_Tx" SG_ 125 VehRolComp_W_Actl 1;
BA_ "U_CX727_MY2021_Tx" SG_ 125 VehRolComp_W_Actl 1;
BA_ "GenSigStartValue" SG_ 125 VehRolComp_W_Actl 4094;
BA_ "GenSigStartValueInteger" SG_ 125 VehRolComp_W_Actl 4094;
BA_ "U_P702_MY2021_Tx" SG_ 125 VehVertComp_A_Actl 1;
BA_ "U_CX727_MY2021_Tx" SG_ 125 VehVertComp_A_Actl 1;
BA_ "U_P702_MY2021_Rx" SG_ 125 VehVertComp_A_Actl 1;
BA_ "GenSigStartValue" SG_ 125 VehVertComp_A_Actl 1022;
BA_ "GenSigStartValueInteger" SG_ 125 VehVertComp_A_Actl 1022;
BA_ "U_P702_MY2021_Tx" SG_ 125 BrkTotTqRqArb_No_Cs 1;
BA_ "U_CX727_MY2021_Tx" SG_ 125 BrkTotTqRqArb_No_Cs 1;
BA_ "U_T6_MCA_MY2020_Rx" SG_ 125 BrkTotTqRqArb_No_Cs 1;
BA_ "U_P702_MY2021_Rx" SG_ 125 BrkTotTqRqArb_No_Cs 1;
BA_ "MetaData" SG_ 125 BrkTotTqRqArb_No_Cs 1;
BA_ "U_P702_MY2021_Tx" SG_ 125 BrkTotTqRqArb_No_Cnt 1;
BA_ "U_CX727_MY2021_Tx" SG_ 125 BrkTotTqRqArb_No_Cnt 1;
BA_ "U_T6_MCA_MY2020_Rx" SG_ 125 BrkTotTqRqArb_No_Cnt 1;
BA_ "U_P702_MY2021_Rx" SG_ 125 BrkTotTqRqArb_No_Cnt 1;
BA_ "MetaData" SG_ 125 BrkTotTqRqArb_No_Cnt 1;
BA_ "ECGUsedRxSignal" SG_ 125 BrkTot_Tq_RqArb 1;
BA_ "U_P702_MY2021_Tx" SG_ 125 BrkTot_Tq_RqArb 1;
BA_ "U_CX727_MY2021_Tx" SG_ 125 BrkTot_Tq_RqArb 1;
BA_ "U_T6_MCA_MY2020_Rx" SG_ 125 BrkTot_Tq_RqArb 1;
BA_ "U_P702_MY2021_Rx" SG_ 125 BrkTot_Tq_RqArb 1;
BA_ "U_P702_MY2021_Tx" SG_ 125 BrkTot_Tq_Actl 1;
BA_ "U_CX727_MY2021_Tx" SG_ 125 BrkTot_Tq_Actl 1;
BA_ "U_T6_MCA_MY2020_Rx" SG_ 125 BrkTot_Tq_Actl 1;
BA_ "U_P702_MY2021_Rx" SG_ 125 BrkTot_Tq_Actl 1;
BA_ "U_CX727_MY2021_Rx" SG_ 125 BrkTot_Tq_Actl 1;
BA_ "U_P702_MY2021_Tx" SG_ 125 HsaStat_D_Actl 1;
BA_ "U_CX727_MY2021_Tx" SG_ 125 HsaStat_D_Actl 1;
BA_ "U_T6_MCA_MY2020_Rx" SG_ 125 HsaStat_D_Actl 1;
BA_ "U_P702_MY2021_Rx" SG_ 125 HsaStat_D_Actl 1;
BA_ "CrossOver_InfoCAN" SG_ 125 HsaStat_D_Actl 1;
BA_ "U_P702_MY2021_Tx" SG_ 119 VehTrvlDir_D_Stat 1;
BA_ "GenSigStartValue" SG_ 119 VehTrvlDir_D_Stat 6;
BA_ "GenSigStartValueInteger" SG_ 119 VehTrvlDir_D_Stat 6;
BA_ "U_P702_MY2021_Tx" SG_ 119 VehOverGnd_V_Est 1;
BA_ "U_CX727_MY2021_Tx" SG_ 119 VehOverGnd_V_Est 1;
BA_ "U_P702_MY2021_Rx" SG_ 119 VehOverGnd_V_Est 1;
BA_ "U_CX727_MY2021_Rx" SG_ 119 VehOverGnd_V_Est 1;
BA_ "ECGUsedRxSignal" SG_ 119 VehLongComp_A_Actl 1;
BA_ "U_P702_MY2021_Tx" SG_ 119 VehLongComp_A_Actl 1;
BA_ "U_CX727_MY2021_Tx" SG_ 119 VehLongComp_A_Actl 1;
BA_ "U_T6_MCA_MY2020_Rx" SG_ 119 VehLongComp_A_Actl 1;
BA_ "U_P702_MY2021_Rx" SG_ 119 VehLongComp_A_Actl 1;
BA_ "GenSigStartValue" SG_ 119 VehLongComp_A_Actl 1022;
BA_ "GenSigStartValueInteger" SG_ 119 VehLongComp_A_Actl 1022;
BA_ "ECGUsedRxSignal" SG_ 119 VehLatComp_A_Actl 1;
BA_ "U_P702_MY2021_Tx" SG_ 119 VehLatComp_A_Actl 1;
BA_ "U_CX727_MY2021_Tx" SG_ 119 VehLatComp_A_Actl 1;
BA_ "U_T6_MCA_MY2020_Rx" SG_ 119 VehLatComp_A_Actl 1;
BA_ "U_CX727_MY2021_Rx" SG_ 119 VehLatComp_A_Actl 1;
BA_ "U_P702_MY2021_Rx" SG_ 119 VehLatComp_A_Actl 1;
BA_ "GenSigStartValue" SG_ 119 VehLatComp_A_Actl 1022;
BA_ "GenSigStartValueInteger" SG_ 119 VehLatComp_A_Actl 1022;
BA_ "ECGUsedRxSignal" SG_ 119 VehYawComp_W_Actl 1;
BA_ "U_P702_MY2021_Tx" SG_ 119 VehYawComp_W_Actl 1;
BA_ "U_CX727_MY2021_Tx" SG_ 119 VehYawComp_W_Actl 1;
BA_ "U_T6_MCA_MY2020_Rx" SG_ 119 VehYawComp_W_Actl 1;
BA_ "U_P702_MY2021_Rx" SG_ 119 VehYawComp_W_Actl 1;
BA_ "U_CX727_MY2021_Rx" SG_ 119 VehYawComp_W_Actl 1;
BA_ "GenSigStartValue" SG_ 119 VehYawComp_W_Actl 4094;
BA_ "GenSigStartValueInteger" SG_ 119 VehYawComp_W_Actl 4094;
BA_ "CrossOver_InfoCAN" SG_ 119 VehYawComp_W_Actl 1;
BA_ "U_P702_MY2021_Tx" SG_ 118 BrkCtrFnd_B_Stat 1;
BA_ "GenSigSendType" SG_ 118 BrkCtrFnd_B_Stat 3;
BA_ "U_P702_MY2021_Tx" SG_ 118 AwdLck_Tq_RqMx 1;
BA_ "U_P702_MY2021_Rx" SG_ 118 AwdLck_Tq_RqMx 1;
BA_ "GenSigSendType" SG_ 118 AwdLck_Tq_RqMx 3;
BA_ "U_P702_MY2021_Tx" SG_ 118 AwdLck_Tq_RqMn 1;
BA_ "U_P702_MY2021_Rx" SG_ 118 AwdLck_Tq_RqMn 1;
BA_ "U_P702_MY2021_Tx" SG_ 118 DrvSte_D_Stat 1;
BA_ "U_P702_MY2021_Rx" SG_ 118 DrvSte_D_Stat 1;
BA_ "U_CX727_MY2021_Rx" SG_ 118 DrvSte_D_Stat 1;
BA_ "GenSigSendType" SG_ 118 DrvSte_D_Stat 3;
BA_ "U_P702_MY2021_Tx" SG_ 118 DrvSte_Tq_Rq 1;
BA_ "U_P702_MY2021_Rx" SG_ 118 DrvSte_Tq_Rq 1;
BA_ "U_CX727_MY2021_Rx" SG_ 118 DrvSte_Tq_Rq 1;
BA_ "GenSigStartValueInteger" SG_ 118 DrvSte_Tq_Rq 128;
BA_ "U_P702_MY2021_Tx" SG_ 118 EmgcyBrkLamp_D_Rq 1;
BA_ "U_CX727_MY2021_Tx" SG_ 118 EmgcyBrkLamp_D_Rq 1;
BA_ "GenSigSendType" SG_ 118 EmgcyBrkLamp_D_Rq 3;
BA_ "U_P702_MY2021_Tx" SG_ 118 StopLamp_B_RqBrk 1;
BA_ "U_CX727_MY2021_Tx" SG_ 118 StopLamp_B_RqBrk 1;
BA_ "GenSigSendType" SG_ 118 StopLamp_B_RqBrk 3;
BA_ "U_P702_MY2021_Tx" SG_ 73 immoSubTarget1Data_T1 1;
BA_ "U_CX727_MY2021_Tx" SG_ 73 immoSubTarget1Data_T1 1;
BA_ "U_T6_MCA_MY2020_Rx" SG_ 73 immoSubTarget1Data_T1 1;
BA_ "U_P702_MY2021_Rx" SG_ 73 immoSubTarget1Data_T1 1;
BA_ "U_P702_MY2021_Tx" SG_ 73 immoSubTarget1Cmd_T1 1;
BA_ "U_CX727_MY2021_Tx" SG_ 73 immoSubTarget1Cmd_T1 1;
BA_ "U_T6_MCA_MY2020_Rx" SG_ 73 immoSubTarget1Cmd_T1 1;
BA_ "U_P702_MY2021_Rx" SG_ 73 immoSubTarget1Cmd_T1 1;
BA_ "U_CX727_MY2021_Rx" SG_ 1034 VehicleGGCCData 1;
BA_ "U_T6_MCA_MY2020_Rx" SG_ 1034 VehicleGGCCData 1;
BA_ "U_P702_MY2021_Rx" SG_ 1034 VehicleGGCCData 1;
BA_ "CrossOver_InfoCAN" SG_ 1034 VehicleGGCCData 1;
BA_ "U_T6_MCA_MY2020_Tx" SG_ 1440 TCM_GWOnBoardTester 1;
BA_ "U_P702_MY2021_Tx" SG_ 1440 TCM_GWOnBoardTester 1;
BA_ "GenSigStartValue" SG_ 1440 TCM_GWOnBoardTester 255;
BA_ "ContentDependant" SG_ 1440 TCM_GWOnBoardTester 1;
BA_ "GenSigStartValueInteger" SG_ 1440 TCM_GWOnBoardTester 255;
BA_ "U_T6_MCA_MY2020_Tx" SG_ 1440 TCM_GWNMProxy 1;
BA_ "U_P702_MY2021_Tx" SG_ 1440 TCM_GWNMProxy 1;
BA_ "GenSigStartValue" SG_ 1440 TCM_GWNMProxy 255;
BA_ "ContentDependant" SG_ 1440 TCM_GWNMProxy 1;
BA_ "GenSigStartValueInteger" SG_ 1440 TCM_GWNMProxy 255;
BA_ "U_T6_MCA_MY2020_Tx" SG_ 1440 TCM_AutoSarNMReserved4 1;
BA_ "U_P702_MY2021_Tx" SG_ 1440 TCM_AutoSarNMReserved4 1;
BA_ "GenSigStartValue" SG_ 1440 TCM_AutoSarNMReserved4 255;
BA_ "ContentDependant" SG_ 1440 TCM_AutoSarNMReserved4 1;
BA_ "GenSigStartValueInteger" SG_ 1440 TCM_AutoSarNMReserved4 255;
BA_ "U_T6_MCA_MY2020_Tx" SG_ 1440 TCM_AutoSarNMReserved3 1;
BA_ "U_P702_MY2021_Tx" SG_ 1440 TCM_AutoSarNMReserved3 1;
BA_ "GenSigStartValue" SG_ 1440 TCM_AutoSarNMReserved3 255;
BA_ "ContentDependant" SG_ 1440 TCM_AutoSarNMReserved3 1;
BA_ "GenSigStartValueInteger" SG_ 1440 TCM_AutoSarNMReserved3 255;
BA_ "U_T6_MCA_MY2020_Tx" SG_ 1440 TCM_AutoSarNMReserved2 1;
BA_ "U_P702_MY2021_Tx" SG_ 1440 TCM_AutoSarNMReserved2 1;
BA_ "GenSigStartValue" SG_ 1440 TCM_AutoSarNMReserved2 255;
BA_ "ContentDependant" SG_ 1440 TCM_AutoSarNMReserved2 1;
BA_ "GenSigStartValueInteger" SG_ 1440 TCM_AutoSarNMReserved2 255;
BA_ "U_T6_MCA_MY2020_Tx" SG_ 1440 TCM_AutoSarNMReserved1 1;
BA_ "U_P702_MY2021_Tx" SG_ 1440 TCM_AutoSarNMReserved1 1;
BA_ "GenSigStartValue" SG_ 1440 TCM_AutoSarNMReserved1 255;
BA_ "ContentDependant" SG_ 1440 TCM_AutoSarNMReserved1 1;
BA_ "GenSigStartValueInteger" SG_ 1440 TCM_AutoSarNMReserved1 255;
BA_ "U_T6_MCA_MY2020_Tx" SG_ 1440 TCM_AutoSarNMNodeId 1;
BA_ "U_P702_MY2021_Tx" SG_ 1440 TCM_AutoSarNMNodeId 1;
BA_ "GenSigStartValue" SG_ 1440 TCM_AutoSarNMNodeId 160;
BA_ "ContentDependant" SG_ 1440 TCM_AutoSarNMNodeId 1;
BA_ "GenSigStartValueInteger" SG_ 1440 TCM_AutoSarNMNodeId 160;
BA_ "U_T6_MCA_MY2020_Tx" SG_ 1440 TCM_AutoSarNMControl 1;
BA_ "U_P702_MY2021_Tx" SG_ 1440 TCM_AutoSarNMControl 1;
BA_ "ContentDependant" SG_ 1440 TCM_AutoSarNMControl 1;
BA_ "U_T6_MCA_MY2020_Tx" SG_ 561 TrnMsgTxt2_D_Rq 1;
BA_ "U_P702_MY2021_Tx" SG_ 561 TrnMsgTxt2_D_Rq 1;
BA_ "CrossOver_InfoCAN" SG_ 561 TrnMsgTxt2_D_Rq 1;
BA_ "U_T6_MCA_MY2020_Tx" SG_ 561 TrnMsgTxt_D_Rq 1;
BA_ "U_P702_MY2021_Tx" SG_ 561 TrnMsgTxt_D_Rq 1;
BA_ "CrossOver_InfoCAN" SG_ 561 TrnMsgTxt_D_Rq 1;
BA_ "U_T6_MCA_MY2020_Tx" SG_ 330 TrnAout_W_ActlUnfilt 1;
BA_ "U_P702_MY2021_Tx" SG_ 330 TrnAout_W_ActlUnfilt 1;
BA_ "U_T6_MCA_MY2020_Rx" SG_ 330 TrnAout_W_ActlUnfilt 1;
BA_ "U_P702_MY2021_Rx" SG_ 330 TrnAout_W_ActlUnfilt 1;
BA_ "U_CX727_MY2021_Tx" SG_ 1090 HybVehMde_D_ActlMntr 1;
BA_ "ECGUsedRxSignal" SG_ 1090 HybVehMde_D_ActlMntr 1;
BA_ "U_CX727_MY2021_Tx" SG_ 1090 ChrgStat_D_ActlMntr 1;
BA_ "ECGUsedRxSignal" SG_ 1090 ChrgStat_D_ActlMntr 1;
BA_ "ECGUsedRxSignal" SG_ 1090 VehElRnge_L_Dsply 1;
BA_ "U_P702_MY2021_Tx" SG_ 1090 VehElRnge_L_Dsply 1;
BA_ "GenSigStartValue" SG_ 1090 VehElRnge_L_Dsply 4093;
BA_ "GenSigStartValueInteger" SG_ 1090 VehElRnge_L_Dsply 4095;
BA_ "CrossOver_InfoCAN" SG_ 1090 VehElRnge_L_Dsply 1;
BA_ "U_P702_MY2021_Tx" SG_ 870 EngMdeMsgTxt_D_Rq 1;
BA_ "CrossOver_InfoCAN" SG_ 870 EffRgenThres_Pc_Dsply 1;
BA_ "GenSigStartValue" SG_ 870 EffRgenThres_Pc_Dsply 1023;
BA_ "U_P702_MY2021_Tx" SG_ 870 EffRgenThres_Pc_Dsply 1;
BA_ "U_P702_MY2021_Tx" SG_ 870 RngPerChrgInst_L_Dsply 1;
BA_ "GenSigStartValue" SG_ 870 RngPerChrgInst_L_Dsply 4093;
BA_ "GenSigStartValueInteger" SG_ 870 RngPerChrgInst_L_Dsply 4094;
BA_ "U_P702_MY2021_Tx" SG_ 869 PwrFlowTxt_D_Dsply 1;
BA_ "U_P702_MY2021_Tx" SG_ 869 EngOnMsg2_D_Dsply 1;
BA_ "U_P702_MY2021_Tx" SG_ 869 EngOnMsg1_D_Dsply 1;
BA_ "U_P702_MY2021_Tx" SG_ 869 FuelMaintMde_D_Dsply 1;
BA_ "U_P702_MY2021_Tx" SG_ 869 EffWhlLvl2_Pc_Dsply 1;
BA_ "GenSigStartValueInteger" SG_ 869 EffWhlLvl2_Pc_Dsply 511;
BA_ "CrossOver_InfoCAN" SG_ 869 EffWhlLvl2_Pc_Dsply 1;
BA_ "U_P702_MY2021_Tx" SG_ 869 EffWhlThres_Pc_Dsply 1;
BA_ "CrossOver_InfoCAN" SG_ 869 EffWhlThres_Pc_Dsply 1;
BA_ "U_P702_MY2021_Tx" SG_ 869 EngPwLvl_Pc_Dsply 1;
BA_ "CrossOver_InfoCAN" SG_ 869 EngPwLvl_Pc_Dsply 1;
BA_ "U_P702_MY2021_Tx" SG_ 869 EngActv_B_Dsply 1;
BA_ "CrossOver_InfoCAN" SG_ 869 EngActv_B_Dsply 1;
BA_ "U_P702_MY2021_Tx" SG_ 869 EffWhlThresOn_B_Dsply 1;
BA_ "CrossOver_InfoCAN" SG_ 869 EffWhlThresOn_B_Dsply 1;
BA_ "U_P702_MY2021_Tx" SG_ 606 ElVehLaterMde_D_Stat 1;
BA_ "GenSigSendType" SG_ 606 ElVehLaterMde_D_Stat 3;
BA_ "U_P702_MY2021_Tx" SG_ 606 ElVehNowMde_D_Stat 1;
BA_ "GenSigSendType" SG_ 606 ElVehNowMde_D_Stat 3;
BA_ "U_P702_MY2021_Tx" SG_ 374 GearEngag_D_Actl 1;
BA_ "GenSigSendType" SG_ 374 GearEngag_D_Actl 3;
BA_ "U_T6_MCA_MY2020_Tx" SG_ 374 TrnRng_D_Rq 1;
BA_ "U_P702_MY2021_Tx" SG_ 374 TrnRng_D_Rq 1;
BA_ "U_T6_MCA_MY2020_Rx" SG_ 374 TrnRng_D_Rq 1;
BA_ "U_P702_MY2021_Rx" SG_ 374 TrnRng_D_Rq 1;
BA_ "GenSigSendType" SG_ 374 TrnRng_D_Rq 3;
BA_ "GenSigStartValue" SG_ 374 TrnRng_D_Rq 14;
BA_ "ContentDependant" SG_ 374 TrnRng_D_Rq 1;
BA_ "GenSigStartValueInteger" SG_ 374 TrnRng_D_Rq 14;
BA_ "U_T6_MCA_MY2020_Tx" SG_ 374 TrnPrkSys_D_Actl 1;
BA_ "U_P702_MY2021_Tx" SG_ 374 TrnPrkSys_D_Actl 1;
BA_ "U_T6_MCA_MY2020_Rx" SG_ 374 TrnPrkSys_D_Actl 1;
BA_ "U_P702_MY2021_Rx" SG_ 374 TrnPrkSys_D_Actl 1;
BA_ "GenSigSendType" SG_ 374 TrnPrkSys_D_Actl 3;
BA_ "ContentDependant" SG_ 374 TrnPrkSys_D_Actl 1;
BA_ "U_T6_MCA_MY2020_Tx" SG_ 374 GearLvr_D_ActlDrv 1;
BA_ "U_P702_MY2021_Tx" SG_ 374 GearLvr_D_ActlDrv 1;
BA_ "U_T6_MCA_MY2020_Rx" SG_ 374 GearLvr_D_ActlDrv 1;
BA_ "U_P702_MY2021_Rx" SG_ 374 GearLvr_D_ActlDrv 1;
BA_ "GenSigSendType" SG_ 374 GearLvr_D_ActlDrv 3;
BA_ "ContentDependant" SG_ 374 GearLvr_D_ActlDrv 1;
BA_ "U_T6_MCA_MY2020_Tx" SG_ 374 GearPos_No_Cs 1;
BA_ "U_P702_MY2021_Tx" SG_ 374 GearPos_No_Cs 1;
BA_ "U_CX727_MY2021_Rx" SG_ 374 GearPos_No_Cs 1;
BA_ "U_T6_MCA_MY2020_Rx" SG_ 374 GearPos_No_Cs 1;
BA_ "U_P702_MY2021_Rx" SG_ 374 GearPos_No_Cs 1;
BA_ "MetaData" SG_ 374 GearPos_No_Cs 1;
BA_ "ContentDependant" SG_ 374 GearPos_No_Cs 1;
BA_ "U_T6_MCA_MY2020_Tx" SG_ 374 GearPos_D_Trg 1;
BA_ "U_P702_MY2021_Tx" SG_ 374 GearPos_D_Trg 1;
BA_ "U_CX727_MY2021_Rx" SG_ 374 GearPos_D_Trg 1;
BA_ "U_T6_MCA_MY2020_Rx" SG_ 374 GearPos_D_Trg 1;
BA_ "U_P702_MY2021_Rx" SG_ 374 GearPos_D_Trg 1;
BA_ "GenSigSendType" SG_ 374 GearPos_D_Trg 3;
BA_ "GenSigStartValue" SG_ 374 GearPos_D_Trg 15;
BA_ "ContentDependant" SG_ 374 GearPos_D_Trg 1;
BA_ "GenSigStartValueInteger" SG_ 374 GearPos_D_Trg 15;
BA_ "CrossOver_InfoCAN" SG_ 374 GearPos_D_Trg 1;
BA_ "U_T6_MCA_MY2020_Tx" SG_ 374 GearPos_No_Cnt 1;
BA_ "U_P702_MY2021_Tx" SG_ 374 GearPos_No_Cnt 1;
BA_ "U_CX727_MY2021_Rx" SG_ 374 GearPos_No_Cnt 1;
BA_ "U_T6_MCA_MY2020_Rx" SG_ 374 GearPos_No_Cnt 1;
BA_ "U_P702_MY2021_Rx" SG_ 374 GearPos_No_Cnt 1;
BA_ "MetaData" SG_ 374 GearPos_No_Cnt 1;
BA_ "ContentDependant" SG_ 374 GearPos_No_Cnt 1;
BA_ "U_T6_MCA_MY2020_Tx" SG_ 374 TrnIgnOffDly_T_Rq 1;
BA_ "U_P702_MY2021_Tx" SG_ 374 TrnIgnOffDly_T_Rq 1;
BA_ "U_T6_MCA_MY2020_Tx" SG_ 374 GearPos_D_Actl 1;
BA_ "U_P702_MY2021_Tx" SG_ 374 GearPos_D_Actl 1;
BA_ "U_CX727_MY2021_Rx" SG_ 374 GearPos_D_Actl 1;
BA_ "U_T6_MCA_MY2020_Rx" SG_ 374 GearPos_D_Actl 1;
BA_ "U_P702_MY2021_Rx" SG_ 374 GearPos_D_Actl 1;
BA_ "GenSigSendType" SG_ 374 GearPos_D_Actl 3;
BA_ "GenSigStartValue" SG_ 374 GearPos_D_Actl 15;
BA_ "ContentDependant" SG_ 374 GearPos_D_Actl 1;
BA_ "GenSigStartValueInteger" SG_ 374 GearPos_D_Actl 15;
BA_ "U_P702_MY2021_Tx" SG_ 603 WhlDirAvgDrv_D_Actl 1;
BA_ "ContentDependant" SG_ 603 WhlDirAvgDrv_D_Actl 1;
BA_ "U_P702_MY2021_Tx" SG_ 603 PrplTqMnRgen_B_Actl 1;
BA_ "ContentDependant" SG_ 603 PrplTqMnRgen_B_Actl 1;
BA_ "U_P702_MY2021_Tx" SG_ 603 BattTracCnnct_D_Rq 1;
BA_ "ContentDependant" SG_ 603 BattTracCnnct_D_Rq 1;
BA_ "GenSigStartValue" SG_ 603 BattTracCnnct_D_Rq 2;
BA_ "ECGUsedRxSignal" SG_ 602 HtrnWarnLamp_B_Dsply 1;
BA_ "U_P702_MY2021_Tx" SG_ 602 HtrnWarnLamp_B_Dsply 1;
BA_ "CrossOver_InfoCAN" SG_ 602 HtrnWarnLamp_B_Dsply 1;
BA_ "U_P702_MY2021_Tx" SG_ 602 PwPckTqRdy_B_Dsply 1;
BA_ "CrossOver_InfoCAN" SG_ 602 PwPckTqRdy_B_Dsply 1;
BA_ "GenSigSendType" SG_ 1152 BattTracDiagClr_B_Stat 3;
BA_ "U_P702_MY2021_Tx" SG_ 1152 EngTeHi_B_Actl 1;
BA_ "GenSigSendType" SG_ 1152 EngTeHi_B_Actl 3;
BA_ "U_P702_MY2021_Tx" SG_ 1152 DcdcOn_B_Rq 1;
BA_ "GenSigSendType" SG_ 1152 DcdcOn_B_Rq 3;
BA_ "U_P702_MY2021_Tx" SG_ 1152 ULoBattSpprtSustn_B_Rq 1;
BA_ "GenSigSendType" SG_ 1152 ULoBattSpprtSustn_B_Rq 3;
BA_ "U_P702_MY2021_Tx" SG_ 1152 VehElEff_No_Avg 1;
BA_ "GenSigStartValue" SG_ 1152 VehElEff_No_Avg 126;
BA_ "GenSigStartValueInteger" SG_ 1152 VehElEff_No_Avg 126;
BA_ "ECGUsedRxSignal" SG_ 872 HybMdeStat_D_Dsply 1;
BA_ "U_P702_MY2021_Tx" SG_ 872 HybMdeStat_D_Dsply 1;
BA_ "U_T6_MCA_MY2020_Tx" SG_ 560 SelDrvMdeSwtch_D_Stat3 1;
BA_ "U_P702_MY2021_Tx" SG_ 560 SelDrvMdeSwtch_D_Stat3 1;
BA_ "U_P702_MY2021_Rx" SG_ 560 SelDrvMdeSwtch_D_Stat3 1;
BA_ "ContentDependant" SG_ 560 SelDrvMdeSwtch_D_Stat3 1;
BA_ "ECGUsedRxSignal" SG_ 560 TrnSrvcRqd_B_Rq 1;
BA_ "U_T6_MCA_MY2020_Tx" SG_ 560 TrnSrvcRqd_B_Rq 1;
BA_ "U_P702_MY2021_Tx" SG_ 560 TrnSrvcRqd_B_Rq 1;
BA_ "ContentDependant" SG_ 560 TrnSrvcRqd_B_Rq 1;
BA_ "CrossOver_InfoCAN" SG_ 560 TrnSrvcRqd_B_Rq 1;
BA_ "U_T6_MCA_MY2020_Tx" SG_ 560 TrnShifActv_B_Actl 1;
BA_ "U_P702_MY2021_Tx" SG_ 560 TrnShifActv_B_Actl 1;
BA_ "U_CX727_MY2021_Rx" SG_ 560 TrnShifActv_B_Actl 1;
BA_ "U_T6_MCA_MY2020_Rx" SG_ 560 TrnShifActv_B_Actl 1;
BA_ "U_P702_MY2021_Rx" SG_ 560 TrnShifActv_B_Actl 1;
BA_ "ContentDependant" SG_ 560 TrnShifActv_B_Actl 1;
BA_ "U_T6_MCA_MY2020_Tx" SG_ 560 GearLvrPos_D_Actl 1;
BA_ "U_P702_MY2021_Tx" SG_ 560 GearLvrPos_D_Actl 1;
BA_ "U_CX727_MY2021_Rx" SG_ 560 GearLvrPos_D_Actl 1;
BA_ "U_T6_MCA_MY2020_Rx" SG_ 560 GearLvrPos_D_Actl 1;
BA_ "U_P702_MY2021_Rx" SG_ 560 GearLvrPos_D_Actl 1;
BA_ "GenSigStartValue" SG_ 560 GearLvrPos_D_Actl 14;
BA_ "GenSigStartValueInteger" SG_ 560 GearLvrPos_D_Actl 14;
BA_ "CrossOver_InfoCAN" SG_ 560 GearLvrPos_D_Actl 1;
BA_ "U_T6_MCA_MY2020_Tx" SG_ 560 GboxOil_Te_Actl 1;
BA_ "U_P702_MY2021_Tx" SG_ 560 GboxOil_Te_Actl 1;
BA_ "U_T6_MCA_MY2020_Rx" SG_ 560 GboxOil_Te_Actl 1;
BA_ "U_P702_MY2021_Rx" SG_ 560 GboxOil_Te_Actl 1;
BA_ "GenSigStartValue" SG_ 560 GboxOil_Te_Actl 254;
BA_ "ContentDependant" SG_ 560 GboxOil_Te_Actl 1;
BA_ "GenSigStartValueInteger" SG_ 560 GboxOil_Te_Actl 254;
BA_ "U_T6_MCA_MY2020_Tx" SG_ 369 TrnIpcDsplyRng2_D_Actl 1;
BA_ "U_P702_MY2021_Tx" SG_ 369 TrnIpcDsplyRng2_D_Actl 1;
BA_ "GenSigStartValue" SG_ 369 TrnIpcDsplyRng2_D_Actl 15;
BA_ "GenSigStartValueInteger" SG_ 369 TrnIpcDsplyRng2_D_Actl 15;
BA_ "U_T6_MCA_MY2020_Tx" SG_ 369 TrnIpcDsplyRng_D_Stat 1;
BA_ "U_P702_MY2021_Tx" SG_ 369 TrnIpcDsplyRng_D_Stat 1;
BA_ "U_T6_MCA_MY2020_Tx" SG_ 369 TrnIpcDsplyGear_D_Actl 1;
BA_ "U_P702_MY2021_Tx" SG_ 369 TrnIpcDsplyGear_D_Actl 1;
BA_ "GenSigStartValue" SG_ 369 TrnIpcDsplyGear_D_Actl 15;
BA_ "GenSigStartValueInteger" SG_ 369 TrnIpcDsplyGear_D_Actl 15;
BA_ "CrossOver_InfoCAN" SG_ 369 TrnIpcDsplyGear_D_Actl 1;
BA_ "U_T6_MCA_MY2020_Tx" SG_ 369 TrnIpcDsplyMde_D_Stat 1;
BA_ "U_P702_MY2021_Tx" SG_ 369 TrnIpcDsplyMde_D_Stat 1;
BA_ "CrossOver_InfoCAN" SG_ 369 TrnIpcDsplyMde_D_Stat 1;
BA_ "WakeupSignal" SG_ 369 TrnIpcDsplyMde_D_Stat 1;
BA_ "U_T6_MCA_MY2020_Tx" SG_ 369 TrnIpcDsplyMde_D_Actl 1;
BA_ "U_P702_MY2021_Tx" SG_ 369 TrnIpcDsplyMde_D_Actl 1;
BA_ "CrossOver_InfoCAN" SG_ 369 TrnIpcDsplyMde_D_Actl 1;
BA_ "WakeupSignal" SG_ 369 TrnIpcDsplyMde_D_Actl 1;
BA_ "U_T6_MCA_MY2020_Tx" SG_ 369 TrnIpcDsplyGear_D_Stat 1;
BA_ "U_P702_MY2021_Tx" SG_ 369 TrnIpcDsplyGear_D_Stat 1;
BA_ "CrossOver_InfoCAN" SG_ 369 TrnIpcDsplyGear_D_Stat 1;
BA_ "U_T6_MCA_MY2020_Tx" SG_ 92 TrnLvrV_D_Rq 1;
BA_ "U_P702_MY2021_Tx" SG_ 92 TrnLvrV_D_Rq 1;
BA_ "GenSigSendType" SG_ 92 TrnLvrV_D_Rq 3;
BA_ "GenSigStartValue" SG_ 92 TrnLvrV_D_Rq 1;
BA_ "GenSigStartValueInteger" SG_ 92 TrnLvrV_D_Rq 1;
BA_ "U_T6_MCA_MY2020_Tx" SG_ 92 TrnSbwSysHlth_D_Actl 1;
BA_ "U_P702_MY2021_Tx" SG_ 92 TrnSbwSysHlth_D_Actl 1;
BA_ "GenSigSendType" SG_ 92 TrnSbwSysHlth_D_Actl 3;
BA_ "GenSigStartValue" SG_ 92 TrnSbwSysHlth_D_Actl 1;
BA_ "ContentDependant" SG_ 92 TrnSbwSysHlth_D_Actl 1;
BA_ "GenSigStartValueInteger" SG_ 92 TrnSbwSysHlth_D_Actl 1;
BA_ "U_T6_MCA_MY2020_Tx" SG_ 92 TrnGearNtmAllow_B_Stat 1;
BA_ "U_P702_MY2021_Tx" SG_ 92 TrnGearNtmAllow_B_Stat 1;
BA_ "GenSigSendType" SG_ 92 TrnGearNtmAllow_B_Stat 3;
BA_ "ContentDependant" SG_ 92 TrnGearNtmAllow_B_Stat 1;
BA_ "CrossOver_InfoCAN" SG_ 92 TrnGearNtmAllow_B_Stat 1;
BA_ "U_T6_MCA_MY2020_Tx" SG_ 92 TrnDtpCmd_D_Actl 1;
BA_ "U_P702_MY2021_Tx" SG_ 92 TrnDtpCmd_D_Actl 1;
BA_ "GenSigSendType" SG_ 92 TrnDtpCmd_D_Actl 3;
BA_ "GenSigStartValue" SG_ 92 TrnDtpCmd_D_Actl 1;
BA_ "ContentDependant" SG_ 92 TrnDtpCmd_D_Actl 1;
BA_ "GenSigStartValueInteger" SG_ 92 TrnDtpCmd_D_Actl 1;
BA_ "WakeupSignal" SG_ 92 TrnDtpCmd_D_Actl 1;
BA_ "U_T6_MCA_MY2020_Tx" SG_ 92 GearSelLck_D_Rq 1;
BA_ "U_P702_MY2021_Tx" SG_ 92 GearSelLck_D_Rq 1;
BA_ "GenSigSendType" SG_ 92 GearSelLck_D_Rq 3;
BA_ "U_T6_MCA_MY2020_Tx" SG_ 92 TrnGearCmd_No_Cs 1;
BA_ "U_P702_MY2021_Tx" SG_ 92 TrnGearCmd_No_Cs 1;
BA_ "MetaData" SG_ 92 TrnGearCmd_No_Cs 1;
BA_ "ContentDependant" SG_ 92 TrnGearCmd_No_Cs 1;
BA_ "U_T6_MCA_MY2020_Tx" SG_ 92 TrnValidGear_D_Cnfm 1;
BA_ "U_P702_MY2021_Tx" SG_ 92 TrnValidGear_D_Cnfm 1;
BA_ "GenSigSendType" SG_ 92 TrnValidGear_D_Cnfm 3;
BA_ "ContentDependant" SG_ 92 TrnValidGear_D_Cnfm 1;
BA_ "U_T6_MCA_MY2020_Tx" SG_ 92 TrnNtrlTowCmd_D_Actl 1;
BA_ "U_P702_MY2021_Tx" SG_ 92 TrnNtrlTowCmd_D_Actl 1;
BA_ "U_P702_MY2021_Rx" SG_ 92 TrnNtrlTowCmd_D_Actl 1;
BA_ "U_CX727_MY2021_Rx" SG_ 92 TrnNtrlTowCmd_D_Actl 1;
BA_ "GenSigSendType" SG_ 92 TrnNtrlTowCmd_D_Actl 3;
BA_ "ContentDependant" SG_ 92 TrnNtrlTowCmd_D_Actl 1;
BA_ "U_T6_MCA_MY2020_Tx" SG_ 92 TrnGearCmd_Pc_ActlPt 1;
BA_ "U_P702_MY2021_Tx" SG_ 92 TrnGearCmd_Pc_ActlPt 1;
BA_ "ContentDependant" SG_ 92 TrnGearCmd_Pc_ActlPt 1;
BA_ "U_T6_MCA_MY2020_Tx" SG_ 92 TrnGear_D_RqPt 1;
BA_ "U_P702_MY2021_Tx" SG_ 92 TrnGear_D_RqPt 1;
BA_ "GenSigSendType" SG_ 92 TrnGear_D_RqPt 3;
BA_ "ContentDependant" SG_ 92 TrnGear_D_RqPt 1;
BA_ "U_T6_MCA_MY2020_Tx" SG_ 92 TrnCmdState_B_Actl 1;
BA_ "U_P702_MY2021_Tx" SG_ 92 TrnCmdState_B_Actl 1;
BA_ "GenSigSendType" SG_ 92 TrnCmdState_B_Actl 3;
BA_ "ContentDependant" SG_ 92 TrnCmdState_B_Actl 1;
BA_ "U_T6_MCA_MY2020_Tx" SG_ 92 TrnCmdCnt_B_Actl 1;
BA_ "U_P702_MY2021_Tx" SG_ 92 TrnCmdCnt_B_Actl 1;
BA_ "ContentDependant" SG_ 92 TrnCmdCnt_B_Actl 1;
BA_ "U_T6_MCA_MY2020_Tx" SG_ 92 PrkBrkActv_D_RqTrnGear 1;
BA_ "U_P702_MY2021_Tx" SG_ 92 PrkBrkActv_D_RqTrnGear 1;
BA_ "U_P702_MY2021_Rx" SG_ 92 PrkBrkActv_D_RqTrnGear 1;
BA_ "U_CX727_MY2021_Rx" SG_ 92 PrkBrkActv_D_RqTrnGear 1;
BA_ "GenSigSendType" SG_ 92 PrkBrkActv_D_RqTrnGear 3;
BA_ "GenSigStartValue" SG_ 92 PrkBrkActv_D_RqTrnGear 1;
BA_ "ContentDependant" SG_ 92 PrkBrkActv_D_RqTrnGear 1;
BA_ "GenSigStartValueInteger" SG_ 92 PrkBrkActv_D_RqTrnGear 1;
BA_ "U_T6_MCA_MY2020_Tx" SG_ 92 TrnGearMsgTxt_D_Rq 1;
BA_ "U_P702_MY2021_Tx" SG_ 92 TrnGearMsgTxt_D_Rq 1;
BA_ "GenSigSendType" SG_ 92 TrnGearMsgTxt_D_Rq 3;
BA_ "ContentDependant" SG_ 92 TrnGearMsgTxt_D_Rq 1;
BA_ "CrossOver_InfoCAN" SG_ 92 TrnGearMsgTxt_D_Rq 1;
BA_ "U_T6_MCA_MY2020_Tx" SG_ 92 TrnGearCmd_No_Cnt 1;
BA_ "U_P702_MY2021_Tx" SG_ 92 TrnGearCmd_No_Cnt 1;
BA_ "MetaData" SG_ 92 TrnGearCmd_No_Cnt 1;
BA_ "ContentDependant" SG_ 92 TrnGearCmd_No_Cnt 1;
BA_ "U_T6_MCA_MY2020_Tx" SG_ 2030 TesterPhysicalResSOBDMC 1;
BA_ "U_P702_MY2021_Tx" SG_ 2030 TesterPhysicalResSOBDMC 1;
BA_ "GenSigSendType" SG_ 1087 DcacFaltMsgTxt_D2_Rq 3;
BA_ "GenSigStartValueInteger" SG_ 1087 DcacFaltMsgTxt_D2_Rq 1;
BA_ "ECGUsedRxSignal" SG_ 1087 DcacFaltMsgTxt_D2_Rq 1;
BA_ "GenSigSendType" SG_ 1087 StopStrtCstm_D_Stat 3;
BA_ "ECGUsedRxSignal" SG_ 1087 StopStrtCstm_D_Stat 1;
BA_ "GenSigSendType" SG_ 1087 SelDrvMdeCstmPt_D_Stat 3;
BA_ "ECGUsedRxSignal" SG_ 1087 SelDrvMdeCstmPt_D_Stat 1;
BA_ "GenSigSendType" SG_ 1087 ClimtCool_D_RqPt 3;
BA_ "GenSigSendType" SG_ 1087 BtsiShifInhbt_B_RqPt 3;
BA_ "GenSigSendType" SG_ 1087 BattRgenLoChrg_D_RqEng 3;
BA_ "U_P702_MY2021_Tx" SG_ 1087 BattRgenLoChrg_D_RqEng 1;
BA_ "GenSigSendType" SG_ 1087 AdasLcObtclAbrt_B_Stat 3;
BA_ "GenSigSendType" SG_ 1087 BattRgenLoDChrg_D_RqEng 3;
BA_ "U_P702_MY2021_Tx" SG_ 1087 BattRgenLoDChrg_D_RqEng 1;
BA_ "U_T6_MCA_MY2020_Tx" SG_ 1087 FapLcInhbt_B_Rq 1;
BA_ "U_P702_MY2021_Tx" SG_ 1087 FapLcInhbt_B_Rq 1;
BA_ "GenSigSendType" SG_ 1087 FapLcInhbt_B_Rq 3;
BA_ "U_T6_MCA_MY2020_Tx" SG_ 1087 FapLcStopHold_B_Rq 1;
BA_ "U_P702_MY2021_Tx" SG_ 1087 FapLcStopHold_B_Rq 1;
BA_ "U_P702_MY2021_Rx" SG_ 1087 FapLcStopHold_B_Rq 1;
BA_ "U_CX727_MY2021_Rx" SG_ 1087 FapLcStopHold_B_Rq 1;
BA_ "GenSigSendType" SG_ 1087 FapLcStopHold_B_Rq 3;
BA_ "U_T6_MCA_MY2020_Tx" SG_ 1087 FapLcPrchgBrk_B_Rq 1;
BA_ "U_P702_MY2021_Tx" SG_ 1087 FapLcPrchgBrk_B_Rq 1;
BA_ "U_P702_MY2021_Rx" SG_ 1087 FapLcPrchgBrk_B_Rq 1;
BA_ "U_CX727_MY2021_Rx" SG_ 1087 FapLcPrchgBrk_B_Rq 1;
BA_ "GenSigSendType" SG_ 1087 FapLcPrchgBrk_B_Rq 3;
BA_ "U_T6_MCA_MY2020_Tx" SG_ 1087 FapLcObstcl_B_Stat 1;
BA_ "U_P702_MY2021_Tx" SG_ 1087 FapLcObstcl_B_Stat 1;
BA_ "GenSigSendType" SG_ 1087 FapLcObstcl_B_Stat 3;
BA_ "U_T6_MCA_MY2020_Tx" SG_ 1087 FapLcMaxGrdInhbt_B_Stat 1;
BA_ "U_P702_MY2021_Tx" SG_ 1087 FapLcMaxGrdInhbt_B_Stat 1;
BA_ "GenSigSendType" SG_ 1087 FapLcMaxGrdInhbt_B_Stat 3;
BA_ "U_T6_MCA_MY2020_Tx" SG_ 1087 FapLcMaxGrdAbrt_B_Stat 1;
BA_ "U_P702_MY2021_Tx" SG_ 1087 FapLcMaxGrdAbrt_B_Stat 1;
BA_ "GenSigSendType" SG_ 1087 FapLcMaxGrdAbrt_B_Stat 3;
BA_ "U_T6_MCA_MY2020_Tx" SG_ 1087 FapLcActv_B_Stat 1;
BA_ "U_P702_MY2021_Tx" SG_ 1087 FapLcActv_B_Stat 1;
BA_ "GenSigSendType" SG_ 1087 FapLcActv_B_Stat 3;
BA_ "U_T6_MCA_MY2020_Tx" SG_ 332 UreaLvlQlty_D_RqDsply 1;
BA_ "U_P702_MY2021_Tx" SG_ 332 UreaLvlQlty_D_RqDsply 1;
BA_ "CrossOver_InfoCAN" SG_ 332 UreaLvlQlty_D_RqDsply 1;
BA_ "U_T6_MCA_MY2020_Tx" SG_ 332 UreaLvlTxtWarn_D_Rq 1;
BA_ "U_P702_MY2021_Tx" SG_ 332 UreaLvlTxtWarn_D_Rq 1;
BA_ "CrossOver_InfoCAN" SG_ 332 UreaLvlTxtWarn_D_Rq 1;
BA_ "U_T6_MCA_MY2020_Tx" SG_ 332 UreaQltySysWarn_D_Rq 1;
BA_ "U_P702_MY2021_Tx" SG_ 332 UreaQltySysWarn_D_Rq 1;
BA_ "CrossOver_InfoCAN" SG_ 332 UreaQltySysWarn_D_Rq 1;
BA_ "U_T6_MCA_MY2020_Tx" SG_ 332 DieslPrtcWarn_D_Rq 1;
BA_ "U_P702_MY2021_Tx" SG_ 332 DieslPrtcWarn_D_Rq 1;
BA_ "ECGUsedRxSignal" SG_ 332 UreaQltyFlg_B_RqDsply 1;
BA_ "U_T6_MCA_MY2020_Tx" SG_ 332 UreaQltyFlg_B_RqDsply 1;
BA_ "U_P702_MY2021_Tx" SG_ 332 UreaQltyFlg_B_RqDsply 1;
BA_ "ECGUsedRxSignal" SG_ 332 UreaLvl_Pc_Actl 1;
BA_ "U_T6_MCA_MY2020_Tx" SG_ 332 UreaLvl_Pc_Actl 1;
BA_ "U_P702_MY2021_Tx" SG_ 332 UreaLvl_Pc_Actl 1;
BA_ "ECGUsedRxSignal" SG_ 332 VehUreaRnge2_L_DsplyMx 1;
BA_ "U_T6_MCA_MY2020_Tx" SG_ 332 VehUreaRnge2_L_DsplyMx 1;
BA_ "U_P702_MY2021_Tx" SG_ 332 VehUreaRnge2_L_DsplyMx 1;
BA_ "ECGUsedRxSignal" SG_ 332 UreaQltySys_D_RqDsply 1;
BA_ "U_T6_MCA_MY2020_Tx" SG_ 332 UreaQltySys_D_RqDsply 1;
BA_ "U_P702_MY2021_Tx" SG_ 332 UreaQltySys_D_RqDsply 1;
BA_ "CrossOver_InfoCAN" SG_ 332 UreaQltySys_D_RqDsply 1;
BA_ "ECGUsedRxSignal" SG_ 332 UreaLvlTxt_D_RqDsply 1;
BA_ "U_T6_MCA_MY2020_Tx" SG_ 332 UreaLvlTxt_D_RqDsply 1;
BA_ "U_P702_MY2021_Tx" SG_ 332 UreaLvlTxt_D_RqDsply 1;
BA_ "CrossOver_InfoCAN" SG_ 332 UreaLvlTxt_D_RqDsply 1;
BA_ "ECGUsedRxSignal" SG_ 332 VehUreaWarn_V_DsplyMx 1;
BA_ "U_T6_MCA_MY2020_Tx" SG_ 332 VehUreaWarn_V_DsplyMx 1;
BA_ "U_P702_MY2021_Tx" SG_ 332 VehUreaWarn_V_DsplyMx 1;
BA_ "CrossOver_InfoCAN" SG_ 332 VehUreaWarn_V_DsplyMx 1;
BA_ "U_P702_MY2021_Tx" SG_ 1896 TesterPhysicalResABS 1;
BA_ "U_CX727_MY2021_Tx" SG_ 1896 TesterPhysicalResABS 1;
BA_ "GenSigSendType" SG_ 1896 TesterPhysicalResABS 3;
BA_ "U_P702_MY2021_Rx" SG_ 1889 TesterPhysicalReqTCCM 1;
BA_ "GenSigSendType" SG_ 1889 TesterPhysicalReqTCCM 3;
BA_ "U_P702_MY2021_Rx" SG_ 1888 TesterPhysicalReqABS 1;
BA_ "U_CX727_MY2021_Rx" SG_ 1888 TesterPhysicalReqABS 1;
BA_ "GenSigSendType" SG_ 1888 TesterPhysicalReqABS 3;
BA_ "U_P702_MY2021_Tx" SG_ 1848 TesterPhysicalResPSCM 1;
BA_ "U_CX727_MY2021_Tx" SG_ 1848 TesterPhysicalResPSCM 1;
BA_ "U_P702_MY2021_Rx" SG_ 1840 TesterPhysicalReqPSCM 1;
BA_ "U_CX727_MY2021_Rx" SG_ 1840 TesterPhysicalReqPSCM 1;
BA_ "GenSigSendType" SG_ 1840 TesterPhysicalReqPSCM 3;
BA_ "U_P702_MY2021_Tx" SG_ 1713 UUDTABSResponse2 1;
BA_ "U_P702_MY2021_Tx" SG_ 1712 UUDTABSResponse1 1;
BA_ "U_T6_MCA_MY2020_Tx" SG_ 2025 TesterPhysicalResTCM 1;
BA_ "U_P702_MY2021_Tx" SG_ 2025 TesterPhysicalResTCM 1;
BA_ "U_T6_MCA_MY2020_Tx" SG_ 2024 TesterPhysicalResPCM 1;
BA_ "U_P702_MY2021_Tx" SG_ 2024 TesterPhysicalResPCM 1;
BA_ "U_T6_MCA_MY2020_Rx" SG_ 2017 TesterPhysicalReqTCM 1;
BA_ "U_P702_MY2021_Rx" SG_ 2017 TesterPhysicalReqTCM 1;
BA_ "GenSigSendType" SG_ 2017 TesterPhysicalReqTCM 3;
BA_ "U_T6_MCA_MY2020_Rx" SG_ 2016 TesterPhysicalReqPCM 1;
BA_ "U_P702_MY2021_Rx" SG_ 2016 TesterPhysicalReqPCM 1;
BA_ "GenSigSendType" SG_ 2016 TesterPhysicalReqPCM 3;
BA_ "ECGUsedRxSignal" SG_ 2015 TesterFunctionalReq 1;
BA_ "U_T6_MCA_MY2020_Rx" SG_ 2015 TesterFunctionalReq 1;
BA_ "U_P702_MY2021_Rx" SG_ 2015 TesterFunctionalReq 1;
BA_ "U_CX727_MY2021_Rx" SG_ 2015 TesterFunctionalReq 1;
BA_ "GenSigSendType" SG_ 2015 TesterFunctionalReq 3;
BA_ "CrossOver_InfoCAN" SG_ 2015 TesterFunctionalReq 1;
BA_ "U_P702_MY2021_Tx" SG_ 1897 TesterPhysicalResTCCM 1;
BA_ "GenSigSendType" SG_ 1897 TesterPhysicalResTCCM 3;
BA_ "ECGUsedRxSignal" SG_ 1814 TesterPhysicalReqGWM_F1 1;
BA_ "GenSigSendType" SG_ 1814 TesterPhysicalReqGWM_F1 3;
BA_ "U_T6_MCA_MY2020_Tx" SG_ 1701 UUDTTCMResponse2 1;
BA_ "U_P702_MY2021_Tx" SG_ 1701 UUDTTCMResponse2 1;
BA_ "U_T6_MCA_MY2020_Tx" SG_ 1700 UUDTTCMResponse1 1;
BA_ "U_P702_MY2021_Tx" SG_ 1700 UUDTTCMResponse1 1;
BA_ "U_T6_MCA_MY2020_Tx" SG_ 1697 UUDTPCMResponse2 1;
BA_ "U_P702_MY2021_Tx" SG_ 1697 UUDTPCMResponse2 1;
BA_ "U_T6_MCA_MY2020_Tx" SG_ 1696 UUDTPCMResponse1 1;
BA_ "U_P702_MY2021_Tx" SG_ 1696 UUDTPCMResponse1 1;
BA_ "U_T6_MCA_MY2020_Tx" SG_ 1429 PCM_GWOnBoardTester 1;
BA_ "U_P702_MY2021_Tx" SG_ 1429 PCM_GWOnBoardTester 1;
BA_ "U_T6_MCA_MY2020_Rx" SG_ 1429 PCM_GWOnBoardTester 1;
BA_ "U_P702_MY2021_Rx" SG_ 1429 PCM_GWOnBoardTester 1;
BA_ "GenSigStartValue" SG_ 1429 PCM_GWOnBoardTester 255;
BA_ "ContentDependant" SG_ 1429 PCM_GWOnBoardTester 1;
BA_ "GenSigStartValueInteger" SG_ 1429 PCM_GWOnBoardTester 255;
BA_ "U_T6_MCA_MY2020_Tx" SG_ 1429 PCM_GWNMProxy 1;
BA_ "U_P702_MY2021_Tx" SG_ 1429 PCM_GWNMProxy 1;
BA_ "U_T6_MCA_MY2020_Rx" SG_ 1429 PCM_GWNMProxy 1;
BA_ "U_P702_MY2021_Rx" SG_ 1429 PCM_GWNMProxy 1;
BA_ "GenSigStartValue" SG_ 1429 PCM_GWNMProxy 255;
BA_ "ContentDependant" SG_ 1429 PCM_GWNMProxy 1;
BA_ "GenSigStartValueInteger" SG_ 1429 PCM_GWNMProxy 255;
BA_ "U_T6_MCA_MY2020_Tx" SG_ 1429 PCM_AutoSarNMReserved4 1;
BA_ "U_P702_MY2021_Tx" SG_ 1429 PCM_AutoSarNMReserved4 1;
BA_ "U_T6_MCA_MY2020_Rx" SG_ 1429 PCM_AutoSarNMReserved4 1;
BA_ "U_P702_MY2021_Rx" SG_ 1429 PCM_AutoSarNMReserved4 1;
BA_ "GenSigStartValue" SG_ 1429 PCM_AutoSarNMReserved4 255;
BA_ "ContentDependant" SG_ 1429 PCM_AutoSarNMReserved4 1;
BA_ "GenSigStartValueInteger" SG_ 1429 PCM_AutoSarNMReserved4 255;
BA_ "U_T6_MCA_MY2020_Tx" SG_ 1429 PCM_AutoSarNMReserved3 1;
BA_ "U_P702_MY2021_Tx" SG_ 1429 PCM_AutoSarNMReserved3 1;
BA_ "U_T6_MCA_MY2020_Rx" SG_ 1429 PCM_AutoSarNMReserved3 1;
BA_ "U_P702_MY2021_Rx" SG_ 1429 PCM_AutoSarNMReserved3 1;
BA_ "GenSigStartValue" SG_ 1429 PCM_AutoSarNMReserved3 255;
BA_ "ContentDependant" SG_ 1429 PCM_AutoSarNMReserved3 1;
BA_ "GenSigStartValueInteger" SG_ 1429 PCM_AutoSarNMReserved3 255;
BA_ "U_T6_MCA_MY2020_Tx" SG_ 1429 PCM_AutoSarNMReserved2 1;
BA_ "U_P702_MY2021_Tx" SG_ 1429 PCM_AutoSarNMReserved2 1;
BA_ "U_T6_MCA_MY2020_Rx" SG_ 1429 PCM_AutoSarNMReserved2 1;
BA_ "U_P702_MY2021_Rx" SG_ 1429 PCM_AutoSarNMReserved2 1;
BA_ "GenSigStartValue" SG_ 1429 PCM_AutoSarNMReserved2 255;
BA_ "ContentDependant" SG_ 1429 PCM_AutoSarNMReserved2 1;
BA_ "GenSigStartValueInteger" SG_ 1429 PCM_AutoSarNMReserved2 255;
BA_ "U_T6_MCA_MY2020_Tx" SG_ 1429 PCM_AutoSarNMReserved1 1;
BA_ "U_P702_MY2021_Tx" SG_ 1429 PCM_AutoSarNMReserved1 1;
BA_ "U_T6_MCA_MY2020_Rx" SG_ 1429 PCM_AutoSarNMReserved1 1;
BA_ "U_P702_MY2021_Rx" SG_ 1429 PCM_AutoSarNMReserved1 1;
BA_ "GenSigStartValue" SG_ 1429 PCM_AutoSarNMReserved1 255;
BA_ "ContentDependant" SG_ 1429 PCM_AutoSarNMReserved1 1;
BA_ "GenSigStartValueInteger" SG_ 1429 PCM_AutoSarNMReserved1 255;
BA_ "U_T6_MCA_MY2020_Tx" SG_ 1429 PCM_AutoSarNMNodeId 1;
BA_ "U_P702_MY2021_Tx" SG_ 1429 PCM_AutoSarNMNodeId 1;
BA_ "U_T6_MCA_MY2020_Rx" SG_ 1429 PCM_AutoSarNMNodeId 1;
BA_ "U_P702_MY2021_Rx" SG_ 1429 PCM_AutoSarNMNodeId 1;
BA_ "GenSigStartValue" SG_ 1429 PCM_AutoSarNMNodeId 149;
BA_ "ContentDependant" SG_ 1429 PCM_AutoSarNMNodeId 1;
BA_ "GenSigStartValueInteger" SG_ 1429 PCM_AutoSarNMNodeId 149;
BA_ "U_T6_MCA_MY2020_Tx" SG_ 1429 PCM_AutoSarNMControl 1;
BA_ "U_P702_MY2021_Tx" SG_ 1429 PCM_AutoSarNMControl 1;
BA_ "U_T6_MCA_MY2020_Rx" SG_ 1429 PCM_AutoSarNMControl 1;
BA_ "U_P702_MY2021_Rx" SG_ 1429 PCM_AutoSarNMControl 1;
BA_ "ContentDependant" SG_ 1429 PCM_AutoSarNMControl 1;
BA_ "GenSigSendType" SG_ 1100 EngExhMdeQuiet_D2_Stat 3;
BA_ "U_P702_MY2021_Tx" SG_ 1100 HvacCmprLim_D_Stat 1;
BA_ "U_T6_MCA_MY2020_Tx" SG_ 1100 HvacCmprLim_D_Stat 1;
BA_ "U_T6_MCA_MY2020_Tx" SG_ 1100 WakeAlarm1_T_Rq 1;
BA_ "U_P702_MY2021_Tx" SG_ 1100 WakeAlarm1_T_Rq 1;
BA_ "GenSigStartValue" SG_ 1100 WakeAlarm1_T_Rq 32767;
BA_ "GenSigStartValueInteger" SG_ 1100 WakeAlarm1_T_Rq 32767;
BA_ "U_T6_MCA_MY2020_Tx" SG_ 1100 WakeAlarm1_B_Typ 1;
BA_ "U_P702_MY2021_Tx" SG_ 1100 WakeAlarm1_B_Typ 1;
BA_ "GenSigSendType" SG_ 1100 WakeAlarm1_B_Typ 3;
BA_ "WakeupSignal" SG_ 1100 WakeAlarm1_B_Typ 1;
BA_ "U_T6_MCA_MY2020_Tx" SG_ 1100 Veh_V_DsplyTrailCtlSet 1;
BA_ "U_P702_MY2021_Tx" SG_ 1100 Veh_V_DsplyTrailCtlSet 1;
BA_ "GenSigSendType" SG_ 1100 Veh_V_DsplyTrailCtlSet 3;
BA_ "U_T6_MCA_MY2020_Tx" SG_ 1100 TrailCtlPt_B_Falt 1;
BA_ "U_P702_MY2021_Tx" SG_ 1100 TrailCtlPt_B_Falt 1;
BA_ "U_P702_MY2021_Rx" SG_ 1100 TrailCtlPt_B_Falt 1;
BA_ "GenSigSendType" SG_ 1100 TrailCtlPt_B_Falt 3;
BA_ "U_P702_MY2021_Tx" SG_ 1100 AutoTowAllw_D_StatMnu 1;
BA_ "GenSigSendType" SG_ 1100 AutoTowAllw_D_StatMnu 3;
BA_ "U_P702_MY2021_Tx" SG_ 1100 AutoTowActv_B_Stat 1;
BA_ "GenSigSendType" SG_ 1100 AutoTowActv_B_Stat 3;
BA_ "U_T6_MCA_MY2020_Tx" SG_ 1100 GrossTrainWeight_M_Est 1;
BA_ "U_P702_MY2021_Tx" SG_ 1100 GrossTrainWeight_M_Est 1;
BA_ "U_T6_MCA_MY2020_Rx" SG_ 1100 GrossTrainWeight_M_Est 1;
BA_ "U_P702_MY2021_Rx" SG_ 1100 GrossTrainWeight_M_Est 1;
BA_ "GenSigStartValue" SG_ 1100 GrossTrainWeight_M_Est 254;
BA_ "GenSigStartValueInteger" SG_ 1100 GrossTrainWeight_M_Est 254;
VAL_ 1047 TrlrAidSetup_D2_Stat 7 "NotUsed_2" 6 "NotUsed_1" 5 "SetupAcquisitionSuccess" 4 "TbaTadMonitor" 3 "SetupStartAcquisition" 2 "SetupPrepForAcquisition" 1 "TbaActive" 0 "Null" ;
VAL_ 1047 TrlrAidEnbl_D2_Stat 7 "NotUsed_1" 6 "TbaActiveExpertActive" 5 "TbaActiveExpertAvail" 4 "TbaOffTrgActive" 3 "TbaOffTrgSetup" 2 "TbaSetup" 1 "TbaActive" 0 "Inactive" ;
VAL_ 1047 TrlrAidMsgTxt_D2_Rq 63 "Message63" 62 "Message62" 61 "Message61" 60 "Message60" 55 "Message55" 50 "Message50" 45 "Message45" 40 "Message40" 35 "Message35" 31 "Message31" 30 "Message30" 29 "Message29" 28 "Message28" 27 "Message27" 26 "Message26" 25 "Message25" 24 "Message24" 23 "Message23" 22 "Message22" 21 "Message21" 20 "Message20" 19 "Message19" 18 "Message18" 17 "Message17" 16 "Message16" 15 "Message15" 14 "Message14" 13 "Message13" 12 "Message12" 11 "Message11" 10 "Message10" 9 "Message9" 8 "Message8" 7 "Message7" 6 "Message6" 5 "Message5" 4 "Message4" 3 "Message3" 2 "Message2" 1 "Message1" 0 "NoMessage" ;
VAL_ 1047 EsaOn_B_Stat 1 "On" 0 "Off" ;
VAL_ 1047 SelDrvMdeSte_D_Stat 0 "NotAvailable" 1 "Available" 2 "TemporarilyNotAvailable" 3 "Faulty" ;
VAL_ 972 LatCtlSte_D_Stat 7 "NotUsed3" 6 "NotUsed2" 5 "NotUsed1" 4 "Denied" 3 "RampOut" 2 "ContLatControlInProgress" 1 "Available" 0 "Unavailable" ;
VAL_ 972 LatCtlLim_D_Stat 3 "LimitWithDriverActive" 2 "LimitReached" 1 "LimitClose" 0 "LimitNotReached" ;
VAL_ 972 LatCtlCpblty_D_Stat 3 "Faulty" 2 "ExtendedModeAvailable" 1 "LimitedModeAvailable" 0 "NoModeAvailable" ;
VAL_ 972 LsmcBrkDecelEnbl_D_Rq 3 "NotUsed2" 2 "NotUsed1" 1 "On" 0 "Off" ;
VAL_ 972 TjaHandsOnCnfdnc_B_Est 1 "High_Confidence" 0 "Low_Confidence" ;
VAL_ 972 LaHandsOff_B_Actl 1 "Hands_Off" 0 "Hands_On" ;
VAL_ 972 LaActDeny_B_Actl 1 "LA_Denied" 0 "LA_Not_Denied" ;
VAL_ 972 LaActAvail_D_Actl 3 "LKA_LCA_LDW_Avail" 2 "LCA_LKA_Avail_LDW_Suppress" 1 "LCA_LKA_Suppress_LDW_Avail" 0 "LCA_LKA_LDW_Suppress" ;
VAL_ 130 TrlrHitchLamp_D_Rqst 1 "On" 0 "Off" ;
VAL_ 130 VehVTrlrAid_B_Rq 1 "Request" 0 "NoRequest" ;
VAL_ 130 DrvSteActv_B_Stat 1 "Active" 0 "Inactive" ;
VAL_ 130 DrvSte_Tq_Actl 255 "Invalid" 254 "Unknown" ;
VAL_ 130 SteMdule_D_Stat 7 "NotUsed" 6 "EPAS_Failure3" 5 "EPAS_Failure2" 4 "System_Failure" 3 "EPAS_Shutdown" 2 "Normal_Op_Full_Assist" 1 "Normal_Op_Limited_Assist" 0 "EPAS_Initialization" ;
VAL_ 130 SteMdule_U_Meas 255 "Invalid" ;
VAL_ 130 SteMdule_I_Est 4095 "Invalid" ;
VAL_ 130 EPAS_Failure 3 "SERVICE_POWER_STEERING_NOW" 2 "SERVICE_POWER_STEERING" 1 "POWER_STRG_ASSIST_FAULT" 0 "EPAS_OK_NO_MESSAGE" ;
VAL_ 130 SteeringColumnTorque 255 "Invalid" 254 "Unknown" ;
VAL_ 130 SAPPAngleControlStat6 1 "RequestedAngleNotReached" 0 "RequestedAngleCanBeReached" ;
VAL_ 130 SAPPAngleControlStat5 1 "StrgColTorqueExceed_EAROn" 0 "ExternalSigContentOKforEAC" ;
VAL_ 130 SAPPAngleControlStat4 1 "SpeedLimitExceededEAROn" 0 "ExternalSigContentOKforEAC" ;
VAL_ 130 SAPPAngleControlStat3 1 "EARactiveNoReverseEngage" 0 "ExternalSigContentOKforEAC" ;
VAL_ 130 SAPPAngleControlStat2 1 "Rel_ExtSteeringAngleReqx" 0 "NoRel_ExtSteeringAngleReqx" ;
VAL_ 130 SAPPAngleControlStat1 3 "Fault" 2 "Active" 1 "Open" 0 "Closed" ;
VAL_ 126 StePw_B_Rq 1 "Yes" 0 "No" ;
VAL_ 126 StePinRelInit_An_Sns 65535 "Faulty" 65534 "NoDataExists" ;
VAL_ 126 StePinCompAnEst_D_Qf 3 "OK" 2 "Degraded" 1 "No_Data_Exists" 0 "Faulty" ;
VAL_ 1200 BrkHold_D_Stat 7 "NotUsed_3" 6 "NotUsed_2" 5 "NotUsed_1" 4 "HeldSecondary" 3 "HeldSecure" 2 "Held" 1 "Inactive" 0 "Off" ;
VAL_ 1200 HsaTrnAout_Tq_Rq 65535 "Fault" 65534 "Unknown" ;
VAL_ 1200 BrkBstrVac_P_Actl 127 "Invalid" ;
VAL_ 1200 YawStabilityIndex 511 "Fault" 510 "NoDataExists" ;
VAL_ 1200 BrkTot_Tq_RqDrv 8191 "Fault" ;
VAL_ 1200 HsaStat_D_Dsply 7 "NotUsed3" 6 "NotUsed2" 5 "NotUsed1" 4 "NotAvailable" 3 "SlowReleaseWithChime" 2 "SlowReleaseWithoutChime" 1 "Active" 0 "Inactive" ;
VAL_ 1102 SelDrvMdePos12_D_Stat 31 "Faulty" 30 "SelDrvMde31" 29 "SelDrvMde30" 28 "SelDrvMde29" 27 "SelDrvMde28" 26 "SelDrvMde27" 25 "SelDrvMde26" 24 "SelDrvMde25" 23 "SelDrvMde24" 22 "SelDrvMde23" 21 "SelDrvMde22" 20 "SelDrvMde21" 19 "SelDrvMde20" 18 "SelDrvMde19" 17 "SelDrvMde18" 16 "SelDrvMde17" 15 "SelDrvMde16" 14 "SelDrvMde15" 13 "SelDrvMde14" 12 "SelDrvMde13" 11 "SelDrvMde12" 10 "SelDrvMde11" 9 "SelDrvMde10" 8 "SelDrvMde09" 7 "SelDrvMde08" 6 "SelDrvMde07" 5 "SelDrvMde06" 4 "SelDrvMde05" 3 "SelDrvMde04" 2 "SelDrvMde03" 1 "SelDrvMde02" 0 "SelDrvMde01" ;
VAL_ 1102 SelDrvMdePos11_D_Stat 31 "Faulty" 30 "SelDrvMde31" 29 "SelDrvMde30" 28 "SelDrvMde29" 27 "SelDrvMde28" 26 "SelDrvMde27" 25 "SelDrvMde26" 24 "SelDrvMde25" 23 "SelDrvMde24" 22 "SelDrvMde23" 21 "SelDrvMde22" 20 "SelDrvMde21" 19 "SelDrvMde20" 18 "SelDrvMde19" 17 "SelDrvMde18" 16 "SelDrvMde17" 15 "SelDrvMde16" 14 "SelDrvMde15" 13 "SelDrvMde14" 12 "SelDrvMde13" 11 "SelDrvMde12" 10 "SelDrvMde11" 9 "SelDrvMde10" 8 "SelDrvMde09" 7 "SelDrvMde08" 6 "SelDrvMde07" 5 "SelDrvMde06" 4 "SelDrvMde05" 3 "SelDrvMde04" 2 "SelDrvMde03" 1 "SelDrvMde02" 0 "SelDrvMde01" ;
VAL_ 1102 SelDrvMdePos10_D_Stat 31 "Faulty" 30 "SelDrvMde31" 29 "SelDrvMde30" 28 "SelDrvMde29" 27 "SelDrvMde28" 26 "SelDrvMde27" 25 "SelDrvMde26" 24 "SelDrvMde25" 23 "SelDrvMde24" 22 "SelDrvMde23" 21 "SelDrvMde22" 20 "SelDrvMde21" 19 "SelDrvMde20" 18 "SelDrvMde19" 17 "SelDrvMde18" 16 "SelDrvMde17" 15 "SelDrvMde16" 14 "SelDrvMde15" 13 "SelDrvMde14" 12 "SelDrvMde13" 11 "SelDrvMde12" 10 "SelDrvMde11" 9 "SelDrvMde10" 8 "SelDrvMde09" 7 "SelDrvMde08" 6 "SelDrvMde07" 5 "SelDrvMde06" 4 "SelDrvMde05" 3 "SelDrvMde04" 2 "SelDrvMde03" 1 "SelDrvMde02" 0 "SelDrvMde01" ;
VAL_ 1102 SelDrvMdePos09_D_Stat 31 "Faulty" 30 "SelDrvMde31" 29 "SelDrvMde30" 28 "SelDrvMde29" 27 "SelDrvMde28" 26 "SelDrvMde27" 25 "SelDrvMde26" 24 "SelDrvMde25" 23 "SelDrvMde24" 22 "SelDrvMde23" 21 "SelDrvMde22" 20 "SelDrvMde21" 19 "SelDrvMde20" 18 "SelDrvMde19" 17 "SelDrvMde18" 16 "SelDrvMde17" 15 "SelDrvMde16" 14 "SelDrvMde15" 13 "SelDrvMde14" 12 "SelDrvMde13" 11 "SelDrvMde12" 10 "SelDrvMde11" 9 "SelDrvMde10" 8 "SelDrvMde09" 7 "SelDrvMde08" 6 "SelDrvMde07" 5 "SelDrvMde06" 4 "SelDrvMde05" 3 "SelDrvMde04" 2 "SelDrvMde03" 1 "SelDrvMde02" 0 "SelDrvMde01" ;
VAL_ 1102 SelDrvMdePos08_D_Stat 31 "Faulty" 30 "SelDrvMde31" 29 "SelDrvMde30" 28 "SelDrvMde29" 27 "SelDrvMde28" 26 "SelDrvMde27" 25 "SelDrvMde26" 24 "SelDrvMde25" 23 "SelDrvMde24" 22 "SelDrvMde23" 21 "SelDrvMde22" 20 "SelDrvMde21" 19 "SelDrvMde20" 18 "SelDrvMde19" 17 "SelDrvMde18" 16 "SelDrvMde17" 15 "SelDrvMde16" 14 "SelDrvMde15" 13 "SelDrvMde14" 12 "SelDrvMde13" 11 "SelDrvMde12" 10 "SelDrvMde11" 9 "SelDrvMde10" 8 "SelDrvMde09" 7 "SelDrvMde08" 6 "SelDrvMde07" 5 "SelDrvMde06" 4 "SelDrvMde05" 3 "SelDrvMde04" 2 "SelDrvMde03" 1 "SelDrvMde02" 0 "SelDrvMde01" ;
VAL_ 1102 SelDrvMdePos07_D_Stat 31 "Faulty" 30 "SelDrvMde31" 29 "SelDrvMde30" 28 "SelDrvMde29" 27 "SelDrvMde28" 26 "SelDrvMde27" 25 "SelDrvMde26" 24 "SelDrvMde25" 23 "SelDrvMde24" 22 "SelDrvMde23" 21 "SelDrvMde22" 20 "SelDrvMde21" 19 "SelDrvMde20" 18 "SelDrvMde19" 17 "SelDrvMde18" 16 "SelDrvMde17" 15 "SelDrvMde16" 14 "SelDrvMde15" 13 "SelDrvMde14" 12 "SelDrvMde13" 11 "SelDrvMde12" 10 "SelDrvMde11" 9 "SelDrvMde10" 8 "SelDrvMde09" 7 "SelDrvMde08" 6 "SelDrvMde07" 5 "SelDrvMde06" 4 "SelDrvMde05" 3 "SelDrvMde04" 2 "SelDrvMde03" 1 "SelDrvMde02" 0 "SelDrvMde01" ;
VAL_ 1102 SelDrvMdePos06_D_Stat 31 "Faulty" 30 "SelDrvMde31" 29 "SelDrvMde30" 28 "SelDrvMde29" 27 "SelDrvMde28" 26 "SelDrvMde27" 25 "SelDrvMde26" 24 "SelDrvMde25" 23 "SelDrvMde24" 22 "SelDrvMde23" 21 "SelDrvMde22" 20 "SelDrvMde21" 19 "SelDrvMde20" 18 "SelDrvMde19" 17 "SelDrvMde18" 16 "SelDrvMde17" 15 "SelDrvMde16" 14 "SelDrvMde15" 13 "SelDrvMde14" 12 "SelDrvMde13" 11 "SelDrvMde12" 10 "SelDrvMde11" 9 "SelDrvMde10" 8 "SelDrvMde09" 7 "SelDrvMde08" 6 "SelDrvMde07" 5 "SelDrvMde06" 4 "SelDrvMde05" 3 "SelDrvMde04" 2 "SelDrvMde03" 1 "SelDrvMde02" 0 "SelDrvMde01" ;
VAL_ 1102 SelDrvMdePos05_D_Stat 31 "Faulty" 30 "SelDrvMde31" 29 "SelDrvMde30" 28 "SelDrvMde29" 27 "SelDrvMde28" 26 "SelDrvMde27" 25 "SelDrvMde26" 24 "SelDrvMde25" 23 "SelDrvMde24" 22 "SelDrvMde23" 21 "SelDrvMde22" 20 "SelDrvMde21" 19 "SelDrvMde20" 18 "SelDrvMde19" 17 "SelDrvMde18" 16 "SelDrvMde17" 15 "SelDrvMde16" 14 "SelDrvMde15" 13 "SelDrvMde14" 12 "SelDrvMde13" 11 "SelDrvMde12" 10 "SelDrvMde11" 9 "SelDrvMde10" 8 "SelDrvMde09" 7 "SelDrvMde08" 6 "SelDrvMde07" 5 "SelDrvMde06" 4 "SelDrvMde05" 3 "SelDrvMde04" 2 "SelDrvMde03" 1 "SelDrvMde02" 0 "SelDrvMde01" ;
VAL_ 1102 SelDrvMdePos04_D_Stat 31 "Faulty" 30 "SelDrvMde31" 29 "SelDrvMde30" 28 "SelDrvMde29" 27 "SelDrvMde28" 26 "SelDrvMde27" 25 "SelDrvMde26" 24 "SelDrvMde25" 23 "SelDrvMde24" 22 "SelDrvMde23" 21 "SelDrvMde22" 20 "SelDrvMde21" 19 "SelDrvMde20" 18 "SelDrvMde19" 17 "SelDrvMde18" 16 "SelDrvMde17" 15 "SelDrvMde16" 14 "SelDrvMde15" 13 "SelDrvMde14" 12 "SelDrvMde13" 11 "SelDrvMde12" 10 "SelDrvMde11" 9 "SelDrvMde10" 8 "SelDrvMde09" 7 "SelDrvMde08" 6 "SelDrvMde07" 5 "SelDrvMde06" 4 "SelDrvMde05" 3 "SelDrvMde04" 2 "SelDrvMde03" 1 "SelDrvMde02" 0 "SelDrvMde01" ;
VAL_ 1102 SelDrvMdePos03_D_Stat 31 "Faulty" 30 "SelDrvMde31" 29 "SelDrvMde30" 28 "SelDrvMde29" 27 "SelDrvMde28" 26 "SelDrvMde27" 25 "SelDrvMde26" 24 "SelDrvMde25" 23 "SelDrvMde24" 22 "SelDrvMde23" 21 "SelDrvMde22" 20 "SelDrvMde21" 19 "SelDrvMde20" 18 "SelDrvMde19" 17 "SelDrvMde18" 16 "SelDrvMde17" 15 "SelDrvMde16" 14 "SelDrvMde15" 13 "SelDrvMde14" 12 "SelDrvMde13" 11 "SelDrvMde12" 10 "SelDrvMde11" 9 "SelDrvMde10" 8 "SelDrvMde09" 7 "SelDrvMde08" 6 "SelDrvMde07" 5 "SelDrvMde06" 4 "SelDrvMde05" 3 "SelDrvMde04" 2 "SelDrvMde03" 1 "SelDrvMde02" 0 "SelDrvMde01" ;
VAL_ 1102 SelDrvMdePos02_D_Stat 31 "Faulty" 30 "SelDrvMde31" 29 "SelDrvMde30" 28 "SelDrvMde29" 27 "SelDrvMde28" 26 "SelDrvMde27" 25 "SelDrvMde26" 24 "SelDrvMde25" 23 "SelDrvMde24" 22 "SelDrvMde23" 21 "SelDrvMde22" 20 "SelDrvMde21" 19 "SelDrvMde20" 18 "SelDrvMde19" 17 "SelDrvMde18" 16 "SelDrvMde17" 15 "SelDrvMde16" 14 "SelDrvMde15" 13 "SelDrvMde14" 12 "SelDrvMde13" 11 "SelDrvMde12" 10 "SelDrvMde11" 9 "SelDrvMde10" 8 "SelDrvMde09" 7 "SelDrvMde08" 6 "SelDrvMde07" 5 "SelDrvMde06" 4 "SelDrvMde05" 3 "SelDrvMde04" 2 "SelDrvMde03" 1 "SelDrvMde02" 0 "SelDrvMde01" ;
VAL_ 1102 SelDrvMdePos01_D_Stat 31 "Faulty" 30 "SelDrvMde31" 29 "SelDrvMde30" 28 "SelDrvMde29" 27 "SelDrvMde28" 26 "SelDrvMde27" 25 "SelDrvMde26" 24 "SelDrvMde25" 23 "SelDrvMde24" 22 "SelDrvMde23" 21 "SelDrvMde22" 20 "SelDrvMde21" 19 "SelDrvMde20" 18 "SelDrvMde19" 17 "SelDrvMde18" 16 "SelDrvMde17" 15 "SelDrvMde16" 14 "SelDrvMde15" 13 "SelDrvMde14" 12 "SelDrvMde13" 11 "SelDrvMde12" 10 "SelDrvMde11" 9 "SelDrvMde10" 8 "SelDrvMde09" 7 "SelDrvMde08" 6 "SelDrvMde07" 5 "SelDrvMde06" 4 "SelDrvMde05" 3 "SelDrvMde04" 2 "SelDrvMde03" 1 "SelDrvMde02" 0 "SelDrvMde01" ;
VAL_ 1056 SelDrvMdeHmi03_D_Rq 31 "Faulty" 30 "SelDrvMde31" 29 "SelDrvMde30" 28 "SelDrvMde29" 27 "SelDrvMde28" 26 "SelDrvMde27" 25 "SelDrvMde26" 24 "SelDrvMde25" 23 "SelDrvMde24" 22 "SelDrvMde23" 21 "SelDrvMde22" 20 "SelDrvMde21" 19 "SelDrvMde20" 18 "SelDrvMde19" 17 "SelDrvMde18" 16 "SelDrvMde17" 15 "SelDrvMde16" 14 "SelDrvMde15" 13 "SelDrvMde14" 12 "SelDrvMde13" 11 "SelDrvMde12" 10 "SelDrvMde11" 9 "SelDrvMde10" 8 "SelDrvMde09" 7 "SelDrvMde08" 6 "SelDrvMde07" 5 "SelDrvMde06" 4 "SelDrvMde05" 3 "SelDrvMde04" 2 "SelDrvMde03" 1 "SelDrvMde02" 0 "SelDrvMde01" ;
VAL_ 1056 AutoEpbMsgTxt_D_Rq 7 "Message7" 6 "Message6" 5 "Message5" 4 "Message4" 3 "Message3" 2 "Message2" 1 "Message1" 0 "NoMessage" ;
VAL_ 1056 AutoEpbDsply_D_Stat 3 "NotUsed" 2 "GreyedOut" 1 "Available" 0 "NotAvailable" ;
VAL_ 1056 AutoEpbButtnOn_B_Stat 1 "On" 0 "Off" ;
VAL_ 1056 SelDrvMdePos12_B_Avail 1 "Available" 0 "NotAvailable" ;
VAL_ 1056 SelDrvMdePos11_B_Avail 1 "Available" 0 "NotAvailable" ;
VAL_ 1056 SelDrvMdePos10_B_Avail 1 "Available" 0 "NotAvailable" ;
VAL_ 1056 SelDrvMdePos09_B_Avail 1 "Available" 0 "NotAvailable" ;
VAL_ 1056 SelDrvMdePos08_B_Avail 1 "Available" 0 "NotAvailable" ;
VAL_ 1056 SelDrvMdePos07_B_Avail 1 "Available" 0 "NotAvailable" ;
VAL_ 1056 SelDrvMdePos06_B_Avail 1 "Available" 0 "NotAvailable" ;
VAL_ 1056 SelDrvMdePos05_B_Avail 1 "Available" 0 "NotAvailable" ;
VAL_ 1056 SelDrvMdePos04_B_Avail 1 "Available" 0 "NotAvailable" ;
VAL_ 1056 SelDrvMdePos03_B_Avail 1 "Available" 0 "NotAvailable" ;
VAL_ 1056 SelDrvMdePos02_B_Avail 1 "Available" 0 "NotAvailable" ;
VAL_ 1056 SelDrvMdePos01_B_Avail 1 "Available" 0 "NotAvailable" ;
VAL_ 1056 ActvDrvMde_D2_Stat 31 "Faulty" 30 "SelDrvMde31" 29 "SelDrvMde30" 28 "SelDrvMde29" 27 "SelDrvMde28" 26 "SelDrvMde27" 25 "SelDrvMde26" 24 "SelDrvMde25" 23 "SelDrvMde24" 22 "SelDrvMde23" 21 "SelDrvMde22" 20 "SelDrvMde21" 19 "SelDrvMde20" 18 "SelDrvMde19" 17 "SelDrvMde18" 16 "SelDrvMde17" 15 "SelDrvMde16" 14 "SelDrvMde15" 13 "SelDrvMde14" 12 "SelDrvMde13" 11 "SelDrvMde12" 10 "SelDrvMde11" 9 "SelDrvMde10" 8 "SelDrvMde09" 7 "SelDrvMde08" 6 "SelDrvMde07" 5 "SelDrvMde06" 4 "SelDrvMde05" 3 "SelDrvMde04" 2 "SelDrvMde03" 1 "SelDrvMde02" 0 "SelDrvMde01" ;
VAL_ 1056 SelDrvMde_D2_Rq 31 "Faulty" 30 "SelDrvMde31" 29 "SelDrvMde30" 28 "SelDrvMde29" 27 "SelDrvMde28" 26 "SelDrvMde27" 25 "SelDrvMde26" 24 "SelDrvMde25" 23 "SelDrvMde24" 22 "SelDrvMde23" 21 "SelDrvMde22" 20 "SelDrvMde21" 19 "SelDrvMde20" 18 "SelDrvMde19" 17 "SelDrvMde18" 16 "SelDrvMde17" 15 "SelDrvMde16" 14 "SelDrvMde15" 13 "SelDrvMde14" 12 "SelDrvMde13" 11 "SelDrvMde12" 10 "SelDrvMde11" 9 "SelDrvMde10" 8 "SelDrvMde09" 7 "SelDrvMde08" 6 "SelDrvMde07" 5 "SelDrvMde06" 4 "SelDrvMde05" 3 "SelDrvMde04" 2 "SelDrvMde03" 1 "SelDrvMde02" 0 "SelDrvMde01" ;
VAL_ 1056 SelDrvMdePt_D_Rq 31 "Faulty" 30 "NotUsed15" 29 "NotUsed14" 28 "NotUsed13" 27 "NotUsed12" 26 "NotUsed11" 25 "NotUsed10" 24 "NotUsed9" 23 "NotUsed8" 22 "NotUsed7" 21 "CustomMode" 20 "NotUsed5" 19 "NotUsed4" 18 "EvLaterChargerMode" 17 "EvNowMode" 16 "DragMode" 15 "HighSpeedDesertMode_Baja" 14 "SportAdaptiveMode" 13 "NotAvailable_13" 12 "NotAvailable_12" 11 "NotAvailable_11" 10 "NotAvailable_10" 9 "RockCrawlMode" 8 "MudRutsMode" 7 "SandMode" 6 "EconomyMode" 5 "GrassGravelSnow" 4 "NotAvailable_04" 3 "TowHaulMode" 2 "NotAvailable_02" 1 "SportMode" 0 "NormalMode" ;
VAL_ 1056 SelDrvMdeMsgTxt_D_Rq 15 "Message15" 14 "Message14" 13 "Message13" 12 "Message12" 11 "Message11" 10 "Message10" 9 "Message9" 8 "Message8" 7 "Message7" 6 "Message6" 5 "Message5" 4 "Message4" 3 "Message3" 2 "Message2" 1 "Message1" 0 "NoMessage" ;
VAL_ 1056 SelDrvMde_D_Stat 3 "NotUsed" 2 "DriveModeChangeRequest" 1 "DriveModeChangeSelection" 0 "NoDriveModeChangeRequest" ;
VAL_ 1056 AwdMde_D_RqBrk 7 "Faulty" 6 "NotUsed2" 5 "NoRequest" 4 "Neutral" 3 "FourByFourLow" 2 "FourByFourHigh" 1 "FourByFourAuto" 0 "FourByTwo" ;
VAL_ 1054 TrailOnePdlTqLm_B_Actl 1 "Yes" 0 "No" ;
VAL_ 1054 SelDrvMdeChassis3_D_Rq 31 "Faulty" 30 "NotUsed17" 29 "NotUsed16" 28 "NotUsed15" 27 "NotUsed14" 26 "NotUsed13" 25 "NotUsed12" 24 "NotUsed11" 23 "NotUsed10" 22 "NotUsed9" 21 "NotUsed8" 20 "NotUsed7" 19 "NotUsed6" 18 "NotUsed5" 17 "NotUsed4" 16 "OnePedalDrive" 15 "DragMode" 14 "RoughRoadMode" 13 "TrackMode" 12 "HighSpeedDesertMode" 11 "TowHaulMode" 10 "RockCrawlMode" 9 "SandMode" 8 "MudAndRutsMode" 7 "LowMuMode" 6 "ComfortAdaptiveMode" 5 "ComfortMode" 4 "SportAdaptiveMode" 3 "SportMode" 2 "EconomyMode" 1 "NormalAdaptiveMode" 0 "NormalMode" ;
VAL_ 1054 AirDamUp_B_RqBrk 1 "Up" 0 "NoRequest" ;
VAL_ 1054 RbaBrk_D_Stat 3 "Denied" 2 "Active" 1 "Open" 0 "Closed" ;
VAL_ 1054 SelDrvMdeChassis2_D_Rq 31 "Faulty" 30 "NotUsed17" 29 "NotUsed16" 28 "NotUsed15" 27 "NotUsed14" 26 "NotUsed13" 25 "NotUsed12" 24 "NotUsed11" 23 "NotUsed10" 22 "NotUsed9" 21 "NotUsed8" 20 "NotUsed7" 19 "NotUsed6" 18 "NotUsed5" 17 "NotUsed4" 16 "NotUsed3" 15 "NotUsed2" 14 "RoughRoadMode" 13 "TrackMode" 12 "HighSpeedDesertMode" 11 "TowHaulMode" 10 "RockCrawlMode" 9 "SandMode" 8 "MudAndRutsMode" 7 "LowMuMode" 6 "ComfortAdaptiveMode" 5 "ComfortMode" 4 "SportAdaptiveMode" 3 "SportMode" 2 "EconomyMode" 1 "NormalAdaptiveMode" 0 "NormalMode" ;
VAL_ 1054 TrailCtl_D_Stat 7 "Faulty" 6 "DescentOnly" 5 "EnabledDeny" 4 "StandbyOverThreshold" 3 "StandbyOverride" 2 "Active" 1 "EnabledDescent" 0 "Off" ;
VAL_ 1054 TrailCtlMsgTxt_D_Rq 15 "Message15" 14 "Message14" 13 "Message13" 12 "Message12" 11 "Message11" 10 "Message10" 9 "Message9" 8 "Message8" 7 "Message7" 6 "Message6" 5 "Message5" 4 "Message4" 3 "Message3" 2 "Message2" 1 "Message1" 0 "NoMessage" ;
VAL_ 1054 BrkBstrVac_D_Stat 3 "NotUsed" 2 "BoosterVacEstimator" 1 "BoosterVacSensor" 0 "NoBoosterVacuumMonitor" ;
VAL_ 1054 DrvSlipCtlOffLamp_D_Rq 3 "Fast_Flash" 2 "Slow_Flash" 1 "On" 0 "Off" ;
VAL_ 1054 DrvSlipCtlMdeMsg_D_Rq 31 "Message31" 30 "Message30" 29 "Message29" 28 "Message28" 27 "Message27" 26 "Message26" 25 "Message25" 24 "Message24" 23 "Message23" 22 "Message22" 21 "Message21" 20 "Message20" 19 "Message19" 18 "Message18" 17 "Message17" 16 "Message16" 15 "Message15" 14 "Message14" 13 "Message13" 12 "Message12" 11 "Message11" 10 "Message10" 9 "Message9" 8 "Message8" 7 "Message7" 6 "Message6" 5 "Message5" 4 "Message4" 3 "Message3" 2 "Message2" 1 "Message1" 0 "NoMessage" ;
VAL_ 1054 AutoHoldMsgTxt_D_Rq 15 "Message15" 14 "Message14" 13 "Message13" 12 "Message12" 11 "Message11" 10 "Message10" 9 "Message9" 8 "Message8" 7 "Message7" 6 "Message6" 5 "Message5" 4 "Message4" 3 "Message3" 2 "Message2" 1 "Message1" 0 "NoMessage" ;
VAL_ 1054 CtaBrk_D_Stat 3 "Denied" 2 "Active" 1 "Open" 0 "Closed" ;
VAL_ 1054 SelDrvMdeAwd_D_Rq 31 "Faulty" 30 "NotUsed_17" 29 "NotUsed_16" 28 "NotUsed_15" 27 "NotUsed_14" 26 "NotUsed_13" 25 "NotUsed_12" 24 "NotUsed_11" 23 "NotUsed_10" 22 "NotUsed_9" 21 "NotUsed_8" 20 "CustomMode" 19 "NotUsed_6" 18 "NotUsed_5" 17 "EvLaterChargeMode" 16 "EvNowMode" 15 "TrackMode" 14 "RoughRoadMode" 13 "NotAvailable" 12 "HighSpeedDesertMode_Baja" 11 "SportAdaptiveMode" 10 "RockCrawlMode" 9 "MudRutsMode" 8 "SandMode" 7 "EconomyMode" 6 "GrassGravelSnow" 5 "TowHaulMode" 4 "SportMode" 3 "Normal_4L" 2 "Normal_4A" 1 "Normal_2H" 0 "NormalMode" ;
VAL_ 1054 AutoHoldSwMde_B_Ind 1 "On" 0 "Off" ;
VAL_ 1054 AutoHoldMde_D_Ind 3 "Indication_3" 2 "Indication_2" 1 "Indication_1" 0 "Off" ;
VAL_ 1054 SelDrvMdeChassis_D_Rq 31 "Faulty" 30 "NotUsed17" 29 "NotUsed16" 28 "NotUsed15" 27 "NotUsed14" 26 "NotUsed13" 25 "NotUsed12" 24 "NotUsed11" 23 "NotUsed10" 22 "NotUsed9" 21 "NotUsed8" 20 "NotUsed7" 19 "NotUsed6" 18 "NotUsed5" 17 "NotUsed4" 16 "NotUsed3" 15 "NotUsed2" 14 "NotUsed1" 13 "TrackMode" 12 "HighSpeedDesertMode" 11 "TowHaulMode" 10 "RockCrawlMode" 9 "SandMode" 8 "MudAndRutsMode" 7 "LowMuMode" 6 "ComfortAdaptiveMode" 5 "ComfortMode" 4 "SportAdaptiveMode" 3 "SportMode" 2 "EconomyMode" 1 "NormalAdaptiveMode" 0 "NormalMode" ;
VAL_ 1054 ApaBrk_D_Stat 3 "Denied" 2 "Active" 1 "Open" 0 "Closed" ;
VAL_ 1046 HsaMde_D_Mem 3 "Undefined" 2 "Manual" 1 "Automatic" 0 "Off" ;
VAL_ 1046 BrkBstrVac_B_Rq 1 "Yes" 0 "No" ;
VAL_ 1046 HdcMde_D_Actl 7 "Fault" 6 "Temporarily_Unavailable" 5 "NotEnabled_WrongGearSel" 4 "NotEnabled_SpdLimitExceed" 3 "Active_Braking" 2 "Not_Active_Braking" 1 "Off" 0 "Undefined" ;
VAL_ 1046 RearDiffLck_Tq2_RqMx 4095 "Faulty" ;
VAL_ 1046 TRLR_SWAY_EVNT_IN_PROG 1 "Yes" 0 "No" ;
VAL_ 1046 TRLR_SWAY_CONFIG_STAT 1 "On" 0 "Off" ;
VAL_ 1046 TCMode 1 "Active" 0 "Inactive" ;
VAL_ 1046 DrvSlipCtlLamp_D_Rq 3 "Fast_Flash" 2 "Slow_Flash" 1 "On" 0 "Off" ;
VAL_ 1046 Abs_B_Falt 1 "Yes" 0 "No" ;
VAL_ 1046 DrvSlipCtlMde_D_Ind 3 "App_Specific_Off_Mode_3" 2 "App_Specific_Off_Mode_2" 1 "App_Specific_Off_Mode_1" 0 "Default_Mode" ;
VAL_ 1046 DrvAntiLckLamp_D_Rq 3 "Fast_Flash" 2 "Slow_Flash" 1 "On" 0 "Off" ;
VAL_ 1046 StabCtlBrk_B_Avail 1 "Yes" 0 "No" ;
VAL_ 1046 DrvHdcWarnInfo_D_Rq 3 "Undefined" 2 "Lamp_On_Continuously" 1 "Lamp_Flashing" 0 "Lamp_Off_Continuously" ;
VAL_ 1046 DrvHdcMsg_D_Rq 7 "Undefined" 6 "Speed_too_High" 5 "Temporarily_Unavailable" 4 "System_Fault" 3 "Select_Gear" 2 "Off" 1 "On" 0 "No_Message" ;
VAL_ 1046 DrvHdcLampInfo_D_Rq 3 "Fast_Flash" 2 "Slow_Flash" 1 "On" 0 "Off" ;
VAL_ 1046 BpedMove_D_Actl 3 "Unknown" 2 "DriverApplyingBrakePedal" 1 "NoAutonomousBrkPdlMovement" 0 "AutonomousBrkPedalMove" ;
VAL_ 1046 ChimeBrk_B_Rq 1 "Yes" 0 "No" ;
VAL_ 1046 BrkLamp_B_Rq 1 "Yes" 0 "No" ;
VAL_ 1046 HILL_DESC_MC 7 "Fault_Detected" 6 "Cooling_Down" 5 "Abort_Apply_Brakes" 4 "Active" 3 "Disabled" 2 "Enabled" 1 "Off_Road" 0 "Normal" ;
VAL_ 1046 RearDiffElckrOpen_B_Rq 1 "Yes" 0 "No" ;
VAL_ 1045 VehStab_D_Stat 15 "Faulty" 14 "No_Data_Exists" 13 "NotUsed6" 12 "NotUsed5" 11 "NotUsed4" 10 "NotUsed3" 9 "NotUsed2" 8 "NotUsed1" 7 "High_SSRA_no_OS" 6 "Straight" 5 "Post_Oversteer" 4 "Post_Transition" 3 "Countersteer" 2 "Understeer" 1 "Oversteer" 0 "Linear" ;
VAL_ 1045 BrkFluidLvl_D_Stat 3 "Invalid" 2 "Unknown" 1 "Low" 0 "OK" ;
VAL_ 1045 LsmcBrkDecel_D_Stat 7 "NotUsed_3" 6 "NotUsed_2" 5 "NotUsed_1" 4 "Denied" 3 "FaultDegraded" 2 "FaultExt" 1 "On" 0 "Off" ;
VAL_ 1045 VehYawNonLin_W_Rq 4095 "Fault" 4094 "Unknown" ;
VAL_ 1045 VehYawLin_W_Rq 4095 "Fault" 4094 "Unknown" ;
VAL_ 1045 VehVActlBrk_D_Qf 3 "OK" 2 "Not_Within_Specifications" 1 "No_Data_Exists" 0 "Faulty" ;
VAL_ 1044 StePinOffst_An_Est 65535 "Faulty" 65534 "NoDataExists" ;
VAL_ 1044 StePinOffst_D_Stat 3 "FineOffset" 2 "CoarseOffset" 1 "StoredOffset" 0 "OffsetNotCalculated" ;
VAL_ 1042 VehRol_An_Dsply 127 "Faulty" 126 "NoDataExists" ;
VAL_ 1042 VehPtch_An_Dsply 127 "Faulty" 126 "NoDataExists" ;
VAL_ 535 WhlRr_W_Meas 32767 "Fault" 32766 "Unknown" ;
VAL_ 535 WhlRl_W_Meas 32767 "Fault" 32766 "Unknown" ;
VAL_ 535 WhlFr_W_Meas 32767 "Fault" 32766 "Unknown" ;
VAL_ 535 WhlFl_W_Meas 32767 "Fault" 32766 "Unknown" ;
VAL_ 534 WhlDirRr_D_Actl 3 "Faulty" 2 "NoDataExists" 1 "Backward" 0 "Forward" ;
VAL_ 534 WhlDirRl_D_Actl 3 "Faulty" 2 "NoDataExists" 1 "Backward" 0 "Forward" ;
VAL_ 534 WhlDirFr_D_Actl 3 "Faulty" 2 "NoDataExists" 1 "Backward" 0 "Forward" ;
VAL_ 534 WhlDirFl_D_Actl 3 "Faulty" 2 "NoDataExists" 1 "Backward" 0 "Forward" ;
VAL_ 532 RgenTqFalt_B_Actl 1 "Fault" 0 "No_Fault" ;
VAL_ 532 RgenBrkDynoMde_B_Actl 1 "TwoWheelDyno" 0 "NormalOperation" ;
VAL_ 531 VehStop_D_Stat 3 "Faulty" 2 "NoDataExists" 1 "Yes" 0 "No" ;
VAL_ 531 TracCtlPtActv_B_Actl 1 "Active" 0 "Inactive" ;
VAL_ 531 LscmbbMntr_B_Err 1 "DisplayMessage" 0 "NoMessage" ;
VAL_ 531 LscmbbBrkDis_B_Actl 1 "Yes" 0 "No" ;
VAL_ 531 LscmbbDeny_B_ActlBrk 1 "Yes" 0 "No" ;
VAL_ 531 PrkBrkYwLamp_D_Rq 3 "Fast_Flash" 2 "Slow_Flash" 1 "On" 0 "Off" ;
VAL_ 531 PrkBrkRedLamp_D_Rq 3 "Fast_Flash" 2 "Slow_Flash" 1 "On" 0 "Off" ;
VAL_ 531 LscmbbBrkDecel_B_Actl 1 "Yes" 0 "No" ;
VAL_ 531 AbsActv_B_Actl 1 "Yes" 0 "No" ;
VAL_ 531 StabCtlBrkActv_B_Actl 1 "Yes" 0 "No" ;
VAL_ 531 CmbbBrkPrchg_B_Actl 1 "Yes" 0 "No" ;
VAL_ 531 CmbbBrkDecel_B_Actl 1 "Yes" 0 "No" ;
VAL_ 531 CmbbBaSensInc_B_Actl 1 "Yes" 0 "No" ;
VAL_ 531 AccBrkWarm_B_Actl 1 "Yes" 0 "No" ;
VAL_ 531 AccBrkTotTqMn_B_Actl 1 "Yes" 0 "No" ;
VAL_ 531 AccBrkPrchgActv_B_Actl 1 "Yes" 0 "No" ;
VAL_ 531 AccBrkDis_B_Actl 1 "Yes" 0 "No" ;
VAL_ 531 AccBrkDeny_B_Actl 1 "Yes" 0 "No" ;
VAL_ 531 AccBrkActv_B_Actl 1 "Yes" 0 "No" ;
VAL_ 531 PrplDrgCtlActv_B_Actl 1 "Active" 0 "Inactive" ;
VAL_ 531 LscmbbBaSensInc_B_Actl 1 "Yes" 0 "No" ;
VAL_ 531 CmbbBrkDis_B_Actl 1 "Yes" 0 "No" ;
VAL_ 531 CmbbDeny_B_ActlBrk 1 "Yes" 0 "No" ;
VAL_ 531 CcDis_B_Cmd 1 "Yes" 0 "No" ;
VAL_ 531 VehLongOvrGnd_A_Est 1023 "Fault" 1022 "Unknown" ;
VAL_ 531 LscmbBrkPrchg_B_Actl 1 "Active" 0 "Inactive" ;
VAL_ 531 AccStopActv_B_ActlBrk 1 "Yes" 0 "No" ;
VAL_ 531 AccDis_B_ActlEpb 1 "Yes" 0 "No" ;
VAL_ 531 PrkBrkMsgTxt_D_Rq 15 "Message15" 14 "Message14" 13 "Message13" 12 "Message12" 11 "Message11" 10 "Message10" 9 "Message9" 8 "Message8" 7 "Message7" 6 "Message6" 5 "Message5" 4 "Message4" 3 "Message3" 2 "Message2" 1 "Message1" 0 "No_Message" ;
VAL_ 531 PrkBrkStatus 7 "GeneralFault_MaintenceMode" 6 "ECD_by_Brake_ECU_Active" 5 "EPB_Limphome_Active" 4 "Rear_Caliper_Open" 3 "RWU_By_EPB_Active" 2 "Rear_Caliper_Transition" 1 "Rear_Caliper_Closed" 0 "Not_Supported" ;
VAL_ 125 VehRolComp_W_Actl 4094 "NoDataExists" 4095 "Fault" ;
VAL_ 125 VehVertComp_A_Actl 1022 "NoDataExists" 1023 "Fault" ;
VAL_ 125 BrkTot_Tq_RqArb 8191 "Fault" 8190 "Unknown" ;
VAL_ 125 BrkTot_Tq_Actl 8191 "Fault" 8190 "Unknown" ;
VAL_ 125 HsaStat_D_Actl 7 "Faulty" 6 "FaultyWithDriverIndication" 5 "SlowRelease" 4 "FastRelease" 3 "ActiveBrakePedalReleased" 2 "ActiveBrakePedalPressed" 1 "FindingGradient" 0 "Inactive" ;
VAL_ 119 VehTrvlDir_D_Stat 7 "Faulty" 6 "NoDataExists" 5 "NotUsed2" 4 "NotUsed1" 3 "Reverse" 2 "LikelyReverse" 1 "Forward" 0 "LikelyForward" ;
VAL_ 119 VehOverGnd_V_Est 65535 "Invalid" 65534 "Unknown" ;
VAL_ 119 VehLongComp_A_Actl 1023 "Fault" 1022 "NoDataExists" ;
VAL_ 119 VehLatComp_A_Actl 1023 "Fault" 1022 "NoDataExists" ;
VAL_ 119 VehYawComp_W_Actl 4095 "Fault" 4094 "NoDataExists" ;
VAL_ 118 BrkCtrFnd_B_Stat 1 "Yes" 0 "No" ;
VAL_ 118 DrvSte_D_Stat 15 "NotUsed10" 14 "NotUsed9" 13 "NotUsed8" 12 "NotUsed7" 11 "NotUsed6" 10 "NotUsed5" 9 "NotUsed4" 8 "NotUsed3" 7 "NotUsed2" 6 "NotUsed1" 5 "Request_Active" 4 "Ignition_Off" 3 "DSR_in_Normal_Idle_Mode" 2 "EPAS_Comm_Disturbed" 1 "DSR_Request_Not_Applicable" 0 "DSR_Deactivated" ;
VAL_ 118 DrvSte_Tq_Rq 255 "Invalid" 254 "Unknown" ;
VAL_ 118 EmgcyBrkLamp_D_Rq 3 "NotUsed" 2 "Active_at_standstill" 1 "Active_at_speed" 0 "Inactive" ;
VAL_ 118 StopLamp_B_RqBrk 1 "Active" 0 "Inactive" ;
VAL_ 73 immoSubTarget1Cmd_T1 7 "Unused3" 6 "Unused2" 5 "ECHO_TARGET1_IDBLOCK2" 4 "Unused1" 3 "RQST_TARGET1_IDBLOCK2" 2 "RQST_TARGET1_IDBLOCK1" 1 "RESPONSE" 0 "IDLE" ;
VAL_ 561 TrnMsgTxt2_D_Rq 7 "NotUsed3" 6 "NotUsed2" 5 "NotUsed1" 4 "TransTooHot_LoudChime" 3 "PressBrake_LoudChime" 2 "PressBrake_SoftChime" 1 "PressBrake_NoChime" 0 "NoText_NoChime" ;
VAL_ 561 TrnMsgTxt_D_Rq 15 "Message_15" 14 "Message_14" 13 "Message_13" 12 "Message_12" 11 "Message_11" 10 "Message_10" 9 "Message_9" 8 "Message_8" 7 "Message_7" 6 "Message_6" 5 "Message_5" 4 "Message_4" 3 "Message_3" 2 "Message_2" 1 "Message_1" 0 "NoMessage" ;
VAL_ 330 TrnAout_W_ActlUnfilt 32767 "Fault" 32766 "Unknown" ;
VAL_ 1090 HybVehMde_D_ActlMntr 7 "Faulty" 6 "NoDataExists" 5 "NotUsed_2" 4 "NotUsed_1" 3 "Fuel" 2 "HybridElectric" 1 "AllElectric" 0 "Null" ;
VAL_ 1090 ChrgStat_D_ActlMntr 7 "Faulty" 6 "NoDataExists" 5 "NotUsed" 4 "ChargingCompleted" 3 "NotCharging" 2 "ChargingInDrivingState" 1 "ChargingInParkingState" 0 "Null" ;
VAL_ 1090 VehElRnge_L_Dsply 4094 "NoDataExists" 4095 "Fault" ;
VAL_ 870 EngMdeMsgTxt_D_Rq 7 "NotUsed_3" 6 "NotUsed_2" 5 "NotUsed_1" 4 "Charge" 3 "GlowingCharge" 2 "Hybrid" 1 "Ev" 0 "NoMessage" ;
VAL_ 870 RngPerChrgInst_L_Dsply 4095 "Faulty" 4094 "NoDataExists" ;
VAL_ 869 PwrFlowTxt_D_Dsply 15 "NotUsed7" 14 "NotUsed6" 13 "NotUsed5" 12 "NotUsed4" 11 "Disply_Rgen_Chrg_Txt" 10 "Disp_Fast_Charge_Txt" 9 "Disp_Fast_Charge_Cmplt_Txt" 8 "Disp_Charge_Cmplt_Txt" 7 "Disp_Remote_Start_Txt" 6 "Disp_Eng_Drv_Txt" 5 "Disp_Elec_Drv_Txt" 4 "Disp_Idle_with_Chrg_Txt" 3 "Disp_Idle_Txt" 2 "Disp_Charg_HV_Batt_Txt" 1 "Disp_Hyb_Drive_Txt" 0 "No_Text" ;
VAL_ 869 EngOnMsg2_D_Dsply 14 "_0xE_to_1F_NotUsed" 12 "Battery_Temperature" 11 "Hill_Decent_Control" 10 "Fuel_Maintenance" 9 "Oil_Maintenance" 8 "Normal_Operation" 7 "Low_Gear" 6 "Batt_Charging" 5 "Engine_Cold" 4 "Neutral_Gear" 3 "Heater_Setting" 2 "High_Speed" 1 "Acceleration" 0 "No_Display" 13 "Drive_Mode_Selection" ;
VAL_ 869 EngOnMsg1_D_Dsply 14 "_0xE_to_1F_NotUsed" 12 "Battery_Temperature" 11 "Hill_Decent_Control" 10 "Fuel_Maintenance" 9 "Oil_Maintenance" 8 "Normal_Operation" 7 "Low_Gear" 6 "Batt_Charging" 5 "Engine_Cold" 4 "Neutral_Gear" 3 "Heater_Setting" 2 "High_Speed" 1 "Acceleration" 0 "No_Display" 13 "Drive_Mode_Selection" ;
VAL_ 869 FuelMaintMde_D_Dsply 3 "Feature_Not_Present" 2 "In_Fuel_Maint_Mode" 1 "Close_to_Fuel_Maint" 0 "OK" ;
VAL_ 869 EngActv_B_Dsply 1 "On" 0 "Off" ;
VAL_ 869 EffWhlThresOn_B_Dsply 1 "On" 0 "Off" ;
VAL_ 606 ElVehLaterMde_D_Stat 3 "NotUsed" 2 "Available" 1 "NotAvailable" 0 "Null" ;
VAL_ 606 ElVehNowMde_D_Stat 3 "NotUsed" 2 "Available" 1 "NotAvailable" 0 "Null" ;
VAL_ 374 GearEngag_D_Actl 7 "Undefined" 6 "Fwd_Clutch_Fully_Engaged" 5 "Neutral_Idle" 4 "Disengaged_to_Neutral_Idle" 3 "Disengaged_to_Neutral_Park" 2 "Engagement_in_Progress" 1 "InitializeFwdClutchEngagmt" 0 "Park_Neutral" ;
VAL_ 374 TrnRng_D_Rq 15 "Fault" 14 "Unknown_Position" 13 "NotUsed_2" 12 "NotUsed_1" 11 "Range6" 10 "Range5" 9 "Range4" 8 "Range3_M3_L3" 7 "Range2_M2_L2" 6 "Range1_M1_L1" 5 "Low" 4 "Sport_DriveSport_Mposition" 3 "Drive" 2 "Neutral" 1 "Reverse" 0 "Park" ;
VAL_ 374 TrnPrkSys_D_Actl 15 "Faulty" 14 "NotUsed_5" 13 "NotUsed_4" 12 "NotUsed_3" 11 "NotUsed_2" 10 "NotUsed_1" 9 "FrequencyError" 8 "OutOfRangeHigh" 7 "OutOfRangeLow" 6 "Override" 5 "OutOfPark" 4 "TransitionCloseToOutOfPark" 3 "AtNoSpring" 2 "TransitionCloseToPark" 1 "Park" 0 "NotKnown" ;
VAL_ 374 GearLvr_D_ActlDrv 15 "Fault" 14 "Unknown_Position" 13 "NotUsed_2" 12 "NotUsed_1" 11 "Range6" 10 "Range5" 9 "Range4" 8 "Range3_M3_L3" 7 "Range2_M2_L2" 6 "Range1_M1_L1" 5 "Low" 4 "Sport_DriveSport_Mposition" 3 "Drive" 2 "Neutral" 1 "Reverse" 0 "Park" ;
VAL_ 374 GearPos_D_Trg 15 "Unknown" 14 "Reverse" 13 "Undefined_5" 12 "Undefined_4" 11 "Undefined_3" 10 "Tenth" 9 "Ninth" 8 "Eighth" 7 "Seventh" 6 "Sixth" 5 "Fifth" 4 "Fourth" 3 "Third" 2 "Second" 1 "First" 0 "Neutral" ;
VAL_ 374 GearPos_D_Actl 15 "Unknown" 14 "Reverse" 13 "Undefined_5" 12 "Undefined_4" 11 "Undefined_3" 10 "Tenth" 9 "Ninth" 8 "Eighth" 7 "Seventh" 6 "Sixth" 5 "Fifth" 4 "Fourth" 3 "Third" 2 "Second" 1 "First" 0 "Neutral" ;
VAL_ 603 WhlDirAvgDrv_D_Actl 3 "Failed" 2 "Unknown" 1 "Backward" 0 "Forward" ;
VAL_ 603 PrplTqMnRgen_B_Actl 1 "Yes" 0 "No" ;
VAL_ 603 BattTracCnnct_D_Rq 3 "Undefined" 2 "Retain" 1 "Close" 0 "Open" ;
VAL_ 602 HtrnWarnLamp_B_Dsply 1 "On" 0 "Off" ;
VAL_ 602 PwPckTqRdy_B_Dsply 1 "On" 0 "Off" ;
VAL_ 1152 BattTracDiagClr_B_Stat 1 "On" 0 "Off" ;
VAL_ 1152 EngTeHi_B_Actl 1 "EngineTempHigh" 0 "Normal" ;
VAL_ 1152 DcdcOn_B_Rq 1 "On" 0 "Off" ;
VAL_ 1152 ULoBattSpprtSustn_B_Rq 1 "Active" 0 "Inactive" ;
VAL_ 1152 VehElEff_No_Avg 127 "Faulty" 126 "NoDataExists" ;
VAL_ 872 HybMdeStat_D_Dsply 7 "NotUsed2" 6 "EV_Charge" 5 "EV_Override" 4 "Forced_EV_Mode" 3 "Forced_Charge_Sustain_Mode" 2 "Auto_Charge_Sustain_Mode" 1 "Auto_Charge_Deplete_Mode" 0 "Null_State" ;
VAL_ 560 SelDrvMdeSwtch_D_Stat3 3 "Faulty" 2 "SwitchState2" 1 "SwitchState1" 0 "NotPressed" ;
VAL_ 560 TrnSrvcRqd_B_Rq 1 "On" 0 "Off" ;
VAL_ 560 TrnShifActv_B_Actl 1 "Active" 0 "Inactive" ;
VAL_ 560 GearLvrPos_D_Actl 15 "Fault" 14 "Unknown_Position" 13 "Undefined_Treat_as__Fault" 12 "Undefined_Treat_as_Fault" 11 "sixth" 10 "fifth" 9 "fourth" 8 "third" 7 "second" 6 "first" 5 "Low" 4 "Sport_DriveSport" 3 "Drive" 2 "Neutral" 1 "Reverse" 0 "Park" ;
VAL_ 560 GboxOil_Te_Actl 255 "Faulty" 254 "NoDataExists" ;
VAL_ 369 SeatWorkSrfc_B_Falt 1 "Active" 0 "Inactive" ;
VAL_ 369 TrnIpcDsplyRng2_D_Actl 15 "No_Range_Selected" 14 "Range_14" 13 "Range_13" 12 "Range_12" 11 "Range_11" 10 "Range_10" 9 "Range_9" 8 "Range_8" 7 "Range_7" 6 "Range_6" 5 "Range_5" 4 "Range_4" 3 "Range_3" 2 "Range_2" 1 "Range_1" 0 "NotUsed" ;
VAL_ 369 TrnIpcDsplyRng_D_Stat 3 "NotUsed" 2 "Flash" 1 "On" 0 "Blank_No_Display" ;
VAL_ 369 TrnIpcDsplyGear_D_Actl 15 "No_Gear_Selected" 14 "_14th_Gear" 13 "_13th_Gear" 12 "_12th_Gear" 11 "_11th_Gear" 10 "_10th_Gear" 9 "_9th_Gear" 8 "_8th_Gear" 7 "_7th_Gear" 6 "_6th_Gear" 5 "_5th_Gear" 4 "_4th_Gear" 3 "_3rd_Gear" 2 "_2nd_Gear" 1 "_1st_Gear" 0 "Neutral" ;
VAL_ 369 TrnIpcDsplyMde_D_Stat 3 "Reserved_Blank_No_Display" 2 "Flash" 1 "On" 0 "Blank_No_Display" ;
VAL_ 369 TrnIpcDsplyMde_D_Actl 7 "Manual_3" 6 "Manual_2" 5 "Manual_1_Low" 4 "Sport" 3 "Drive" 2 "Neutral" 1 "Reverse" 0 "Park" ;
VAL_ 369 TrnIpcDsplyGear_D_Stat 3 "Reserved_Blank_No_Display" 2 "Flash" 1 "On" 0 "Blank_No_Display" ;
VAL_ 92 TrnLvrV_D_Rq 3 "Full_Speed" 2 "Aggressive" 1 "Normal" 0 "Quiet" ;
VAL_ 92 TrnSbwSysHlth_D_Actl 3 "OK" 2 "Degraded" 1 "No_Data_Exists" 0 "Faulty" ;
VAL_ 92 TrnGearNtmAllow_B_Stat 1 "Yes" 0 "No" ;
VAL_ 92 TrnDtpCmd_D_Actl 7 "NotUsed4" 6 "NotUsed3" 5 "NotUsed2" 4 "Relatch" 3 "Deploy" 2 "Self_Test" 1 "No_Command" 0 "NotUsed1" ;
VAL_ 92 GearSelLck_D_Rq 3 "PreventionBlocker" 2 "Unlock" 1 "Lock" 0 "Null" ;
VAL_ 92 TrnValidGear_D_Cnfm 3 "Accept" 2 "Reject" 1 "Internal_Request" 0 "No_Command" ;
VAL_ 92 TrnNtrlTowCmd_D_Actl 3 "NotUsed" 2 "Neutral_Tow_Entry" 1 "Car_Wash_Mode" 0 "Normal_Mode" ;
VAL_ 92 TrnGearCmd_Pc_ActlPt 1023 "Fault" ;
VAL_ 92 TrnGear_D_RqPt 7 "Fault" 6 "NotUsed" 5 "Manual" 4 "Drive" 3 "Neutral" 2 "Reverse" 1 "Park" 0 "No_Gear" ;
VAL_ 92 TrnCmdState_B_Actl 1 "Yes" 0 "No" ;
VAL_ 92 PrkBrkActv_D_RqTrnGear 3 "NotUsed2" 2 "RequestParkBrakeEngage" 1 "NoRequest" 0 "NotUsed1" ;
VAL_ 92 TrnGearMsgTxt_D_Rq 31 "Message_31" 30 "Message_30" 29 "Message_29" 28 "Message_28" 27 "Message_27" 26 "Message_26" 25 "Message_25" 24 "Message_24" 23 "Message_23" 22 "Message_22" 21 "Message_21" 20 "Message_20" 19 "Message_19" 18 "Message_18" 17 "Message_17" 16 "Message_16" 15 "Message_15" 14 "Message_14" 13 "Message_13" 12 "Message_12" 11 "Message_11" 10 "Message_10" 9 "Message_9" 8 "Message_8" 7 "Message_7" 6 "Message_6" 5 "Message_5" 4 "Message_4" 3 "Message_3" 2 "Message_2" 1 "Message_1" 0 "NoMessage" ;
VAL_ 1087 DcacFaltMsgTxt_D2_Rq 63 "NotUsed_47" 17 "NotUsed_1" 16 "HevDerate" 15 "HvacOn" 14 "OvercurrentLP" 13 "EngineRun" 12 "Service" 11 "NotAvailable" 10 "PlugWarn" 9 "PlugWarnDrive" 8 "BreakerC" 7 "BreakerB" 6 "BreakerA" 5 "FuelLow" 4 "AcOnOutput" 3 "Temperature" 2 "Gfci" 1 "Overcurrent" 0 "Ok" ;
VAL_ 1087 StopStrtCstm_D_Stat 3 "Faulty" 2 "On" 1 "Off" 0 "NotAvailable" ;
VAL_ 1087 SelDrvMdeCstmPt_D_Stat 31 "Faulty" 30 "NotUsed15" 29 "NotUsed14" 28 "NotUsed13" 27 "NotUsed12" 26 "NotUsed11" 25 "NotUsed10" 24 "NotUsed9" 23 "NotUsed8" 22 "NotUsed7" 21 "CustomMode" 20 "TrackMode" 19 "OnePedalDrive" 18 "EvLaterChargerMode" 17 "EvNowMode" 16 "DragMode" 15 "HighSpeedDesertMode_Baja" 14 "SportAdaptiveMode" 13 "NotAvailable_13" 12 "NotAvailable_12" 11 "NotAvailable_11" 10 "NotAvailable_10" 9 "RockCrawlMode" 8 "MudRutsMode" 7 "SandMode" 6 "EconomyMode" 5 "GrassGravelSnow" 4 "NotAvailable_04" 3 "TowHaulMode" 2 "NotAvailable_02" 1 "SportMode" 0 "NormalMode" ;
VAL_ 1087 ClimtCool_D_RqPt 3 "NotUsed_2" 2 "NotUsed_1" 1 "On" 0 "Off" ;
VAL_ 1087 BtsiShifInhbt_B_RqPt 1 "Yes" 0 "No" ;
VAL_ 1087 BattRgenLoChrg_D_RqEng 3 "Disable" 2 "Retain" 1 "Closed" 0 "Open" ;
VAL_ 1087 AdasLcObtclAbrt_B_Stat 1 "Yes" 0 "No" ;
VAL_ 1087 BattRgenLoDChrg_D_RqEng 3 "Disable" 2 "Retain" 1 "Closed" 0 "Open" ;
VAL_ 1087 FapLcInhbt_B_Rq 1 "Yes" 0 "No" ;
VAL_ 1087 FapLcStopHold_B_Rq 1 "Yes" 0 "No" ;
VAL_ 1087 FapLcPrchgBrk_B_Rq 1 "Yes" 0 "No" ;
VAL_ 1087 FapLcObstcl_B_Stat 1 "Yes" 0 "No" ;
VAL_ 1087 FapLcMaxGrdInhbt_B_Stat 1 "Yes" 0 "No" ;
VAL_ 1087 FapLcMaxGrdAbrt_B_Stat 1 "Yes" 0 "No" ;
VAL_ 1087 FapLcActv_B_Stat 1 "Yes" 0 "No" ;
VAL_ 332 UreaLvlQlty_D_RqDsply 7 "NotUsed_5" 6 "NotUsed_4" 5 "NotUsed_3" 4 "NotUsed_2" 3 "NotUsed_1" 2 "FlashChime" 1 "On" 0 "Off" ;
VAL_ 332 UreaLvlTxtWarn_D_Rq 15 "NotUsed_4" 14 "NotUsed_3" 13 "NotUsed_2" 12 "NotUsed_1" 11 "System_Error" 10 "Engine_Idled_See_Manual" 9 "Engine_Idled_Upon_Refuel" 8 "Speed_Limited_To_XX_mph" 7 "XXmph_Max_Upon_Restart" 6 "Speed_Limited_To_YY_mph" 5 "YYmph_Max_Upon_Restart" 4 "SpdLimtd_YYmph_In_XXmiles" 3 "ExFlRange_XXMiles_ScndWarn" 2 "Exh_Fluid_Range_XX_Miles" 1 "Exh_Fluid_Under_Half_Full" 0 "Exh_Fluid_Over_Half_Full" ;
VAL_ 332 UreaQltySysWarn_D_Rq 7 "Undefined" 6 "ZZ_Overrides" 5 "EngineIdled" 4 "Engine_Idle_Upon_Refuel" 3 "SPEED_LIMITED_to_YY_mph" 2 "YY_MPH_MAX_UPON_Restart" 1 "CONTAMINATED_ExhFluid" 0 "NoQualityProblem" ;
VAL_ 332 DieslPrtcWarn_D_Rq 15 "NotUsed_4" 14 "NotUsed_3" 13 "NotUsed_2" 12 "NotUsed_1" 11 "OCR_ExhFilterClean_Stopped" 10 "OCR_ExhFilterCleaned" 9 "RgnOff_AtLimit" 8 "RgnOff_OverLoaded" 7 "RgnOff_Loaded" 6 "Exhaust_Filter_Full" 5 "DPF_OverLimit" 4 "DPF_AtLimit" 3 "ExhFilter_Drive_Completed" 2 "Cleaning_Exhaust_Filter" 1 "DPF_OverLoaded" 0 "DPF_Normal_Operation" ;
VAL_ 332 UreaQltyFlg_B_RqDsply 1 "True" 0 "False" ;
VAL_ 332 UreaQltySys_D_RqDsply 7 "Undefined" 6 "ZZ_Overrides" 5 "EngineIdled" 4 "Engine_Idle_Upon_Refuel" 3 "SPEED_LIMITED_to_YY_mph" 2 "YY_MPH_MAX_UPON_Restart" 1 "CONTAMINATED_ExhFluid" 0 "NoQualityProblem" ;
VAL_ 332 UreaLvlTxt_D_RqDsply 15 "NotUsed_4" 14 "NotUsed_3" 13 "NotUsed_2" 12 "NotUsed_1" 11 "System_Error" 10 "Engine_Idled_See_Manual" 9 "Engine_Idled_Upon_Refuel" 8 "Speed_Limited_To_XX_mph" 7 "XXmph_Max_Upon_Restart" 6 "Speed_Limited_To_YY_mph" 5 "YYmph_Max_Upon_Restart" 4 "SpdLimtd_YYmph_In_XXmiles" 3 "ExFlRange_XXMiles_ScndWarn" 2 "Exh_Fluid_Range_XX_Miles" 1 "Exh_Fluid_Under_Half_Full" 0 "Exh_Fluid_Over_Half_Full" ;
VAL_ 1100 EngExhMdeQuiet_D2_Stat 7 "Faulty" 6 "NotUsed_2" 5 "NotUsed_1" 4 "Track" 3 "Sport" 2 "Normal" 1 "Stealth" 0 "Null" ;
VAL_ 1100 HvacCmprLim_D_Stat 7 "NotUsed_2" 6 "NotUsed_1" 5 "CompressorHeadPressure" 4 "AvailableTorque" 3 "PedalPosition" 2 "RPM" 1 "ECT" 0 "NoLimit" ;
VAL_ 1100 WakeAlarm1_B_Typ 1 "CanAndEcuDriveCircuit" 0 "CanOnly" ;
VAL_ 1100 Veh_V_DsplyTrailCtlSet 63 "Faulty" ;
VAL_ 1100 TrailCtlPt_B_Falt 1 "Fault" 0 "No_Fault" ;
VAL_ 1100 AutoTowAllw_D_StatMnu 3 "TowHaulCommandedOn" 2 "AutoTowHaulEnabled" 1 "AutoTowHaulDisabled" 0 "NoSelection" ;
VAL_ 1100 AutoTowActv_B_Stat 1 "Yes" 0 "No" ;
VAL_ 1100 GrossTrainWeight_M_Est 255 "Faulty" 254 "NoDataExists" ;
